VERSION "HNNBNNNYNNNNNNNNNNNNNNNNNNNNNNNNNNNNNNNNNN/4/%%%/4/'%**4NNN///"

NS_ :

BS_:

BU_: BAP_Tester Booster_AMP DSP_SKODA Gateway_PQ35 Gateway_PQ46 GSM_Pager Kompassmodul MDI Radio_2DIN Radio_Modul Radio_SKODA Rearview RNS_300_NF RNS_MFD2 RNS_midline SDARS_Tuner Sprachbedienung Standheizung Tastatur Telematik_Basis TV_hybrid UHV_High UHV_low UHV_NAR UHV_Premium UHV_UMTS

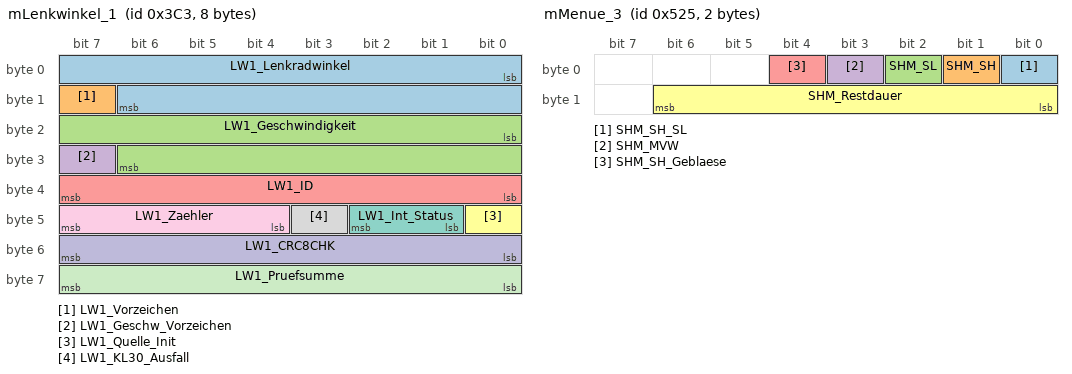
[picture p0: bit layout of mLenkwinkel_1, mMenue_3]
BO_ 963 mLenkwinkel_1: 8 Gateway_PQ35
 SG_ LW1_Lenkradwinkel : 0|15@1+ (0.04375,0) [0|1433.55625] "Unit_DegreOfArc"  Rearview
 SG_ LW1_Vorzeichen : 15|1@1+ (1,0) [0|1] ""  Rearview
 SG_ LW1_Geschwindigkeit : 16|15@1+ (0.04375,0) [0|1433.55625] "Unit_DegreOfArcPerSecond"  Rearview
 SG_ LW1_Geschw_Vorzeichen : 31|1@1+ (1,0) [0|1] ""  Rearview
 SG_ LW1_ID : 32|8@1+ (1,0) [0|255] ""  Rearview
 SG_ LW1_Quelle_Init : 40|1@1+ (1,0) [0|1] ""  Rearview
 SG_ LW1_Int_Status : 41|2@1+ (1,0) [0|3] ""  Rearview
 SG_ LW1_KL30_Ausfall : 43|1@1+ (1,0) [0|1] ""  Rearview
 SG_ LW1_Zaehler : 44|4@1+ (1,0) [0|15] ""  Rearview
 SG_ LW1_CRC8CHK : 48|8@1+ (1,0) [0|255] "" Vector__XXX
 SG_ LW1_Pruefsumme : 56|8@1+ (1,0) [0|255] ""  Rearview

BO_ 1329 mLicht_1_alt: 4 Gateway_PQ35
 SG_ LIA_Standlicht : 0|1@1+ (1,0) [0|1] "" Vector__XXX
 SG_ LIA_Abblendlicht : 1|1@1+ (1,0) [0|1] "" Vector__XXX
 SG_ LIA_Fernlicht : 2|1@1+ (1,0) [0|1] "" Vector__XXX
 SG_ LIA_Nebellicht : 3|1@1+ (1,0) [0|1] "" Vector__XXX
 SG_ LIA_Nebelschluss : 4|1@1+ (1,0) [0|1] "" Vector__XXX
 SG_ LIA_Rueckfahrlicht : 5|1@1+ (1,0) [0|1] ""  Radio_Modul,Rearview,RNS_midline
 SG_ LIA_Parklicht_links : 6|1@1+ (1,0) [0|1] "" Vector__XXX
 SG_ LIA_Parklicht_rechts : 7|1@1+ (1,0) [0|1] "" Vector__XXX
 SG_ LIA_Blk_links : 8|1@1+ (1,0) [0|1] ""  Radio_2DIN,Radio_SKODA
 SG_ LIA_Blk_rechts : 9|1@1+ (1,0) [0|1] ""  Radio_2DIN,Radio_SKODA
 SG_ LIA_Anhaenger : 10|1@1+ (1,0) [0|1] "" Vector__XXX
 SG_ LIA_Warnblink : 11|1@1+ (1,0) [0|1] "" Vector__XXX
 SG_ LIA_BLK_Frequenz : 12|1@1+ (1,0) [0|1] "" Vector__XXX
 SG_ LIA_AFL_Schalter : 13|1@1+ (1,0) [0|1] "" Vector__XXX
 SG_ LIA_Bremslicht : 14|1@1+ (1,0) [0|1] "" Vector__XXX
 SG_ LIA_Tagesfahrlicht : 15|1@1+ (1,0) [0|1] "" Vector__XXX
 SG_ LIA_Blk_L_Kontrolle : 16|1@1+ (1,0) [0|1] "" Vector__XXX
 SG_ LIA_Blk_R_Kontrolle : 17|1@1+ (1,0) [0|1] "" Vector__XXX
 SG_ LIA_Kurv_Licht : 18|1@1+ (1,0) [0|1] "" Vector__XXX
 SG_ LIA_Warnblk_Status : 19|1@1+ (1,0) [0|1] "" Vector__XXX
 SG_ LIA_Zaehler : 20|4@1+ (1,0) [0|15] "" Vector__XXX
 SG_ LIA_Pruefsumme : 24|8@1+ (1,0) [0|255] "" Vector__XXX

BO_ 705 mLSM_1: 6 Gateway_PQ35
 SG_ LS1_Blk_links : 0|1@1+ (1,0) [0|1] ""  Radio_2DIN,Radio_Modul,Rearview
 SG_ LS1_Blk_rechts : 1|1@1+ (1,0) [0|1] ""  Radio_2DIN,Radio_Modul,Rearview
 SG_ LS1_Lichthupe : 2|1@1+ (1,0) [0|1] "" Vector__XXX
 SG_ LS1_Fernlicht : 3|1@1+ (1,0) [0|1] "" Vector__XXX
 SG_ LS1_Parklicht_links : 5|1@1+ (1,0) [0|1] "" Vector__XXX
 SG_ LS1_Parklicht_rechts : 6|1@1+ (1,0) [0|1] "" Vector__XXX
 SG_ LS1_Signalhorn : 7|1@1+ (1,0) [0|1] "" Vector__XXX
 SG_ LS1_Tipwischen : 8|1@1+ (1,0) [0|1] "" Vector__XXX
 SG_ LS1_Intervall : 9|1@1+ (1,0) [0|1] "" Vector__XXX
 SG_ LS1_WischenStufe_1 : 10|1@1+ (1,0) [0|1] "" Vector__XXX
 SG_ LS1_WischenStufe_2 : 11|1@1+ (1,0) [0|1] "" Vector__XXX
 SG_ LS1_Frontwaschen : 12|1@1+ (1,0) [0|1] "" Vector__XXX
 SG_ LS1_Bew_Frontwaschen : 13|1@1+ (1,0) [0|1] "" Vector__XXX
 SG_ LS1_Heckintervall : 14|1@1+ (1,0) [0|1] "" Vector__XXX
 SG_ LS1_Heckwaschen : 15|1@1+ (1,0) [0|1] "" Vector__XXX
 SG_ LS1_Intervallstufen : 16|4@1+ (1,0) [0|15] "" Vector__XXX
 SG_ LS1_BC_Down_Cursor : 20|1@1+ (1,0) [0|1] "" Vector__XXX
 SG_ LS1_BC_Up_Cursor : 21|1@1+ (1,0) [0|1] "" Vector__XXX
 SG_ LS1_BC_Reset : 22|1@1+ (1,0) [0|1] "" Vector__XXX
 SG_ LS1_KD_Fehler : 23|1@1+ (1,0) [0|1] "" Vector__XXX
 SG_ LS1_LSY_oben : 24|1@1+ (1,0) [0|1] "" Vector__XXX
 SG_ LS1_LSY_unten : 25|1@1+ (1,0) [0|1] "" Vector__XXX
 SG_ LS1_LSZ_vor : 26|1@1+ (1,0) [0|1] "" Vector__XXX
 SG_ LS1_LSZ_zurueck : 27|1@1+ (1,0) [0|1] "" Vector__XXX
 SG_ LS1_ELV_enable : 28|1@1+ (1,0) [0|1] "" Vector__XXX
 SG_ LS1_def_ELV_Enable : 29|1@1+ (1,0) [0|1] "" Vector__XXX
 SG_ LS1_Easy_Entry_LS : 30|1@1+ (1,0) [0|1] "" Vector__XXX
 SG_ LS1_LHeizung_aktiv : 31|1@1+ (1,0) [0|1] "" Vector__XXX
 SG_ LS1_Winterstellung : 32|1@1+ (1,0) [0|1] "" Vector__XXX
 SG_ LS1_MFL_vorhanden : 33|1@1+ (1,0) [0|1] ""  Kompassmodul,Radio_2DIN,Radio_Modul,Radio_SKODA,RNS_300_NF,RNS_MFD2,RNS_midline,Sprachbedienung,Standheizung,Telematik_Basis,UHV_low,UHV_NAR,UHV_Premium,UHV_UMTS
 SG_ LS1_MFA_vorhanden : 34|1@1+ (1,0) [0|1] ""  Kompassmodul,Radio_2DIN,Radio_Modul,Radio_SKODA,RNS_300_NF,RNS_MFD2,RNS_midline,Sprachbedienung,Standheizung,Telematik_Basis,UHV_low,UHV_NAR,UHV_Premium,UHV_UMTS
 SG_ LS1_MFA_Tasten : 35|1@1+ (1,0) [0|1] ""  Sprachbedienung,Standheizung,Telematik_Basis,UHV_low,UHV_NAR,UHV_Premium,UHV_UMTS
 SG_ LS1_def_P_Verriegelt : 36|1@1+ (1,0) [0|1] "" Vector__XXX
 SG_ LS1_MFL_Typ : 37|1@1+ (1,0) [0|1] ""  Kompassmodul,Radio_2DIN,Radio_SKODA,RNS_MFD2,Standheizung,UHV_low,UHV_NAR,UHV_Premium,UHV_UMTS
 SG_ LS1_Servicestellung : 38|1@1+ (1,0) [0|1] "" Vector__XXX
 SG_ LS1_P_verriegelt : 39|1@1+ (1,0) [0|1] "" Vector__XXX
 SG_ LS1_FAS_Taster : 40|1@1+ (1,0) [0|1] "" Vector__XXX
 SG_ LS1_Fehler_FAS_Taster : 41|1@1+ (1,0) [0|1] "" Vector__XXX
 SG_ LS1_Fehler_Vibration : 42|1@1+ (1,0) [0|1] "" Vector__XXX

BO_ 1371 mMDI_1: 1 MDI
 SG_ MD1_MDI_on : 0|1@1+ (1,0) [0|1] ""  Radio_Modul,RNS_300_NF,RNS_midline
 SG_ MD1_MDI_Error_flag : 7|1@1+ (1,0) [0|1] ""  Gateway_PQ35,Gateway_PQ46

BO_ 1317 mMenue_3: 2 Gateway_PQ35
 SG_ SHM_SH_SL : 0|1@1+ (1,0) [0|1] ""  Standheizung
 SG_ SHM_SH : 1|1@1+ (1,0) [0|1] ""  Standheizung
 SG_ SHM_SL : 2|1@1+ (1,0) [0|1] ""  Standheizung
 SG_ SHM_MVW : 3|1@1+ (1,0) [0|1] ""  Standheizung
 SG_ SHM_SH_Geblaese : 4|1@1+ (1,0) [0|1] "" Vector__XXX
 SG_ SHM_Restdauer : 8|7@1+ (1,0) [0|126] "Unit_Minut"  Standheizung

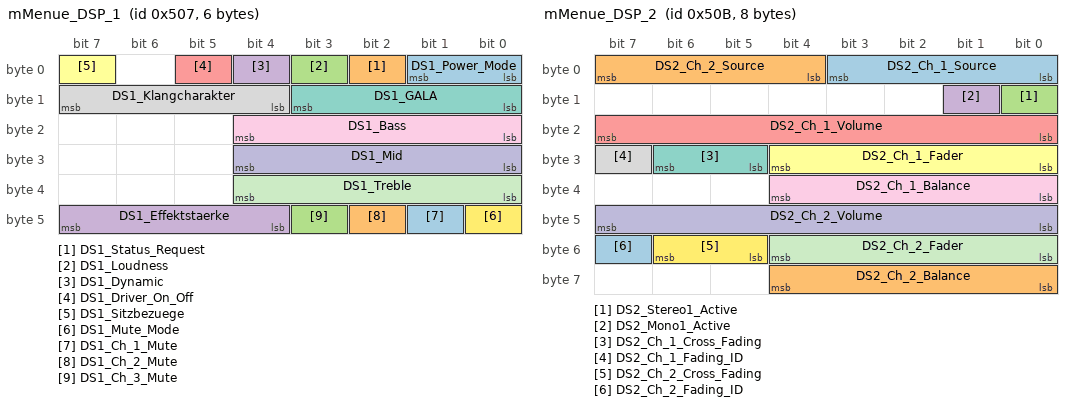
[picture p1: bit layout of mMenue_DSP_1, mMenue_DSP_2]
BO_ 1287 mMenue_DSP_1: 6 Radio_Modul
 SG_ DS1_Power_Mode : 0|2@1+ (1,0) [0|3] ""  DSP_SKODA
 SG_ DS1_Status_Request : 2|1@1+ (1,0) [0|1] ""  DSP_SKODA
 SG_ DS1_Loudness : 3|1@1+ (1,0) [0|1] ""  DSP_SKODA
 SG_ DS1_Dynamic : 4|1@1+ (1,0) [0|1] ""  DSP_SKODA
 SG_ DS1_Driver_On_Off : 5|1@1+ (1,0) [0|1] ""  DSP_SKODA
 SG_ DS1_Sitzbezuege : 7|1@1+ (1,0) [0|1] ""  DSP_SKODA
 SG_ DS1_GALA : 8|4@1+ (1,0) [0|15] ""  DSP_SKODA
 SG_ DS1_Klangcharakter : 12|4@1+ (1,0) [0|15] ""  DSP_SKODA
 SG_ DS1_Bass : 16|5@1+ (1,-16) [-15|15] ""  DSP_SKODA
 SG_ DS1_Mid : 24|5@1+ (1,-16) [-15|15] ""  DSP_SKODA
 SG_ DS1_Treble : 32|5@1+ (1,-16) [-15|15] ""  DSP_SKODA
 SG_ DS1_Mute_Mode : 40|1@1+ (1,0) [0|1] ""  DSP_SKODA
 SG_ DS1_Ch_1_Mute : 41|1@1+ (1,0) [0|1] ""  DSP_SKODA
 SG_ DS1_Ch_2_Mute : 42|1@1+ (1,0) [0|1] ""  DSP_SKODA
 SG_ DS1_Ch_3_Mute : 43|1@1+ (1,0) [0|1] ""  DSP_SKODA
 SG_ DS1_Effektstaerke : 44|4@1+ (1,0) [0|15] ""  DSP_SKODA

BO_ 1291 mMenue_DSP_2: 8 Radio_SKODA
 SG_ DS2_Ch_1_Source : 0|4@1+ (1,0) [0|15] ""  DSP_SKODA
 SG_ DS2_Ch_2_Source : 4|4@1+ (1,0) [0|15] ""  DSP_SKODA
 SG_ DS2_Stereo1_Active : 8|1@1+ (1,0) [0|1] ""  DSP_SKODA
 SG_ DS2_Mono1_Active : 9|1@1+ (1,0) [0|1] ""  DSP_SKODA
 SG_ DS2_Ch_1_Volume : 16|8@1+ (1,0) [0|255] ""  DSP_SKODA
 SG_ DS2_Ch_1_Fader : 24|5@1+ (1,-16) [-15|15] ""  DSP_SKODA
 SG_ DS2_Ch_1_Cross_Fading : 29|2@1+ (1,0) [0|3] ""  DSP_SKODA
 SG_ DS2_Ch_1_Fading_ID : 31|1@1+ (1,0) [0|1] ""  DSP_SKODA
 SG_ DS2_Ch_1_Balance : 32|5@1+ (1,-16) [-15|15] ""  DSP_SKODA
 SG_ DS2_Ch_2_Volume : 40|8@1+ (1,0) [0|255] ""  DSP_SKODA
 SG_ DS2_Ch_2_Fader : 48|5@1+ (1,-16) [-15|15] ""  DSP_SKODA
 SG_ DS2_Ch_2_Cross_Fading : 53|2@1+ (1,0) [0|3] ""  DSP_SKODA
 SG_ DS2_Ch_2_Fading_ID : 55|1@1+ (1,0) [0|1] ""  DSP_SKODA
 SG_ DS2_Ch_2_Balance : 56|5@1+ (1,-16) [-15|15] ""  DSP_SKODA

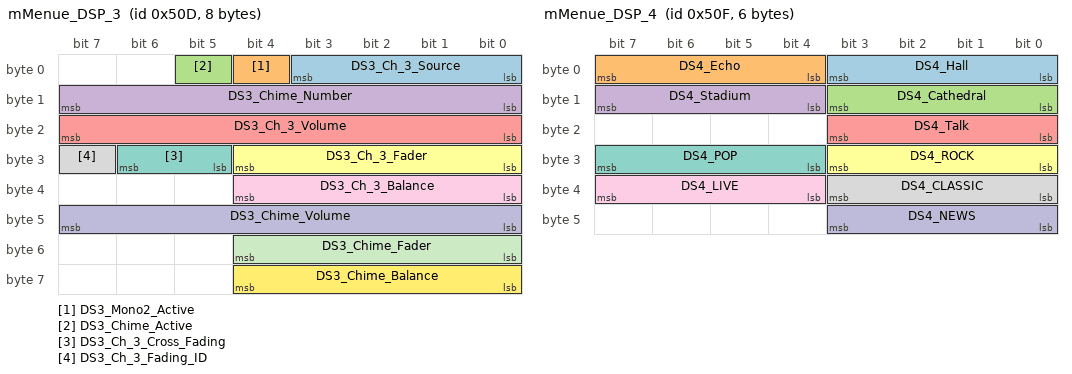
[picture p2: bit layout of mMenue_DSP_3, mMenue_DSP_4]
BO_ 1293 mMenue_DSP_3: 8 Radio_SKODA
 SG_ DS3_Ch_3_Source : 0|4@1+ (1,0) [0|15] ""  DSP_SKODA
 SG_ DS3_Mono2_Active : 4|1@1+ (1,0) [0|1] ""  DSP_SKODA
 SG_ DS3_Chime_Active : 5|1@1+ (1,0) [0|1] ""  DSP_SKODA
 SG_ DS3_Chime_Number : 8|8@1+ (1,0) [0|255] ""  DSP_SKODA
 SG_ DS3_Ch_3_Volume : 16|8@1+ (1,0) [0|255] ""  DSP_SKODA
 SG_ DS3_Ch_3_Fader : 24|5@1+ (1,-16) [-15|15] ""  DSP_SKODA
 SG_ DS3_Ch_3_Cross_Fading : 29|2@1+ (1,0) [0|3] ""  DSP_SKODA
 SG_ DS3_Ch_3_Fading_ID : 31|1@1+ (1,0) [0|1] ""  DSP_SKODA
 SG_ DS3_Ch_3_Balance : 32|5@1+ (1,-16) [-15|15] ""  DSP_SKODA
 SG_ DS3_Chime_Volume : 40|8@1+ (1,0) [0|255] ""  DSP_SKODA
 SG_ DS3_Chime_Fader : 48|5@1+ (1,-16) [-15|15] ""  DSP_SKODA
 SG_ DS3_Chime_Balance : 56|5@1+ (1,-16) [-15|15] ""  DSP_SKODA

BO_ 1295 mMenue_DSP_4: 6 Radio_SKODA
 SG_ DS4_Hall : 0|4@1+ (1,0) [0|15] ""  DSP_SKODA
 SG_ DS4_Echo : 4|4@1+ (1,0) [0|15] ""  DSP_SKODA
 SG_ DS4_Cathedral : 8|4@1+ (1,0) [0|15] ""  DSP_SKODA
 SG_ DS4_Stadium : 12|4@1+ (1,0) [0|15] ""  DSP_SKODA
 SG_ DS4_Talk : 16|4@1+ (1,0) [0|15] ""  DSP_SKODA
 SG_ DS4_ROCK : 24|4@1+ (1,0) [0|15] ""  DSP_SKODA
 SG_ DS4_POP : 28|4@1+ (1,0) [0|15] ""  DSP_SKODA
 SG_ DS4_CLASSIC : 32|4@1+ (1,0) [0|15] ""  DSP_SKODA
 SG_ DS4_LIVE : 36|4@1+ (1,0) [0|15] ""  DSP_SKODA
 SG_ DS4_NEWS : 40|4@1+ (1,0) [0|15] ""  DSP_SKODA

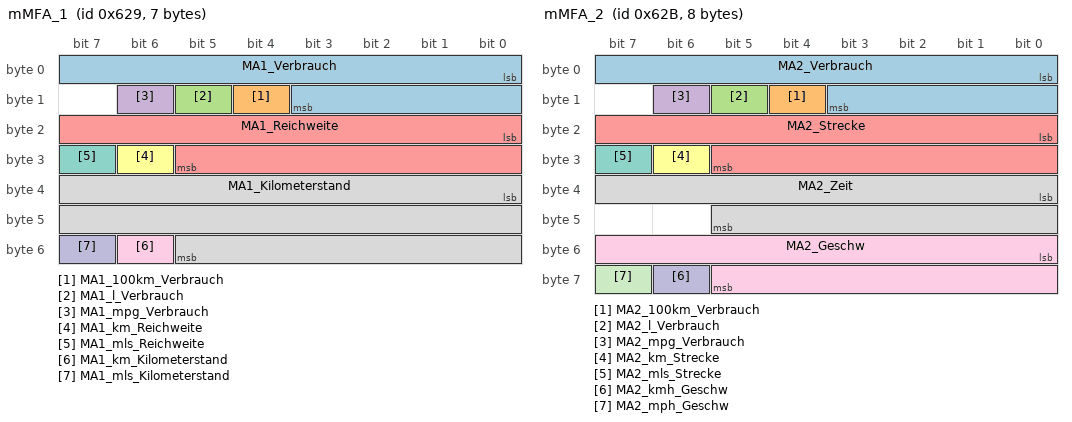
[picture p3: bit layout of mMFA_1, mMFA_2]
BO_ 1577 mMFA_1: 7 Gateway_PQ35
 SG_ MA1_Verbrauch : 0|12@1+ (0.1,0) [0|409.4] ""  RNS_midline
 SG_ MA1_100km_Verbrauch : 12|1@1+ (1,0) [0|1] ""  RNS_midline
 SG_ MA1_l_Verbrauch : 13|1@1+ (1,0) [0|1] ""  RNS_midline
 SG_ MA1_mpg_Verbrauch : 14|1@1+ (1,0) [0|1] ""  RNS_midline
 SG_ MA1_Reichweite : 16|14@1+ (1,0) [0|16382] ""  RNS_midline
 SG_ MA1_km_Reichweite : 30|1@1+ (1,0) [0|1] ""  RNS_midline
 SG_ MA1_mls_Reichweite : 31|1@1+ (1,0) [0|1] ""  RNS_midline
 SG_ MA1_Kilometerstand : 32|22@1+ (1,0) [0|4194303] ""  RNS_midline
 SG_ MA1_km_Kilometerstand : 54|1@1+ (1,0) [0|1] ""  RNS_midline
 SG_ MA1_mls_Kilometerstand : 55|1@1+ (1,0) [0|1] ""  RNS_midline

BO_ 1579 mMFA_2: 8 Gateway_PQ35
 SG_ MA2_Verbrauch : 0|12@1+ (0.1,0) [0|409.4] ""  RNS_midline
 SG_ MA2_100km_Verbrauch : 12|1@1+ (1,0) [0|1] ""  RNS_midline
 SG_ MA2_l_Verbrauch : 13|1@1+ (1,0) [0|1] ""  RNS_midline
 SG_ MA2_mpg_Verbrauch : 14|1@1+ (1,0) [0|1] ""  RNS_midline
 SG_ MA2_Strecke : 16|14@1+ (1,0) [0|16382] ""  RNS_midline
 SG_ MA2_km_Strecke : 30|1@1+ (1,0) [0|1] ""  RNS_midline
 SG_ MA2_mls_Strecke : 31|1@1+ (1,0) [0|1] ""  RNS_midline
 SG_ MA2_Zeit : 32|14@1+ (1,0) [0|16382] "Unit_Minut"  RNS_midline
 SG_ MA2_Geschw : 48|14@1+ (1,0) [0|16382] ""  RNS_midline
 SG_ MA2_kmh_Geschw : 62|1@1+ (1,0) [0|1] ""  RNS_midline
 SG_ MA2_mph_Geschw : 63|1@1+ (1,0) [0|1] ""  RNS_midline

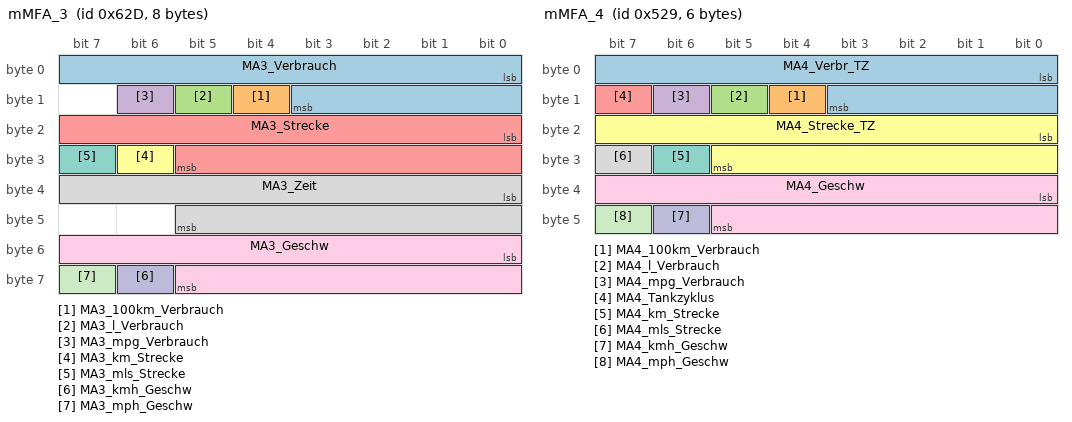
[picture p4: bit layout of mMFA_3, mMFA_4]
BO_ 1581 mMFA_3: 8 Gateway_PQ35
 SG_ MA3_Verbrauch : 0|12@1+ (0.1,0) [0|409.4] ""  RNS_midline
 SG_ MA3_100km_Verbrauch : 12|1@1+ (1,0) [0|1] ""  RNS_midline
 SG_ MA3_l_Verbrauch : 13|1@1+ (1,0) [0|1] ""  RNS_midline
 SG_ MA3_mpg_Verbrauch : 14|1@1+ (1,0) [0|1] ""  RNS_midline
 SG_ MA3_Strecke : 16|14@1+ (1,0) [0|16382] ""  RNS_midline
 SG_ MA3_km_Strecke : 30|1@1+ (1,0) [0|1] ""  RNS_midline
 SG_ MA3_mls_Strecke : 31|1@1+ (1,0) [0|1] ""  RNS_midline
 SG_ MA3_Zeit : 32|14@1+ (1,0) [0|16382] "Unit_Minut"  RNS_midline
 SG_ MA3_Geschw : 48|14@1+ (1,0) [0|16382] ""  RNS_midline
 SG_ MA3_kmh_Geschw : 62|1@1+ (1,0) [0|1] ""  RNS_midline
 SG_ MA3_mph_Geschw : 63|1@1+ (1,0) [0|1] ""  RNS_midline

BO_ 1321 mMFA_4: 6 Gateway_PQ35
 SG_ MA4_Verbr_TZ : 0|12@1+ (0.1,0) [0|409.4] ""  RNS_midline
 SG_ MA4_100km_Verbrauch : 12|1@1+ (1,0) [0|1] ""  RNS_midline
 SG_ MA4_l_Verbrauch : 13|1@1+ (1,0) [0|1] ""  RNS_midline
 SG_ MA4_mpg_Verbrauch : 14|1@1+ (1,0) [0|1] ""  RNS_midline
 SG_ MA4_Tankzyklus : 15|1@1+ (1,0) [0|1] ""  RNS_midline
 SG_ MA4_Strecke_TZ : 16|14@1+ (1,0) [0|16382] ""  RNS_midline
 SG_ MA4_km_Strecke : 30|1@1+ (1,0) [0|1] ""  RNS_midline
 SG_ MA4_mls_Strecke : 31|1@1+ (1,0) [0|1] ""  RNS_midline
 SG_ MA4_Geschw : 32|14@1+ (1,0) [0|16382] ""  RNS_midline
 SG_ MA4_kmh_Geschw : 46|1@1+ (1,0) [0|1] ""  RNS_midline
 SG_ MA4_mph_Geschw : 47|1@1+ (1,0) [0|1] ""  RNS_midline

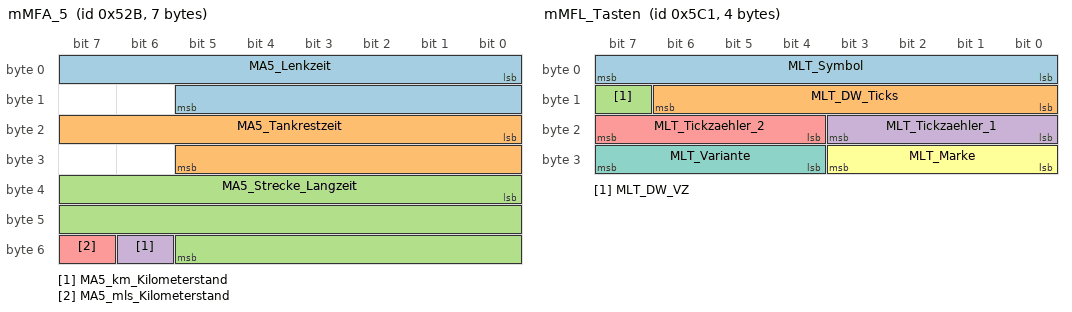
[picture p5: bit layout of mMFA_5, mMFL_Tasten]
BO_ 1323 mMFA_5: 7 Gateway_PQ35
 SG_ MA5_Lenkzeit : 0|14@1+ (1,0) [0|16382] ""  RNS_midline
 SG_ MA5_Tankrestzeit : 16|14@1+ (1,0) [0|16382] ""  RNS_midline
 SG_ MA5_Strecke_Langzeit : 32|22@1+ (1,0) [0|4194302] ""  RNS_midline
 SG_ MA5_km_Kilometerstand : 54|1@1+ (1,0) [0|1] ""  RNS_midline
 SG_ MA5_mls_Kilometerstand : 55|1@1+ (1,0) [0|1] ""  RNS_midline

BO_ 1475 mMFL_Cmd_: 2 Gateway_PQ35
 SG_ ML1_Ziel_ : 0|8@1+ (1,0) [0|255] "" Vector__XXX
 SG_ ML1_Befehl_ : 8|8@1+ (1,0) [0|255] "" Vector__XXX

BO_ 1473 mMFL_Tasten: 4 Gateway_PQ46
 SG_ MLT_Symbol : 0|8@1+ (1,0) [0|255] ""  Kompassmodul,Radio_2DIN,Radio_Modul,Radio_SKODA,RNS_300_NF,RNS_MFD2,RNS_midline,Sprachbedienung,Standheizung,Telematik_Basis,UHV_High,UHV_low,UHV_NAR,UHV_Premium,UHV_UMTS
 SG_ MLT_DW_Ticks : 8|7@1+ (1,0) [0|127] "" Vector__XXX
 SG_ MLT_DW_VZ : 15|1@1+ (1,0) [0|1] "" Vector__XXX
 SG_ MLT_Tickzaehler_1 : 16|4@1+ (1,0) [0|15] ""  Radio_Modul,RNS_300_NF,RNS_midline,UHV_High,UHV_low,UHV_NAR,UHV_Premium,UHV_UMTS
 SG_ MLT_Tickzaehler_2 : 20|4@1+ (1,0) [0|15] "" Vector__XXX
 SG_ MLT_Marke : 24|4@1+ (1,0) [0|15] ""  Radio_Modul,RNS_300_NF,RNS_midline,UHV_low,UHV_NAR,UHV_Premium,UHV_UMTS
 SG_ MLT_Variante : 28|4@1+ (1,0) [0|15] ""  Radio_Modul,RNS_300_NF,RNS_midline,UHV_low,UHV_NAR,UHV_Premium,UHV_UMTS

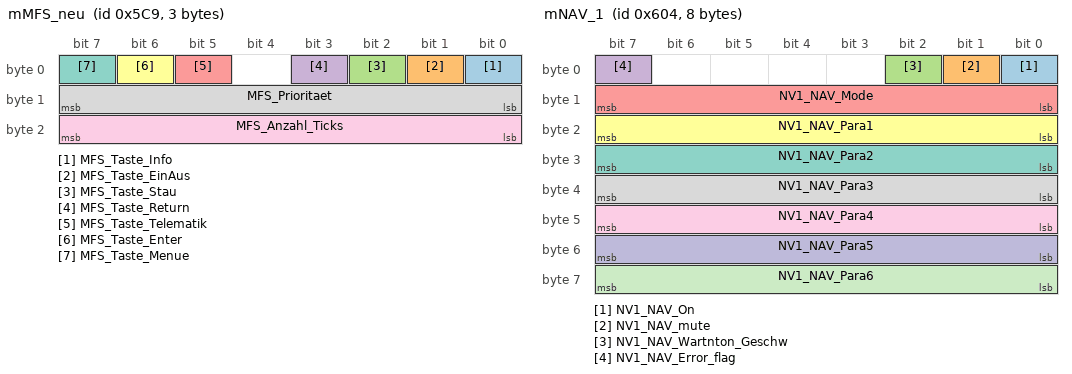
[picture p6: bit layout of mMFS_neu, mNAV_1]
BO_ 1481 mMFS_neu: 3 Gateway_PQ35
 SG_ MFS_Taste_Info : 0|1@1+ (1,0) [0|1] "" Vector__XXX
 SG_ MFS_Taste_EinAus : 1|1@1+ (1,0) [0|1] "" Vector__XXX
 SG_ MFS_Taste_Stau : 2|1@1+ (1,0) [0|1] "" Vector__XXX
 SG_ MFS_Taste_Return : 3|1@1+ (1,0) [0|1] "" Vector__XXX
 SG_ MFS_Taste_Telematik : 5|1@1+ (1,0) [0|1] "" Vector__XXX
 SG_ MFS_Taste_Enter : 6|1@1+ (1,0) [0|1] "" Vector__XXX
 SG_ MFS_Taste_Menue : 7|1@1+ (1,0) [0|1] "" Vector__XXX
 SG_ MFS_Prioritaet : 8|8@1+ (1,0) [0|255] "" Vector__XXX
 SG_ MFS_Anzahl_Ticks : 16|8@1+ (1,-128) [-128|127] "" Vector__XXX

BO_ 1365 mMotor7: 8 Gateway_PQ35
 SG_ MO7_LL_Status : 0|1@1+ (1,0) [0|1] "" Vector__XXX
 SG_ MO7_V_Begrenz : 1|1@1+ (1,0) [0|1] "" Vector__XXX
 SG_ MO7_V_Begr_akt : 2|1@1+ (1,0) [0|1] "" Vector__XXX
 SG_ MO7_FehlerSp : 3|1@1+ (1,0) [0|1] "" Vector__XXX
 SG_ MO7_Fehler_Oel_Temp : 4|1@1+ (1,0) [0|1] ""  Telematik_Basis
 SG_ MO7_PTC : 5|3@1+ (1,0) [0|7] "" Vector__XXX
 SG_ MO7_DFM : 8|8@1+ (0.4,0) [0|101.6] "Unit_PerCent" Vector__XXX
 SG_ MO7_Hoeheninfo : 16|8@1+ (0.0078125,0) [0|1.984375] ""  Standheizung,Telematik_Basis
 SG_ MO7_Gradient_Drehz : 24|7@1+ (1,0) [0|126] "Unit_MinutInver" Vector__XXX
 SG_ MO7_Gradient_Vorz : 31|1@1+ (1,0) [0|1] "" Vector__XXX
 SG_ MO7_Ladedruckneu : 32|8@1+ (0.02,0) [0|5.08] "Unit_Bar" Vector__XXX
 SG_ MO7_GenLoadResp : 40|2@1+ (3,0) [0|9] "Unit_Secon" Vector__XXX
 SG_ MO7_PTC_bereit : 42|2@1+ (1,0) [0|3] "" Vector__XXX
 SG_ MO7_Mot_weckfaehig : 44|1@1+ (1,0) [0|1] "" Vector__XXX
 SG_ MO7_Zus_Kuehl : 45|1@1+ (1,0) [0|1] "" Vector__XXX
 SG_ MO7_Sleep_Ind : 46|1@1+ (1,0) [0|1] "" Vector__XXX
 SG_ MO7_Rueck_LLDz : 47|1@1+ (1,0) [0|1] "" Vector__XXX
 SG_ MO7_Last_abwurf : 48|2@1+ (1,0) [0|3] "" Vector__XXX
 SG_ MO7_Ein_Generator : 50|1@1+ (1,0) [0|1] "" Vector__XXX
 SG_ MO7_Lastabwurf_Heiz : 51|1@1+ (1,0) [0|1] "" Vector__XXX
 SG_ MO7_Stat_Gluehk : 52|4@1+ (8,0) [0|112] "Unit_PerCent" Vector__XXX
 SG_ MO7_Oeltemperatur : 56|8@1+ (1,-60) [-58|194] "Unit_DegreCelsi"  Telematik_Basis

BO_ 1420 mMotor_10: 8 Gateway_PQ35
 SG_ M10_Anzeige : 0|4@1+ (1,0) [0|15] "" Vector__XXX
 SG_ M10_Anf_Kl75 : 4|1@1+ (1,0) [0|1] "" Vector__XXX
 SG_ MSG_Remotestart_Betrieb : 5|1@1+ (1,0) [0|1] "" Vector__XXX
 SG_ M10_SpannungsAnf : 6|1@1+ (1,0) [0|1] "" Vector__XXX
 SG_ M10_UDruckDyn : 7|1@1+ (1,0) [0|1] "" Vector__XXX
 SG_ M10_Status_StSt : 8|2@1+ (1,0) [0|3] ""  Standheizung
 SG_ M10_MotorStopp : 10|1@1+ (1,0) [0|1] ""  Standheizung
 SG_ M10_Wiederstart : 11|1@1+ (1,0) [0|1] ""  Booster_AMP,Standheizung
 SG_ M10_Schubabschaltung : 12|1@1+ (1,0) [0|1] "" Vector__XXX
 SG_ M10_Druck_err_gem : 13|1@1+ (1,0) [0|1] "" Vector__XXX
 SG_ M10_Freigabe_Reku : 14|2@1+ (1,0) [0|3] "" Vector__XXX
 SG_ M10_rel_Saugrohrdruck : 16|6@1+ (18,0) [0|1116] "Unit_MilliBar" Vector__XXX
 SG_ M10_Fahrbereitschaft : 22|1@1+ (1,0) [0|1] "" Vector__XXX
 SG_ M10_Hybrid : 23|1@1+ (1,0) [0|1] "" Vector__XXX
 SG_ M10_EM_aktiv : 24|1@1+ (1,0) [0|1] "" Vector__XXX
 SG_ M10_VM_aktiv : 25|1@1+ (1,0) [0|1] "" Vector__XXX
 SG_ M10_HYB_Bereitlampe : 26|1@1+ (1,0) [0|1] "" Vector__XXX
 SG_ M10_HYB_Warnlampe : 27|1@1+ (1,0) [0|1] "" Vector__XXX
 SG_ M10_HYB_Fehlerlampe : 28|1@1+ (1,0) [0|1] "" Vector__XXX
 SG_ M10_Fehler_HV_Netz : 29|1@1+ (1,0) [0|1] "" Vector__XXX
 SG_ M10_EKlKomLeiRed : 30|2@1+ (1,0) [0|3] "" Vector__XXX
 SG_ M10_Klimadruck : 32|8@1+ (0.2,0) [0|37] "Unit_Bar" Vector__XXX
 SG_ M10_KompAusCode : 40|4@1+ (1,0) [0|15] "" Vector__XXX
 SG_ M10_StartStopp_Fahrerwunsch : 44|2@1+ (1,0) [0|3] "" Vector__XXX
 SG_ M10_Akustik : 46|2@1+ (1,0) [0|3] "" Vector__XXX
 SG_ M10_Text_1_Hybrid : 48|1@1+ (1,0) [0|1] "" Vector__XXX
 SG_ M10_Text_2_Hybrid : 49|1@1+ (1,0) [0|1] "" Vector__XXX
 SG_ M10_Text_3_Hybrid : 50|1@1+ (1,0) [0|1] "" Vector__XXX
 SG_ M10_Text_4_Hybrid : 51|1@1+ (1,0) [0|1] "" Vector__XXX
 SG_ M10_Text_5_Hybrid : 52|1@1+ (1,0) [0|1] "" Vector__XXX
 SG_ M10_Text_6_Hybrid : 53|1@1+ (1,0) [0|1] "" Vector__XXX
 SG_ M10_Text_7_Hybrid : 54|1@1+ (1,0) [0|1] "" Vector__XXX
 SG_ M10_Text_8_Hybrid : 55|1@1+ (1,0) [0|1] "" Vector__XXX
 SG_ M10_ShiftLockLampe : 56|1@1+ (1,0) [0|1] "" Vector__XXX
 SG_ M10_BMSInfo_gue : 58|1@1+ (1,0) [0|1] "" Vector__XXX
 SG_ M10_VentilationReq : 59|1@1+ (1,0) [0|1] "" Vector__XXX
 SG_ M10_BattFanSpd : 60|4@1+ (10,0) [0|100] "Unit_PerCent" Vector__XXX

BO_ 1540 mNAV_1: 8 RNS_300_NF
 SG_ NV1_NAV_On : 0|1@1+ (1,0) [0|1] ""  Gateway_PQ35,Gateway_PQ46,Telematik_Basis
 SG_ NV1_NAV_mute : 1|1@1+ (1,0) [0|1] ""  Gateway_PQ35,Gateway_PQ46
 SG_ NV1_NAV_Wartnton_Geschw : 2|1@1+ (1,0) [0|1] ""  Gateway_PQ35,Gateway_PQ46
 SG_ NV1_NAV_Error_flag : 7|1@1+ (1,0) [0|1] ""  Gateway_PQ35,Gateway_PQ46
 SG_ NV1_NAV_Mode : 8|8@1+ (1,0) [0|255] ""  Gateway_PQ35,Gateway_PQ46
 SG_ NV1_NAV_Para1 : 16|8@1+ (1,0) [0|255] ""  Gateway_PQ35,Gateway_PQ46
 SG_ NV1_NAV_Para2 : 24|8@1+ (1,0) [0|255] ""  Gateway_PQ35,Gateway_PQ46
 SG_ NV1_NAV_Para3 : 32|8@1+ (1,0) [0|255] ""  Gateway_PQ35,Gateway_PQ46
 SG_ NV1_NAV_Para4 : 40|8@1+ (1,0) [0|255] ""  Gateway_PQ35,Gateway_PQ46
 SG_ NV1_NAV_Para5 : 48|8@1+ (1,0) [0|255] ""  Gateway_PQ35,Gateway_PQ46
 SG_ NV1_NAV_Para6 : 56|8@1+ (1,0) [0|255] ""  Gateway_PQ35,Gateway_PQ46

BO_ 1441 mNAVDATA: 8 RNS_300_NF
 SG_ ND_Init : 0|1@1+ (1,0) [0|1] ""  Gateway_PQ35,Gateway_PQ46,Telematik_Basis
 SG_ ND_ErrorTime : 1|1@1+ (1,0) [0|1] ""  Gateway_PQ35,Gateway_PQ46,Telematik_Basis
 SG_ ND_ErrorDate : 2|1@1+ (1,0) [0|1] ""  Gateway_PQ35,Gateway_PQ46,Telematik_Basis
 SG_ ND_ErrorRestentf : 3|1@1+ (1,0) [0|1] ""  Gateway_PQ35,Gateway_PQ46,Telematik_Basis
 SG_ ND_ErrorHeading : 4|1@1+ (1,0) [0|1] ""  Gateway_PQ35,Gateway_PQ46,Telematik_Basis
 SG_ ND_ErrorSpeed : 5|1@1+ (1,0) [0|1] ""  Gateway_PQ35,Gateway_PQ46,Telematik_Basis
 SG_ ND_KM : 6|1@1+ (1,0) [0|1] ""  Gateway_PQ35,Gateway_PQ46,Telematik_Basis
 SG_ ND_AMPM : 7|1@1+ (1,0) [0|1] ""  Gateway_PQ35,Gateway_PQ46,Telematik_Basis
 SG_ ND_Stunde : 8|4@1+ (1,0) [0|12] ""  Gateway_PQ35,Gateway_PQ46,Telematik_Basis
 SG_ ND_Minuten : 12|6@1+ (1,0) [0|59] ""  Gateway_PQ35,Gateway_PQ46,Telematik_Basis
 SG_ ND_Sekunden : 18|6@1+ (1,0) [0|59] ""  Gateway_PQ35,Gateway_PQ46
 SG_ ND_Year : 24|7@1+ (1,0) [0|99] ""  Gateway_PQ35,Gateway_PQ46,Telematik_Basis
 SG_ ND_Month : 31|4@1+ (1,0) [1|12] ""  Gateway_PQ35,Gateway_PQ46,Telematik_Basis
 SG_ ND_Day : 35|5@1+ (1,0) [1|31] ""  Gateway_PQ35,Gateway_PQ46,Telematik_Basis
 SG_ ND_Restentfernug : 40|7@1+ (1,0) [1|127] ""  Gateway_PQ35,Gateway_PQ46,Telematik_Basis
 SG_ ND_Heading : 47|9@1+ (1,0) [0|359] "Unit_DegreOfArc"  Gateway_PQ35,Gateway_PQ46,Telematik_Basis
 SG_ ND_Speed : 56|8@1+ (1,0) [0|255] "Unit_KiloMeterPerHour"  Gateway_PQ35,Gateway_PQ46,Telematik_Basis

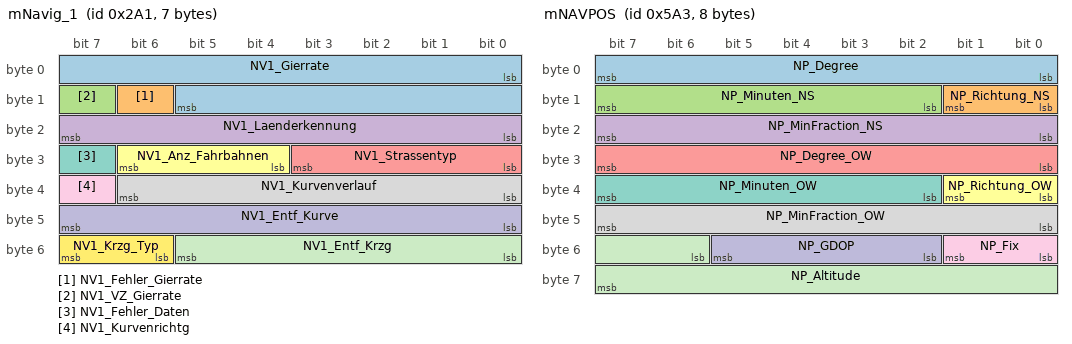
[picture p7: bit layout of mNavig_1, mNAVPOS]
BO_ 673 mNavig_1: 7 RNS_300_NF
 SG_ NV1_Gierrate : 0|14@1+ (0.01,0) [0|100] "Unit_DegreOfArcPerSecond" Vector__XXX
 SG_ NV1_Fehler_Gierrate : 14|1@1+ (1,0) [0|1] "" Vector__XXX
 SG_ NV1_VZ_Gierrate : 15|1@1+ (1,0) [0|1] "" Vector__XXX
 SG_ NV1_Laenderkennung : 16|8@1+ (1,0) [0|255] "" Vector__XXX
 SG_ NV1_Strassentyp : 24|4@1+ (1,0) [0|15] "" Vector__XXX
 SG_ NV1_Anz_Fahrbahnen : 28|3@1+ (1,0) [1|7] "" Vector__XXX
 SG_ NV1_Fehler_Daten : 31|1@1+ (1,0) [0|1] "" Vector__XXX
 SG_ NV1_Kurvenverlauf : 32|7@1+ (50,0) [0|6350] "Unit_Meter" Vector__XXX
 SG_ NV1_Kurvenrichtg : 39|1@1+ (1,0) [0|1] "" Vector__XXX
 SG_ NV1_Entf_Kurve : 40|8@1+ (1,0) [0|255] "Unit_Meter" Vector__XXX
 SG_ NV1_Entf_Krzg : 48|6@1+ (5,0) [0|315] "Unit_Meter" Vector__XXX
 SG_ NV1_Krzg_Typ : 54|2@1+ (1,0) [0|3] "" Vector__XXX

BO_ 1455 mNavig_2: 5 RNS_300_NF
 SG_ NV2_Reststrecke : 0|24@1+ (1,0) [0|16777215] "Unit_Meter" Vector__XXX
 SG_ NV2_Restzeit : 24|16@1+ (1,0) [0|65535] "Unit_Minut" Vector__XXX

BO_ 1443 mNAVPOS: 8 RNS_300_NF
 SG_ NP_Degree : 0|8@1+ (1,0) [0|90] ""  Gateway_PQ35,Gateway_PQ46,Telematik_Basis
 SG_ NP_Richtung_NS : 8|2@1+ (1,0) [0|3] ""  Gateway_PQ35,Gateway_PQ46,Telematik_Basis
 SG_ NP_Minuten_NS : 10|6@1+ (1,0) [0|59] ""  Gateway_PQ35,Gateway_PQ46,Telematik_Basis
 SG_ NP_MinFraction_NS : 16|8@1+ (1,0) [0|99] ""  Gateway_PQ35,Gateway_PQ46,Telematik_Basis
 SG_ NP_Degree_OW : 24|8@1+ (1,0) [0|180] ""  Gateway_PQ35,Gateway_PQ46,Telematik_Basis
 SG_ NP_Richtung_OW : 32|2@1+ (1,0) [0|3] ""  Gateway_PQ35,Gateway_PQ46,Telematik_Basis
 SG_ NP_Minuten_OW : 34|6@1+ (1,0) [0|59] ""  Gateway_PQ35,Gateway_PQ46,Telematik_Basis
 SG_ NP_MinFraction_OW : 40|8@1+ (1,0) [0|99] ""  Gateway_PQ35,Gateway_PQ46,Telematik_Basis
 SG_ NP_Fix : 48|2@1+ (1,0) [0|3] ""  Gateway_PQ35,Gateway_PQ46,Telematik_Basis
 SG_ NP_GDOP : 50|4@1+ (0.2,1) [1|4] ""  Gateway_PQ35,Gateway_PQ46,Telematik_Basis
 SG_ NP_Altitude : 54|10@1+ (10,-230) [-230|10000] "Unit_Meter"  Gateway_PQ35,Gateway_PQ46,Telematik_Basis

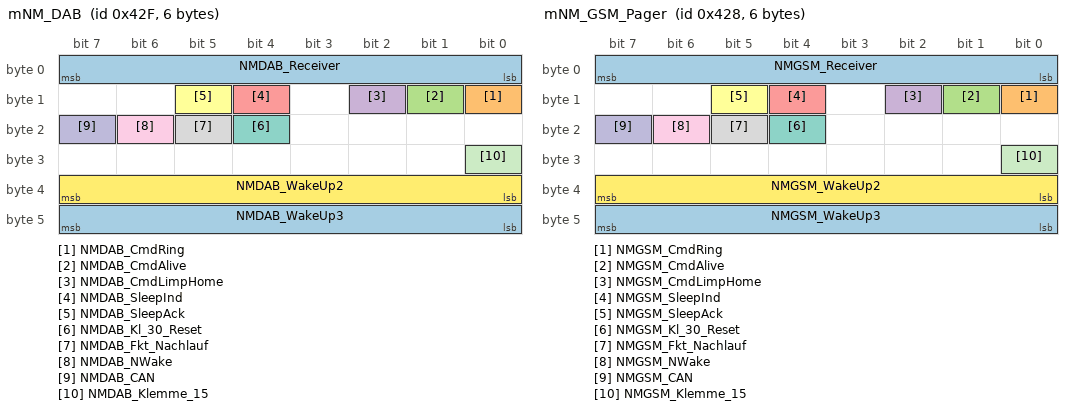
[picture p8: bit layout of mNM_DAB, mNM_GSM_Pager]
BO_ 1071 mNM_DAB: 6 SDARS_Tuner
 SG_ NMDAB_Receiver : 0|8@1+ (1,0) [0|255] ""  Booster_AMP,DSP_SKODA,Gateway_PQ35,Gateway_PQ46,GSM_Pager,Kompassmodul,MDI,Radio_2DIN,Radio_Modul,Radio_SKODA,Rearview,RNS_300_NF,RNS_MFD2,RNS_midline,SDARS_Tuner,Sprachbedienung,Standheizung,Tastatur,Telematik_Basis,TV_hybrid,UHV_High,UHV_low,UHV_NAR,UHV_Premium,UHV_UMTS
 SG_ NMDAB_CmdRing : 8|1@1+ (1,0) [0|1] ""  Booster_AMP,DSP_SKODA,Gateway_PQ35,Gateway_PQ46,GSM_Pager,Kompassmodul,MDI,Radio_2DIN,Radio_Modul,Radio_SKODA,Rearview,RNS_300_NF,RNS_MFD2,RNS_midline,SDARS_Tuner,Sprachbedienung,Standheizung,Tastatur,Telematik_Basis,TV_hybrid,UHV_High,UHV_low,UHV_NAR,UHV_Premium,UHV_UMTS
 SG_ NMDAB_CmdAlive : 9|1@1+ (1,0) [0|1] ""  Booster_AMP,DSP_SKODA,Gateway_PQ35,Gateway_PQ46,GSM_Pager,Kompassmodul,MDI,Radio_2DIN,Radio_Modul,Radio_SKODA,Rearview,RNS_300_NF,RNS_MFD2,RNS_midline,SDARS_Tuner,Sprachbedienung,Standheizung,Tastatur,Telematik_Basis,TV_hybrid,UHV_High,UHV_low,UHV_NAR,UHV_Premium,UHV_UMTS
 SG_ NMDAB_CmdLimpHome : 10|1@1+ (1,0) [0|1] ""  Booster_AMP,DSP_SKODA,Gateway_PQ35,Gateway_PQ46,GSM_Pager,Kompassmodul,MDI,Radio_2DIN,Radio_Modul,Radio_SKODA,Rearview,RNS_300_NF,RNS_MFD2,RNS_midline,SDARS_Tuner,Sprachbedienung,Standheizung,Tastatur,Telematik_Basis,TV_hybrid,UHV_High,UHV_low,UHV_NAR,UHV_Premium,UHV_UMTS
 SG_ NMDAB_SleepInd : 12|1@1+ (1,0) [0|1] ""  Booster_AMP,DSP_SKODA,Gateway_PQ35,Gateway_PQ46,GSM_Pager,Kompassmodul,MDI,Radio_2DIN,Radio_Modul,Radio_SKODA,Rearview,RNS_300_NF,RNS_MFD2,RNS_midline,SDARS_Tuner,Sprachbedienung,Standheizung,Tastatur,Telematik_Basis,TV_hybrid,UHV_High,UHV_low,UHV_NAR,UHV_Premium,UHV_UMTS
 SG_ NMDAB_SleepAck : 13|1@1+ (1,0) [0|1] ""  Booster_AMP,DSP_SKODA,Gateway_PQ35,Gateway_PQ46,GSM_Pager,Kompassmodul,MDI,Radio_2DIN,Radio_Modul,Radio_SKODA,Rearview,RNS_300_NF,RNS_MFD2,RNS_midline,SDARS_Tuner,Sprachbedienung,Standheizung,Tastatur,Telematik_Basis,TV_hybrid,UHV_High,UHV_low,UHV_NAR,UHV_Premium,UHV_UMTS
 SG_ NMDAB_Kl_30_Reset : 20|1@1+ (1,0) [0|1] "" Vector__XXX
 SG_ NMDAB_Fkt_Nachlauf : 21|1@1+ (1,0) [0|1] "" Vector__XXX
 SG_ NMDAB_NWake : 22|1@1+ (1,0) [0|1] "" Vector__XXX
 SG_ NMDAB_CAN : 23|1@1+ (1,0) [0|1] "" Vector__XXX
 SG_ NMDAB_Klemme_15 : 24|1@1+ (1,0) [0|1] "" Vector__XXX
 SG_ NMDAB_WakeUp2 : 32|8@1+ (1,0) [0|255] "" Vector__XXX
 SG_ NMDAB_WakeUp3 : 40|8@1+ (1,0) [0|255] "" Vector__XXX

BO_ 1067 mNM_Gateway_I: 6 Gateway_PQ35
 SG_ NMGW_I_Receiver : 0|8@1+ (1,0) [0|255] ""  Booster_AMP,DSP_SKODA,Gateway_PQ35,Gateway_PQ46,GSM_Pager,Kompassmodul,MDI,Radio_2DIN,Radio_Modul,Radio_SKODA,Rearview,RNS_300_NF,RNS_MFD2,RNS_midline,SDARS_Tuner,Sprachbedienung,Standheizung,Tastatur,Telematik_Basis,TV_hybrid,UHV_High,UHV_low,UHV_NAR,UHV_Premium,UHV_UMTS
 SG_ NMGW_I_CmdRing : 8|1@1+ (1,0) [0|1] ""  Booster_AMP,DSP_SKODA,Gateway_PQ35,Gateway_PQ46,GSM_Pager,Kompassmodul,MDI,Radio_2DIN,Radio_Modul,Radio_SKODA,Rearview,RNS_300_NF,RNS_MFD2,RNS_midline,SDARS_Tuner,Sprachbedienung,Standheizung,Tastatur,Telematik_Basis,TV_hybrid,UHV_High,UHV_low,UHV_NAR,UHV_Premium,UHV_UMTS
 SG_ NMGW_I_CmdAlive : 9|1@1+ (1,0) [0|1] ""  Booster_AMP,DSP_SKODA,Gateway_PQ35,Gateway_PQ46,GSM_Pager,Kompassmodul,MDI,Radio_2DIN,Radio_Modul,Radio_SKODA,Rearview,RNS_300_NF,RNS_MFD2,RNS_midline,SDARS_Tuner,Sprachbedienung,Standheizung,Tastatur,Telematik_Basis,TV_hybrid,UHV_High,UHV_low,UHV_NAR,UHV_Premium,UHV_UMTS
 SG_ NMGW_I_CmdLimpHome : 10|1@1+ (1,0) [0|1] ""  Booster_AMP,DSP_SKODA,Gateway_PQ35,Gateway_PQ46,GSM_Pager,Kompassmodul,MDI,Radio_2DIN,Radio_Modul,Radio_SKODA,Rearview,RNS_300_NF,RNS_MFD2,RNS_midline,SDARS_Tuner,Sprachbedienung,Standheizung,Tastatur,Telematik_Basis,TV_hybrid,UHV_High,UHV_low,UHV_NAR,UHV_Premium,UHV_UMTS
 SG_ NMGW_I_SleepInd : 12|1@1+ (1,0) [0|1] ""  Booster_AMP,DSP_SKODA,Gateway_PQ35,Gateway_PQ46,GSM_Pager,Kompassmodul,MDI,Radio_2DIN,Radio_Modul,Radio_SKODA,Rearview,RNS_300_NF,RNS_MFD2,RNS_midline,SDARS_Tuner,Sprachbedienung,Standheizung,Tastatur,Telematik_Basis,TV_hybrid,UHV_High,UHV_low,UHV_NAR,UHV_Premium,UHV_UMTS
 SG_ NMGW_I_SleepAck : 13|1@1+ (1,0) [0|1] ""  Booster_AMP,DSP_SKODA,Gateway_PQ35,Gateway_PQ46,GSM_Pager,Kompassmodul,MDI,Radio_2DIN,Radio_Modul,Radio_SKODA,Rearview,RNS_300_NF,RNS_MFD2,RNS_midline,SDARS_Tuner,Sprachbedienung,Standheizung,Tastatur,Telematik_Basis,TV_hybrid,UHV_High,UHV_low,UHV_NAR,UHV_Premium,UHV_UMTS
 SG_ NMGW_I_Kl_30_Reset : 20|1@1+ (1,0) [0|1] "" Vector__XXX
 SG_ NMGW_I_Fkt_Nachlauf : 21|1@1+ (1,0) [0|1] "" Vector__XXX
 SG_ NMGW_I_NWake : 22|1@1+ (1,0) [0|1] "" Vector__XXX
 SG_ NMGW_I_CAN : 23|1@1+ (1,0) [0|1] "" Vector__XXX
 SG_ NMGW_I_Wake_Up_Ltg : 24|1@1+ (1,0) [0|1] "" Vector__XXX
 SG_ NMGW_I_Komfort_CAN : 25|1@1+ (1,0) [0|1] "" Vector__XXX
 SG_ NMGW_I_Info_CAN : 26|1@1+ (1,0) [0|1] "" Vector__XXX
 SG_ NMGW_I_Kl_15 : 30|1@1+ (1,0) [0|1] "" Vector__XXX
 SG_ NMGW_I_Diag_CAN : 31|1@1+ (1,0) [0|1] "" Vector__XXX
 SG_ NMGW_I_LIN1 : 32|1@1+ (1,0) [0|1] "" Vector__XXX
 SG_ NMGW_I_LIN2 : 33|1@1+ (1,0) [0|1] "" Vector__XXX
 SG_ NMGW_I_WakeUp2 : 34|6@1+ (1,0) [0|63] "" Vector__XXX
 SG_ NMGW_I_WakeUp3 : 40|8@1+ (1,0) [0|255] "" Vector__XXX

BO_ 1064 mNM_GSM_Pager: 6 GSM_Pager
 SG_ NMGSM_Receiver : 0|8@1+ (1,0) [0|255] ""  Booster_AMP,DSP_SKODA,Gateway_PQ35,Gateway_PQ46,GSM_Pager,Kompassmodul,MDI,Radio_2DIN,Radio_Modul,Radio_SKODA,Rearview,RNS_300_NF,RNS_MFD2,RNS_midline,SDARS_Tuner,Sprachbedienung,Standheizung,Tastatur,Telematik_Basis,TV_hybrid,UHV_High,UHV_low,UHV_NAR,UHV_Premium,UHV_UMTS
 SG_ NMGSM_CmdRing : 8|1@1+ (1,0) [0|1] ""  Booster_AMP,DSP_SKODA,Gateway_PQ35,Gateway_PQ46,GSM_Pager,Kompassmodul,MDI,Radio_2DIN,Radio_Modul,Radio_SKODA,Rearview,RNS_300_NF,RNS_MFD2,RNS_midline,SDARS_Tuner,Sprachbedienung,Standheizung,Tastatur,Telematik_Basis,TV_hybrid,UHV_High,UHV_low,UHV_NAR,UHV_Premium,UHV_UMTS
 SG_ NMGSM_CmdAlive : 9|1@1+ (1,0) [0|1] ""  Booster_AMP,DSP_SKODA,Gateway_PQ35,Gateway_PQ46,GSM_Pager,Kompassmodul,MDI,Radio_2DIN,Radio_Modul,Radio_SKODA,Rearview,RNS_300_NF,RNS_MFD2,RNS_midline,SDARS_Tuner,Sprachbedienung,Standheizung,Tastatur,Telematik_Basis,TV_hybrid,UHV_High,UHV_low,UHV_NAR,UHV_Premium,UHV_UMTS
 SG_ NMGSM_CmdLimpHome : 10|1@1+ (1,0) [0|1] ""  Booster_AMP,DSP_SKODA,Gateway_PQ35,Gateway_PQ46,GSM_Pager,Kompassmodul,MDI,Radio_2DIN,Radio_Modul,Radio_SKODA,Rearview,RNS_300_NF,RNS_MFD2,RNS_midline,SDARS_Tuner,Sprachbedienung,Standheizung,Tastatur,Telematik_Basis,TV_hybrid,UHV_High,UHV_low,UHV_NAR,UHV_Premium,UHV_UMTS
 SG_ NMGSM_SleepInd : 12|1@1+ (1,0) [0|1] ""  Booster_AMP,DSP_SKODA,Gateway_PQ35,Gateway_PQ46,GSM_Pager,Kompassmodul,MDI,Radio_2DIN,Radio_Modul,Radio_SKODA,Rearview,RNS_300_NF,RNS_MFD2,RNS_midline,SDARS_Tuner,Sprachbedienung,Standheizung,Tastatur,Telematik_Basis,TV_hybrid,UHV_High,UHV_low,UHV_NAR,UHV_Premium,UHV_UMTS
 SG_ NMGSM_SleepAck : 13|1@1+ (1,0) [0|1] ""  Booster_AMP,DSP_SKODA,Gateway_PQ35,Gateway_PQ46,GSM_Pager,Kompassmodul,MDI,Radio_2DIN,Radio_Modul,Radio_SKODA,Rearview,RNS_300_NF,RNS_MFD2,RNS_midline,SDARS_Tuner,Sprachbedienung,Standheizung,Tastatur,Telematik_Basis,TV_hybrid,UHV_High,UHV_low,UHV_NAR,UHV_Premium,UHV_UMTS
 SG_ NMGSM_Kl_30_Reset : 20|1@1+ (1,0) [0|1] "" Vector__XXX
 SG_ NMGSM_Fkt_Nachlauf : 21|1@1+ (1,0) [0|1] "" Vector__XXX
 SG_ NMGSM_NWake : 22|1@1+ (1,0) [0|1] "" Vector__XXX
 SG_ NMGSM_CAN : 23|1@1+ (1,0) [0|1] "" Vector__XXX
 SG_ NMGSM_Klemme_15 : 24|1@1+ (1,0) [0|1] "" Vector__XXX
 SG_ NMGSM_WakeUp2 : 32|8@1+ (1,0) [0|255] "" Vector__XXX
 SG_ NMGSM_WakeUp3 : 40|8@1+ (1,0) [0|255] "" Vector__XXX

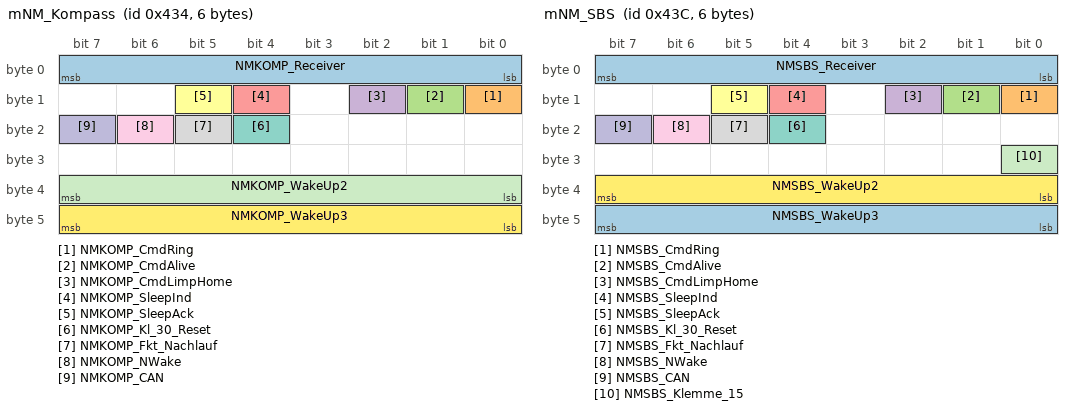
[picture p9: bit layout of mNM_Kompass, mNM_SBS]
BO_ 1076 mNM_Kompass: 6 Kompassmodul
 SG_ NMKOMP_Receiver : 0|8@1+ (1,0) [0|255] ""  Booster_AMP,DSP_SKODA,Gateway_PQ35,Gateway_PQ46,GSM_Pager,Kompassmodul,MDI,Radio_2DIN,Radio_Modul,Radio_SKODA,Rearview,RNS_300_NF,RNS_MFD2,RNS_midline,SDARS_Tuner,Sprachbedienung,Standheizung,Tastatur,Telematik_Basis,TV_hybrid,UHV_High,UHV_low,UHV_NAR,UHV_Premium,UHV_UMTS
 SG_ NMKOMP_CmdRing : 8|1@1+ (1,0) [0|1] ""  Booster_AMP,DSP_SKODA,Gateway_PQ35,Gateway_PQ46,GSM_Pager,Kompassmodul,MDI,Radio_2DIN,Radio_Modul,Radio_SKODA,Rearview,RNS_300_NF,RNS_MFD2,RNS_midline,SDARS_Tuner,Sprachbedienung,Standheizung,Tastatur,Telematik_Basis,TV_hybrid,UHV_High,UHV_low,UHV_NAR,UHV_Premium,UHV_UMTS
 SG_ NMKOMP_CmdAlive : 9|1@1+ (1,0) [0|1] ""  Booster_AMP,DSP_SKODA,Gateway_PQ35,Gateway_PQ46,GSM_Pager,Kompassmodul,MDI,Radio_2DIN,Radio_Modul,Radio_SKODA,Rearview,RNS_300_NF,RNS_MFD2,RNS_midline,SDARS_Tuner,Sprachbedienung,Standheizung,Tastatur,Telematik_Basis,TV_hybrid,UHV_High,UHV_low,UHV_NAR,UHV_Premium,UHV_UMTS
 SG_ NMKOMP_CmdLimpHome : 10|1@1+ (1,0) [0|1] ""  Booster_AMP,DSP_SKODA,Gateway_PQ35,Gateway_PQ46,GSM_Pager,Kompassmodul,MDI,Radio_2DIN,Radio_Modul,Radio_SKODA,Rearview,RNS_300_NF,RNS_MFD2,RNS_midline,SDARS_Tuner,Sprachbedienung,Standheizung,Tastatur,Telematik_Basis,TV_hybrid,UHV_High,UHV_low,UHV_NAR,UHV_Premium,UHV_UMTS
 SG_ NMKOMP_SleepInd : 12|1@1+ (1,0) [0|1] ""  Booster_AMP,DSP_SKODA,Gateway_PQ35,Gateway_PQ46,GSM_Pager,Kompassmodul,MDI,Radio_2DIN,Radio_Modul,Radio_SKODA,Rearview,RNS_300_NF,RNS_MFD2,RNS_midline,SDARS_Tuner,Sprachbedienung,Standheizung,Tastatur,Telematik_Basis,TV_hybrid,UHV_High,UHV_low,UHV_NAR,UHV_Premium,UHV_UMTS
 SG_ NMKOMP_SleepAck : 13|1@1+ (1,0) [0|1] ""  Booster_AMP,DSP_SKODA,Gateway_PQ35,Gateway_PQ46,GSM_Pager,Kompassmodul,MDI,Radio_2DIN,Radio_Modul,Radio_SKODA,Rearview,RNS_300_NF,RNS_MFD2,RNS_midline,SDARS_Tuner,Sprachbedienung,Standheizung,Tastatur,Telematik_Basis,TV_hybrid,UHV_High,UHV_low,UHV_NAR,UHV_Premium,UHV_UMTS
 SG_ NMKOMP_Kl_30_Reset : 20|1@1+ (1,0) [0|1] "" Vector__XXX
 SG_ NMKOMP_Fkt_Nachlauf : 21|1@1+ (1,0) [0|1] "" Vector__XXX
 SG_ NMKOMP_NWake : 22|1@1+ (1,0) [0|1] "" Vector__XXX
 SG_ NMKOMP_CAN : 23|1@1+ (1,0) [0|1] "" Vector__XXX
 SG_ NMKOMP_WakeUp2 : 32|8@1+ (1,0) [0|255] "" Vector__XXX
 SG_ NMKOMP_WakeUp3 : 40|8@1+ (1,0) [0|255] "" Vector__XXX

BO_ 1084 mNM_SBS: 6 Sprachbedienung
 SG_ NMSBS_Receiver : 0|8@1+ (1,0) [0|255] ""  Booster_AMP,DSP_SKODA,Gateway_PQ35,Gateway_PQ46,GSM_Pager,Kompassmodul,MDI,Radio_2DIN,Radio_Modul,Radio_SKODA,Rearview,RNS_300_NF,RNS_MFD2,RNS_midline,SDARS_Tuner,Sprachbedienung,Standheizung,Tastatur,Telematik_Basis,TV_hybrid,UHV_High,UHV_low,UHV_NAR,UHV_Premium,UHV_UMTS
 SG_ NMSBS_CmdRing : 8|1@1+ (1,0) [0|1] ""  Booster_AMP,DSP_SKODA,Gateway_PQ35,Gateway_PQ46,GSM_Pager,Kompassmodul,MDI,Radio_2DIN,Radio_Modul,Radio_SKODA,Rearview,RNS_300_NF,RNS_MFD2,RNS_midline,SDARS_Tuner,Sprachbedienung,Standheizung,Tastatur,Telematik_Basis,TV_hybrid,UHV_High,UHV_low,UHV_NAR,UHV_Premium,UHV_UMTS
 SG_ NMSBS_CmdAlive : 9|1@1+ (1,0) [0|1] ""  Booster_AMP,DSP_SKODA,Gateway_PQ35,Gateway_PQ46,GSM_Pager,Kompassmodul,MDI,Radio_2DIN,Radio_Modul,Radio_SKODA,Rearview,RNS_300_NF,RNS_MFD2,RNS_midline,SDARS_Tuner,Sprachbedienung,Standheizung,Tastatur,Telematik_Basis,TV_hybrid,UHV_High,UHV_low,UHV_NAR,UHV_Premium,UHV_UMTS
 SG_ NMSBS_CmdLimpHome : 10|1@1+ (1,0) [0|1] ""  Booster_AMP,DSP_SKODA,Gateway_PQ35,Gateway_PQ46,GSM_Pager,Kompassmodul,MDI,Radio_2DIN,Radio_Modul,Radio_SKODA,Rearview,RNS_300_NF,RNS_MFD2,RNS_midline,SDARS_Tuner,Sprachbedienung,Standheizung,Tastatur,Telematik_Basis,TV_hybrid,UHV_High,UHV_low,UHV_NAR,UHV_Premium,UHV_UMTS
 SG_ NMSBS_SleepInd : 12|1@1+ (1,0) [0|1] ""  Booster_AMP,DSP_SKODA,Gateway_PQ35,Gateway_PQ46,GSM_Pager,Kompassmodul,MDI,Radio_2DIN,Radio_Modul,Radio_SKODA,Rearview,RNS_300_NF,RNS_MFD2,RNS_midline,SDARS_Tuner,Sprachbedienung,Standheizung,Tastatur,Telematik_Basis,TV_hybrid,UHV_High,UHV_low,UHV_NAR,UHV_Premium,UHV_UMTS
 SG_ NMSBS_SleepAck : 13|1@1+ (1,0) [0|1] ""  Booster_AMP,DSP_SKODA,Gateway_PQ35,Gateway_PQ46,GSM_Pager,Kompassmodul,MDI,Radio_2DIN,Radio_Modul,Radio_SKODA,Rearview,RNS_300_NF,RNS_MFD2,RNS_midline,SDARS_Tuner,Sprachbedienung,Standheizung,Tastatur,Telematik_Basis,TV_hybrid,UHV_High,UHV_low,UHV_NAR,UHV_Premium,UHV_UMTS
 SG_ NMSBS_Kl_30_Reset : 20|1@1+ (1,0) [0|1] "" Vector__XXX
 SG_ NMSBS_Fkt_Nachlauf : 21|1@1+ (1,0) [0|1] "" Vector__XXX
 SG_ NMSBS_NWake : 22|1@1+ (1,0) [0|1] "" Vector__XXX
 SG_ NMSBS_CAN : 23|1@1+ (1,0) [0|1] "" Vector__XXX
 SG_ NMSBS_Klemme_15 : 24|1@1+ (1,0) [0|1] "" Vector__XXX
 SG_ NMSBS_WakeUp2 : 32|8@1+ (1,0) [0|255] "" Vector__XXX
 SG_ NMSBS_WakeUp3 : 40|8@1+ (1,0) [0|255] "" Vector__XXX

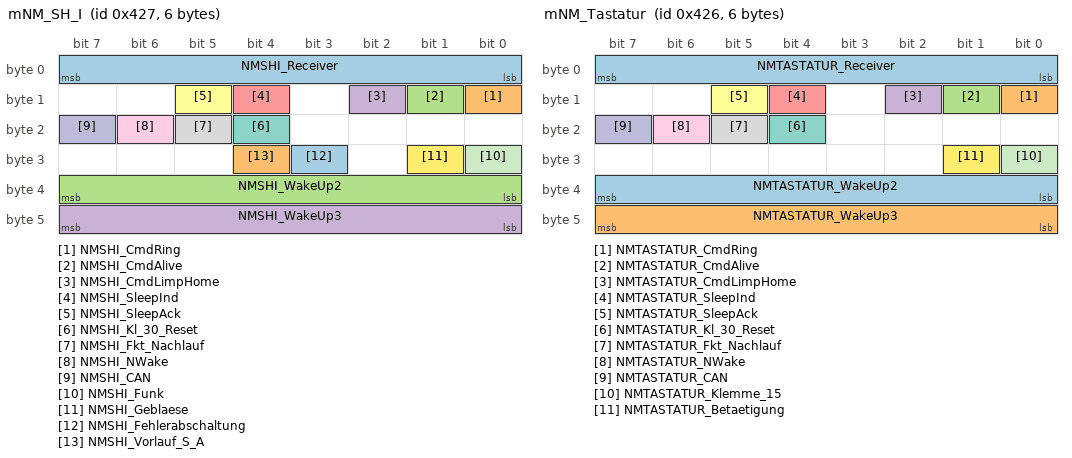
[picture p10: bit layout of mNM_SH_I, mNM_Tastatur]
BO_ 1063 mNM_SH_I: 6 Standheizung
 SG_ NMSHI_Receiver : 0|8@1+ (1,0) [0|255] ""  Booster_AMP,DSP_SKODA,Gateway_PQ35,Gateway_PQ46,GSM_Pager,Kompassmodul,MDI,Radio_2DIN,Radio_Modul,Radio_SKODA,Rearview,RNS_300_NF,RNS_MFD2,RNS_midline,SDARS_Tuner,Sprachbedienung,Standheizung,Tastatur,Telematik_Basis,TV_hybrid,UHV_High,UHV_low,UHV_NAR,UHV_Premium,UHV_UMTS
 SG_ NMSHI_CmdRing : 8|1@1+ (1,0) [0|1] ""  Booster_AMP,DSP_SKODA,Gateway_PQ35,Gateway_PQ46,GSM_Pager,Kompassmodul,MDI,Radio_2DIN,Radio_Modul,Radio_SKODA,Rearview,RNS_300_NF,RNS_MFD2,RNS_midline,SDARS_Tuner,Sprachbedienung,Standheizung,Tastatur,Telematik_Basis,TV_hybrid,UHV_High,UHV_low,UHV_NAR,UHV_Premium,UHV_UMTS
 SG_ NMSHI_CmdAlive : 9|1@1+ (1,0) [0|1] ""  Booster_AMP,DSP_SKODA,Gateway_PQ35,Gateway_PQ46,GSM_Pager,Kompassmodul,MDI,Radio_2DIN,Radio_Modul,Radio_SKODA,Rearview,RNS_300_NF,RNS_MFD2,RNS_midline,SDARS_Tuner,Sprachbedienung,Standheizung,Tastatur,Telematik_Basis,TV_hybrid,UHV_High,UHV_low,UHV_NAR,UHV_Premium,UHV_UMTS
 SG_ NMSHI_CmdLimpHome : 10|1@1+ (1,0) [0|1] ""  Booster_AMP,DSP_SKODA,Gateway_PQ35,Gateway_PQ46,GSM_Pager,Kompassmodul,MDI,Radio_2DIN,Radio_Modul,Radio_SKODA,Rearview,RNS_300_NF,RNS_MFD2,RNS_midline,SDARS_Tuner,Sprachbedienung,Standheizung,Tastatur,Telematik_Basis,TV_hybrid,UHV_High,UHV_low,UHV_NAR,UHV_Premium,UHV_UMTS
 SG_ NMSHI_SleepInd : 12|1@1+ (1,0) [0|1] ""  Booster_AMP,DSP_SKODA,Gateway_PQ35,Gateway_PQ46,GSM_Pager,Kompassmodul,MDI,Radio_2DIN,Radio_Modul,Radio_SKODA,Rearview,RNS_300_NF,RNS_MFD2,RNS_midline,SDARS_Tuner,Sprachbedienung,Standheizung,Tastatur,Telematik_Basis,TV_hybrid,UHV_High,UHV_low,UHV_NAR,UHV_Premium,UHV_UMTS
 SG_ NMSHI_SleepAck : 13|1@1+ (1,0) [0|1] ""  Booster_AMP,DSP_SKODA,Gateway_PQ35,Gateway_PQ46,GSM_Pager,Kompassmodul,MDI,Radio_2DIN,Radio_Modul,Radio_SKODA,Rearview,RNS_300_NF,RNS_MFD2,RNS_midline,SDARS_Tuner,Sprachbedienung,Standheizung,Tastatur,Telematik_Basis,TV_hybrid,UHV_High,UHV_low,UHV_NAR,UHV_Premium,UHV_UMTS
 SG_ NMSHI_Kl_30_Reset : 20|1@1+ (1,0) [0|1] "" Vector__XXX
 SG_ NMSHI_Fkt_Nachlauf : 21|1@1+ (1,0) [0|1] "" Vector__XXX
 SG_ NMSHI_NWake : 22|1@1+ (1,0) [0|1] "" Vector__XXX
 SG_ NMSHI_CAN : 23|1@1+ (1,0) [0|1] "" Vector__XXX
 SG_ NMSHI_Funk : 24|1@1+ (1,0) [0|1] "" Vector__XXX
 SG_ NMSHI_Geblaese : 25|1@1+ (1,0) [0|1] "" Vector__XXX
 SG_ NMSHI_Fehlerabschaltung : 27|1@1+ (1,0) [0|1] "" Vector__XXX
 SG_ NMSHI_Vorlauf_S_A : 28|1@1+ (1,0) [0|1] "" Vector__XXX
 SG_ NMSHI_WakeUp2 : 32|8@1+ (1,0) [0|255] "" Vector__XXX
 SG_ NMSHI_WakeUp3 : 40|8@1+ (1,0) [0|255] "" Vector__XXX

BO_ 1062 mNM_Tastatur: 6 Tastatur
 SG_ NMTASTATUR_Receiver : 0|8@1+ (1,0) [0|255] ""  Booster_AMP,DSP_SKODA,Gateway_PQ35,Gateway_PQ46,GSM_Pager,Kompassmodul,MDI,Radio_2DIN,Radio_Modul,Radio_SKODA,Rearview,RNS_300_NF,RNS_MFD2,RNS_midline,SDARS_Tuner,Sprachbedienung,Standheizung,Tastatur,Telematik_Basis,TV_hybrid,UHV_High,UHV_low,UHV_NAR,UHV_Premium,UHV_UMTS
 SG_ NMTASTATUR_CmdRing : 8|1@1+ (1,0) [0|1] ""  Booster_AMP,DSP_SKODA,Gateway_PQ35,Gateway_PQ46,GSM_Pager,Kompassmodul,MDI,Radio_2DIN,Radio_Modul,Radio_SKODA,Rearview,RNS_300_NF,RNS_MFD2,RNS_midline,SDARS_Tuner,Sprachbedienung,Standheizung,Tastatur,Telematik_Basis,TV_hybrid,UHV_High,UHV_low,UHV_NAR,UHV_Premium,UHV_UMTS
 SG_ NMTASTATUR_CmdAlive : 9|1@1+ (1,0) [0|1] ""  Booster_AMP,DSP_SKODA,Gateway_PQ35,Gateway_PQ46,GSM_Pager,Kompassmodul,MDI,Radio_2DIN,Radio_Modul,Radio_SKODA,Rearview,RNS_300_NF,RNS_MFD2,RNS_midline,SDARS_Tuner,Sprachbedienung,Standheizung,Tastatur,Telematik_Basis,TV_hybrid,UHV_High,UHV_low,UHV_NAR,UHV_Premium,UHV_UMTS
 SG_ NMTASTATUR_CmdLimpHome : 10|1@1+ (1,0) [0|1] ""  Booster_AMP,DSP_SKODA,Gateway_PQ35,Gateway_PQ46,GSM_Pager,Kompassmodul,MDI,Radio_2DIN,Radio_Modul,Radio_SKODA,Rearview,RNS_300_NF,RNS_MFD2,RNS_midline,SDARS_Tuner,Sprachbedienung,Standheizung,Tastatur,Telematik_Basis,TV_hybrid,UHV_High,UHV_low,UHV_NAR,UHV_Premium,UHV_UMTS
 SG_ NMTASTATUR_SleepInd : 12|1@1+ (1,0) [0|1] ""  Booster_AMP,DSP_SKODA,Gateway_PQ35,Gateway_PQ46,GSM_Pager,Kompassmodul,MDI,Radio_2DIN,Radio_Modul,Radio_SKODA,Rearview,RNS_300_NF,RNS_MFD2,RNS_midline,SDARS_Tuner,Sprachbedienung,Standheizung,Tastatur,Telematik_Basis,TV_hybrid,UHV_High,UHV_low,UHV_NAR,UHV_Premium,UHV_UMTS
 SG_ NMTASTATUR_SleepAck : 13|1@1+ (1,0) [0|1] ""  Booster_AMP,DSP_SKODA,Gateway_PQ35,Gateway_PQ46,GSM_Pager,Kompassmodul,MDI,Radio_2DIN,Radio_Modul,Radio_SKODA,Rearview,RNS_300_NF,RNS_MFD2,RNS_midline,SDARS_Tuner,Sprachbedienung,Standheizung,Tastatur,Telematik_Basis,TV_hybrid,UHV_High,UHV_low,UHV_NAR,UHV_Premium,UHV_UMTS
 SG_ NMTASTATUR_Kl_30_Reset : 20|1@1+ (1,0) [0|1] "" Vector__XXX
 SG_ NMTASTATUR_Fkt_Nachlauf : 21|1@1+ (1,0) [0|1] "" Vector__XXX
 SG_ NMTASTATUR_NWake : 22|1@1+ (1,0) [0|1] "" Vector__XXX
 SG_ NMTASTATUR_CAN : 23|1@1+ (1,0) [0|1] "" Vector__XXX
 SG_ NMTASTATUR_Klemme_15 : 24|1@1+ (1,0) [0|1] "" Vector__XXX
 SG_ NMTASTATUR_Betaetigung : 25|1@1+ (1,0) [0|1] "" Vector__XXX
 SG_ NMTASTATUR_WakeUp2 : 32|8@1+ (1,0) [0|255] "" Vector__XXX
 SG_ NMTASTATUR_WakeUp3 : 40|8@1+ (1,0) [0|255] "" Vector__XXX

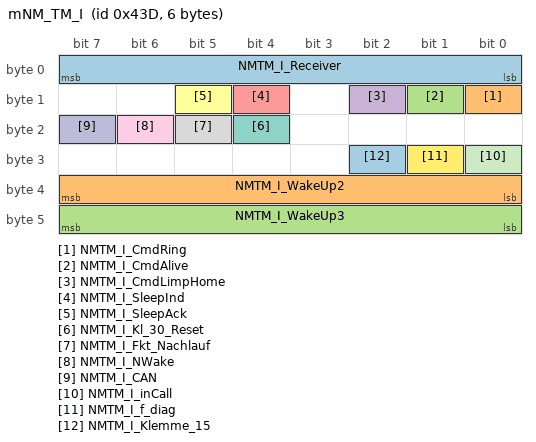
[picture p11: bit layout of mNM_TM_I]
BO_ 1085 mNM_TM_I: 6 Telematik_Basis
 SG_ NMTM_I_Receiver : 0|8@1+ (1,0) [0|255] ""  Booster_AMP,DSP_SKODA,Gateway_PQ35,Gateway_PQ46,GSM_Pager,Kompassmodul,MDI,Radio_2DIN,Radio_Modul,Radio_SKODA,Rearview,RNS_300_NF,RNS_MFD2,RNS_midline,SDARS_Tuner,Sprachbedienung,Standheizung,Tastatur,Telematik_Basis,TV_hybrid,UHV_High,UHV_low,UHV_NAR,UHV_Premium,UHV_UMTS
 SG_ NMTM_I_CmdRing : 8|1@1+ (1,0) [0|1] ""  Booster_AMP,DSP_SKODA,Gateway_PQ35,Gateway_PQ46,GSM_Pager,Kompassmodul,MDI,Radio_2DIN,Radio_Modul,Radio_SKODA,Rearview,RNS_300_NF,RNS_MFD2,RNS_midline,SDARS_Tuner,Sprachbedienung,Standheizung,Tastatur,Telematik_Basis,TV_hybrid,UHV_High,UHV_low,UHV_NAR,UHV_Premium,UHV_UMTS
 SG_ NMTM_I_CmdAlive : 9|1@1+ (1,0) [0|1] ""  Booster_AMP,DSP_SKODA,Gateway_PQ35,Gateway_PQ46,GSM_Pager,Kompassmodul,MDI,Radio_2DIN,Radio_Modul,Radio_SKODA,Rearview,RNS_300_NF,RNS_MFD2,RNS_midline,SDARS_Tuner,Sprachbedienung,Standheizung,Tastatur,Telematik_Basis,TV_hybrid,UHV_High,UHV_low,UHV_NAR,UHV_Premium,UHV_UMTS
 SG_ NMTM_I_CmdLimpHome : 10|1@1+ (1,0) [0|1] ""  Booster_AMP,DSP_SKODA,Gateway_PQ35,Gateway_PQ46,GSM_Pager,Kompassmodul,MDI,Radio_2DIN,Radio_Modul,Radio_SKODA,Rearview,RNS_300_NF,RNS_MFD2,RNS_midline,SDARS_Tuner,Sprachbedienung,Standheizung,Tastatur,Telematik_Basis,TV_hybrid,UHV_High,UHV_low,UHV_NAR,UHV_Premium,UHV_UMTS
 SG_ NMTM_I_SleepInd : 12|1@1+ (1,0) [0|1] ""  Booster_AMP,DSP_SKODA,Gateway_PQ35,Gateway_PQ46,GSM_Pager,Kompassmodul,MDI,Radio_2DIN,Radio_Modul,Radio_SKODA,Rearview,RNS_300_NF,RNS_MFD2,RNS_midline,SDARS_Tuner,Sprachbedienung,Standheizung,Tastatur,Telematik_Basis,TV_hybrid,UHV_High,UHV_low,UHV_NAR,UHV_Premium,UHV_UMTS
 SG_ NMTM_I_SleepAck : 13|1@1+ (1,0) [0|1] ""  Booster_AMP,DSP_SKODA,Gateway_PQ35,Gateway_PQ46,GSM_Pager,Kompassmodul,MDI,Radio_2DIN,Radio_Modul,Radio_SKODA,Rearview,RNS_300_NF,RNS_MFD2,RNS_midline,SDARS_Tuner,Sprachbedienung,Standheizung,Tastatur,Telematik_Basis,TV_hybrid,UHV_High,UHV_low,UHV_NAR,UHV_Premium,UHV_UMTS
 SG_ NMTM_I_Kl_30_Reset : 20|1@1+ (1,0) [0|1] "" Vector__XXX
 SG_ NMTM_I_Fkt_Nachlauf : 21|1@1+ (1,0) [0|1] "" Vector__XXX
 SG_ NMTM_I_NWake : 22|1@1+ (1,0) [0|1] "" Vector__XXX
 SG_ NMTM_I_CAN : 23|1@1+ (1,0) [0|1] "" Vector__XXX
 SG_ NMTM_I_inCall : 24|1@1+ (1,0) [0|1] "" Vector__XXX
 SG_ NMTM_I_f_diag : 25|1@1+ (1,0) [0|1] "" Vector__XXX
 SG_ NMTM_I_Klemme_15 : 26|1@1+ (1,0) [0|1] "" Vector__XXX
 SG_ NMTM_I_WakeUp2 : 32|8@1+ (1,0) [0|255] "" Vector__XXX
 SG_ NMTM_I_WakeUp3 : 40|8@1+ (1,0) [0|255] "" Vector__XXX

BO_TX_BU_ 963 : Gateway_PQ35,Gateway_PQ46;
BO_TX_BU_ 1329 : Gateway_PQ35,Gateway_PQ46;
BO_TX_BU_ 705 : Gateway_PQ35,Gateway_PQ46;
BO_TX_BU_ 1317 : Gateway_PQ35,Gateway_PQ46;
BO_TX_BU_ 1287 : Radio_Modul,Radio_SKODA,RNS_midline;
BO_TX_BU_ 1577 : Gateway_PQ35,Gateway_PQ46;
BO_TX_BU_ 1579 : Gateway_PQ35,Gateway_PQ46;
BO_TX_BU_ 1581 : Gateway_PQ35,Gateway_PQ46;
BO_TX_BU_ 1321 : Gateway_PQ35,Gateway_PQ46;
BO_TX_BU_ 1323 : Gateway_PQ35,Gateway_PQ46;
BO_TX_BU_ 1475 : Gateway_PQ35,Gateway_PQ46;
BO_TX_BU_ 1473 : Gateway_PQ35,Gateway_PQ46;
BO_TX_BU_ 1481 : Gateway_PQ35,Gateway_PQ46;
BO_TX_BU_ 1365 : Gateway_PQ35,Gateway_PQ46;
BO_TX_BU_ 1420 : Gateway_PQ35,Gateway_PQ46;
BO_TX_BU_ 1540 : RNS_300_NF,RNS_MFD2,RNS_midline;
BO_TX_BU_ 1441 : RNS_300_NF,RNS_midline;
BO_TX_BU_ 673 : RNS_300_NF,RNS_midline;
BO_TX_BU_ 1455 : RNS_300_NF,RNS_midline;
BO_TX_BU_ 1443 : RNS_300_NF,RNS_midline;
BO_TX_BU_ 1067 : Gateway_PQ35,Gateway_PQ46;
CM_ SG_ 963 LW1_Lenkradwinkel "Low Byte 1, High Byte 2
0 geradeaus
7FFFH am Anschlag
Lenkradwinkel";
CM_ SG_ 963 LW1_Vorzeichen "positiver Lenkradwinkel: nach links
negativer Lenkradwinkel: nach rechts
Lenkradwinkel_Sign";
CM_ SG_ 963 LW1_Geschwindigkeit "Low Byte 3, High Byte 4
0 keine Bewegung
7FFFH maximale Geschwindigkeit
Lenkradwinkel-Geschwindigkeit";
CM_ SG_ 963 LW1_Geschw_Vorzeichen "Lenkradwinkel-Geschwindigkeit_Sign";
CM_ SG_ 963 LW1_ID "Nullpunktabgleich des LWS noch nicht durchgeführt
Sonstige Fzg (außer PQ35): ESP-Steuergerät übergibt beim Nullpunktabgleich eine ID-Nummer an den LWS. Die Zufallszahl wird nach erfolgreichem Nullpunktabgleich als Lenkwinkel_ID übernommen
PQ35/46: Bit 7";
CM_ SG_ 963 LW1_Quelle_Init "Lenkwinkelsensor wird über Raddrehzahl oder 'Geradeausfahrt'-Bit der EPS initialisiert
Quelle für Init";
CM_ SG_ 963 LW1_Int_Status "'o.k.': absoluter Lenkradwinkel und Lenkradwinkelgeschwindigkeit werden korrekt berechnet
'no init': Sensor ist nicht initialisiert, absoluter Lenkrad-winkel kann noch nicht berechnet werden, kein Fehler
'sporadischer Fehler': Sensor ist bis zum Ausscha";
CM_ SG_ 963 LW1_KL30_Ausfall "(z.Zt. nur Kostal-Sensor)
Sensor ist nach KL30-Ausfall nicht initialisiert, absoluter Lenkradwinkel kann noch nicht berechnet werden, Segmenterkennung durch Auswertung der Radsignale
Status_KL30_Ausfall";
CM_ SG_ 963 LW1_Zaehler "freilaufender Botschaftszähler";
CM_ SG_ 963 LW1_CRC8CHK "NEUES SIGNAL CRC8 Checksumme (z. Zt. Lenkhilfe ZF Gen. 3)!
CRC Prüfsumme über die Bytes 1..6 / Diese ist nach Spezifikation 'CAN Checksumme CRC-8; Version 1.1; 23.09.05' durchzuführen.
ACHTUNG: Der separate LWS gibt in Byte 7 noch das Signal LW1_Kodier ";
CM_ SG_ 963 LW1_Pruefsumme "Definition nach Lastenheft 'Übertragungsmodul für ESP':
Einerkomplement des Ergebnisses der 8 Bit Addition von Byte 1, 2, 3, 4 und 6.
Prüfsumme (Lenkwinkel 1)";
CM_ SG_ 1329 LIA_Standlicht "1 = Parklicht links eingeshaltet (BCM_PQ25: Schalterinformation)
Vorsicht Sleep-Mode!
Kl58, Standlicht ein";
CM_ SG_ 1329 LIA_Abblendlicht "Statusmeldungen fuer Anzeige im Kombi
Kl56b Abblendlicht ein";
CM_ SG_ 1329 LIA_Fernlicht "1 = Licht ein
Kl56a Fernlicht ein";
CM_ SG_ 1329 LIA_Nebellicht "1 = Nebelscheinwerfer eingeschaltet
Kl83a Nebellicht ein";
CM_ SG_ 1329 LIA_Nebelschluss "1 = Nebelschlusslicht eingeschaltet
Kl83b Nebelschlussleuchte ein";
CM_ SG_ 1329 LIA_Rueckfahrlicht "1 = Rueckfahrlicht ein";
CM_ SG_ 1329 LIA_Parklicht_links "1 = Parklicht links eingeschaltet (BCM_PQ25: Schalterinformation)
Parklicht links ein";
CM_ SG_ 1329 LIA_Parklicht_rechts "1 = Parklicht rehts eingeschaltet (BCM_PQ25: Schalterinformation)
Parklicht rechts ein";
CM_ SG_ 1329 LIA_Blk_links "1 = Blinker ein
0 = Blinker aus
dynamisch
Blinklampe links ein";
CM_ SG_ 1329 LIA_Blk_rechts "1 = Blinker ein
0 = Blinker aus
dynamisch
Blinklampe rechts ein";
CM_ SG_ 1329 LIA_Anhaenger "1 = Anhaengerbetrieb
dynamisch mit Blinken ein / aus (Zusatzinfo)
Anhaengerblinklampe ein";
CM_ SG_ 1329 LIA_Warnblink "1 = Warnblinkmode
dynamisch mit Blinken ein / aus (Zusatzinfo)";
CM_ SG_ 1329 LIA_BLK_Frequenz "1 = Blinkfrequenz der Blinker";
CM_ SG_ 1329 LIA_AFL_Schalter "1 = Schalter in Stellung Assistenzfahrlicht";
CM_ SG_ 1329 LIA_Bremslicht "1 = Bremslicht eingeschaltet";
CM_ SG_ 1329 LIA_Tagesfahrlicht "1 = Tagesfahrlicht ist eingeschaltet";
CM_ SG_ 1329 LIA_Blk_L_Kontrolle "1 = Kontrollampe Blinker links ein
0 = Kontrollampe Blinker links aus
Ansteuerung Blinkerkontrollampe links";
CM_ SG_ 1329 LIA_Blk_R_Kontrolle "1 = Kontrollampe Blinker rechts ein
0 = Kontrollampe Blinker rechts aus
Ansteuerung Blinkerkontrollampe rechts";
CM_ SG_ 1329 LIA_Kurv_Licht "Kurvenlicht ist eingeschaltet";
CM_ SG_ 1329 LIA_Warnblk_Status "1 = solange Warnblinken aktiviert ist
0 = kein Warnblinken aktiv
Statische Anzeige Warnblinklicht ist eingeschaltet";
CM_ SG_ 1329 LIA_Zaehler "Definition gemaess Lastenheft
Botschaftszaehler zur Lebenderkennung";
CM_ SG_ 1329 LIA_Pruefsumme "Definition gemaess Lastenheft";
CM_ SG_ 705 LS1_Blk_links "Richtungsblinken links betaetigt (s. Gateway Komfort)";
CM_ SG_ 705 LS1_Blk_rechts "Richtungsblinken rechts betaetigt (s. Gateway Komfort)";
CM_ SG_ 705 LS1_Lichthupe "Lichthupe ein";
CM_ SG_ 705 LS1_Fernlicht "Fernlichtschalter";
CM_ SG_ 705 LS1_Parklicht_links "Parklicht links ein";
CM_ SG_ 705 LS1_Parklicht_rechts "Parklicht rechts ein";
CM_ SG_ 705 LS1_Signalhorn "Hupe ein";
CM_ SG_ 705 LS1_Tipwischen "Tipwischen ein";
CM_ SG_ 705 LS1_Intervall "Intervall oder Regensensorautomatik Frontwischer ein";
CM_ SG_ 705 LS1_WischenStufe_1 "Wischergeschwindigkeit Stufe 1";
CM_ SG_ 705 LS1_WischenStufe_2 "Wischergeschwindigkeit Stufe 2";
CM_ SG_ 705 LS1_Frontwaschen "1 = Lenkstockschalter in Position Frontwaschen
Wisch-Wasch vorne";
CM_ SG_ 705 LS1_Bew_Frontwaschen "1 = Frontwaschfunktion ist aktiv, hier bewertete Information, z.B. Tippwaschen
bewerte Wisch-Wasch Funktion vorne";
CM_ SG_ 705 LS1_Heckintervall "Lenkstockschalter (LSS) befindet sich in der Position Heckwischen im Intervallbetrieb. Signal wird auch ca 8 Sek. nach Heckwaschbetrieb gesetzt (Traenenwischen) oder bei Einlegen des Rückwaertsganges bei Frontwischerbetrieb und nasser Heckscheibe, obwohl ";
CM_ SG_ 705 LS1_Heckwaschen "1 = Lenkstockschalter in Position Heckwaschen
Wisch-Wasch hinten";
CM_ SG_ 705 LS1_Intervallstufen "Intervallgeschwindigkeit / Regensensorempfindlichkeit (1: lange Pausen, 15: kurze P.)";
CM_ SG_ 705 LS1_BC_Down_Cursor "Bordcomputer Cursor Down";
CM_ SG_ 705 LS1_BC_Up_Cursor "Bordcomputer Cursor UP";
CM_ SG_ 705 LS1_BC_Reset "Bordcomputer Reset";
CM_ SG_ 705 LS1_KD_Fehler "1 = mindestens ein Kundendienstfehler ist im Fehlerspeicher eingetragen";
CM_ SG_ 705 LS1_LSY_oben "Lenksaeulenverstellung Y+";
CM_ SG_ 705 LS1_LSY_unten "Lenksaeulenverstellung Y-";
CM_ SG_ 705 LS1_LSZ_vor "Lenksaeulenverstellung Z+";
CM_ SG_ 705 LS1_LSZ_zurueck "Lenksaeulenverstellung Z-";
CM_ SG_ 705 LS1_ELV_enable "Befehl zum Verriegeln bzw. Entriegeln der elektrischen Lenksäulenverriegelung";
CM_ SG_ 705 LS1_def_ELV_Enable "SMLS liest Hardwareleitung ELV_Enable zurueck. Bei erkannten Fehler wird dieses Bit gesetzt.
Diagnoseinformation fuer ELV-Enable Signal";
CM_ SG_ 705 LS1_Easy_Entry_LS "1 = Easy Entry Lenksaeule aktiv
0 = Easy Entry Lenksaeule abgeschaltet
Aktivierung Easy Entry Funktion der Lenksaeule";
CM_ SG_ 705 LS1_LHeizung_aktiv "Eine Abschaltung der Lenkradheizung durch das Lastmanagement oder interne Regelvorgänge wird hier nicht angezeigt
Lenkradheizung ist eingeschaltet";
CM_ SG_ 705 LS1_Winterstellung "1 = Positionierung der Wischerblaetter in Winterstellung (Reversierwischeranlage)";
CM_ SG_ 705 LS1_MFL_vorhanden "1 = Multifunktionslenkrad vorhanden";
CM_ SG_ 705 LS1_MFA_vorhanden "1 = MFA-Schalter verbaut
0 = kein MFA- Schalter
MFA Tasten vorhanden";
CM_ SG_ 705 LS1_MFA_Tasten "0 = Init = 3 Tasten MFA- Schalter verbaut
1 = 4 Tasten MFA-Schalter verbaut
Anzahl MFA Tasten";
CM_ SG_ 705 LS1_def_P_Verriegelt "1 = Defekt des P-Verriegelt-Schalters erkannt
0 = P-Verriegelt-Schalter o.K
eine Anzeige im Kombi soll mit diesem Bit realisiert werden.
Defekterkennung des Park Verriegeltschalters im Waehlhebel";
CM_ SG_ 705 LS1_MFL_Typ "0 = MFL LOW-Variante, d.h. nur 3 Tasten fuer Infotainmetbedienung
1 = MFL-High Variante, d.h. 5 Elemente fuer Infotainmentbedienung

Im PQ35/PQ46:
0 = MFL-Bedienkonzept alt
1 = Neues MFL-Bedienkonzept";
CM_ SG_ 705 LS1_Servicestellung "1 = Positionierung der Wischerblaetter in Servicestellung (Ermoeglicht das Wechseln der Wischerblaetter)";
CM_ SG_ 705 LS1_P_verriegelt "Zustand der Zuendschluesselabzugssperre (entsprechend Waehlhebelstellung, aber ueber Draht vom Waehlhebel) Achtung kein weiterer Empfaenger als ELV, da Signal nicht sicher ermittelt werden kann.
Zustand P_verriegelt_Schalter Lenkschloss";
CM_ SG_ 705 LS1_FAS_Taster "1 = Bedientaster fuer Fahrerassistenzsysteme betätigt";
CM_ SG_ 705 LS1_Fehler_FAS_Taster "Fehler in Bedientaster fuer Fahrerassistenzsysteme";
CM_ SG_ 705 LS1_Fehler_Vibration "Fehler Vibrationslenkrad";
CM_ SG_ 1371 MD1_MDI_on "MDI ist betriebsbereit";
CM_ SG_ 1371 MD1_MDI_Error_flag "Fehlereintrag vorhanden";
CM_ SG_ 1317 SHM_SH_SL "Signal wird vom Timer oder Funk ausgeloest
Standheizung/-Luefter ueber Timer/ Funk ein";
CM_ SG_ 1317 SHM_SH "Standheizung explizit ein (Kundenwunsch)";
CM_ SG_ 1317 SHM_SL "Standlueftung explizit ein (Kundenwunsch)";
CM_ SG_ 1317 SHM_MVW "0 = SH ohne Motorvorwaermung
1 = SH mit Motorvorwaermung
Standheizung mit/ohne Motorvorwaermung";
CM_ SG_ 1317 SHM_SH_Geblaese "1 = Standheizungsgeblaese ein";
CM_ SG_ 1317 SHM_Restdauer "7F = Fehler
Einschaltdauer Standheizung / Standlueftung";
CM_ SG_ 1287 DS1_Power_Mode "Power Mode:
0=Standby
1=Active
3=Run
Anwahl des DSP Power Mode";
CM_ SG_ 1287 DS1_Status_Request "Anforderung aller Statusbotschaften vom DSP";
CM_ SG_ 1287 DS1_Loudness "1 = Loudness ON
0 = OFF
Aktivierung Loudness";
CM_ SG_ 1287 DS1_Dynamic "1 = Dynamik On
0 = Dynamik Off
Aktivierung Dynamic";
CM_ SG_ 1287 DS1_Driver_On_Off "1 = DSP Einstellungen in Abhaengigkeit von Fahrerposition
Soundanpassung an Fahrerposition";
CM_ SG_ 1287 DS1_Sitzbezuege "1 = Lederbezuege
0 = Stoffbezuege
NUR ENTWICKLUNGSSTAND, Bit darf ausserhalb VW611 nicht verwendet werden!";
CM_ SG_ 1287 DS1_GALA "Auswahl einer im DSP abgelegten Funktion(Gerade) zur GALA Anpassung der Lautstaerke
GALA Steuerung";
CM_ SG_ 1287 DS1_Klangcharakter "Auswahl eines im DSP abgelegten Klangcharakters";
CM_ SG_ 1287 DS1_Bass "Einstellung Bass +/-
0, 0x10 = Nullstellung
-15 = min ........ 15 = max
Tiefeneinstellung";
CM_ SG_ 1287 DS1_Mid "Einstellung Mid +/-
0, 0x10 = Nullstellung
-15 = min ........ 15 = max
Mitteneinstellung";
CM_ SG_ 1287 DS1_Treble "Einstellung Treble +/-
0, 0x10 = Nullstellung
-15 = min ........ 15 = max
Hoeheneinstellung";
CM_ SG_ 1287 DS1_Mute_Mode "1 = Mute Fast
0 = Mute Slow
Fast/Soft Mute";
CM_ SG_ 1287 DS1_Ch_1_Mute "1 = Mute Channel 1
0 = kein Mute";
CM_ SG_ 1287 DS1_Ch_2_Mute "1 = Mute Channel 2
0 = kein Mute";
CM_ SG_ 1287 DS1_Ch_3_Mute "1 = Mute Channel 3
0 = kein Mute";
CM_ SG_ 1287 DS1_Effektstaerke "0, 0x8 = Nullstellung
0x9...0xF = Abschwaechung (Min to Max)
0x1...0x7 = Verstaerkung (Min to Max)
Bestimmt einen Abschwaechungs- bzw. Verstaerkungsgrad des eingestellten Klangcharakters (s. Byte 2 / Bit 4..7)
Effektstaerke fuer Klangcharaktere";
CM_ SG_ 1291 DS2_Ch_1_Source "Quellentyp zur Soundanpssung
0 = nicht bekannt
1 = Radio AM
2 = Radio FM
3 = CD
4 = MC
5 = TV
6 = Navigation
7 = Telefon
8 = Sprachausgabe
9 = DVD
Source Type Channel 1";
CM_ SG_ 1291 DS2_Ch_2_Source "Quellentyp zur Soundanpassung
0 = nicht bekannt
1 = Radio AM
2 = Radio FM
3 = CD
4 = MC
5 = TV
6 = Navigation
7 = Telefon
8 = Sprachausgabe
9 = DVD
Source Type Channel 2";
CM_ SG_ 1291 DS2_Stereo1_Active "Quellenschaltung
Stereo Channel activ (Channel 1)";
CM_ SG_ 1291 DS2_Mono1_Active "Quellenschaltung
Mono Channel 1 activ (Channel 2)";
CM_ SG_ 1291 DS2_Ch_1_Volume "0xFF = Fehler
0x00 = min
0xFE = max
Ziellautstaerke wenn Cross-Fading Channel 1 aktiv
Volume Channel 1";
CM_ SG_ 1291 DS2_Ch_1_Fader "0 = Initwert = Nullstellung
0x10 = Nullstellung
1 = max. Daempfung Vorne
31 = max. Daempfung Hinten
Fader Channel 1";
CM_ SG_ 1291 DS2_Ch_1_Cross_Fading "0 = kein Fading
1 = slow Fading
2 = middle Fading
3 = fast Fading
Cross Fading Lauf Channel 1";
CM_ SG_ 1291 DS2_Ch_1_Fading_ID "0 = Fading Kanal 0
1 = Fading Kanal 1
Der DSP beginnt erst mit Cross-Fading, wenn ein Fading Paar von zwei Kanaelen vorliegt (ID1=0 und ID2=1)
Cross Fading pair number";
CM_ SG_ 1291 DS2_Ch_1_Balance "0 = Initwert = Nullstellung
0x10 = Nullstellung
1 = max. Daempfung Rechts
31 = max. Daempfung Links
Balance Channel 1";
CM_ SG_ 1291 DS2_Ch_2_Volume "0xFF = Fehler
0x00 = min
0xFE = max
Ziellautstaerke wenn Cross-Fading Channel 2 aktiv
Volume Channel 2";
CM_ SG_ 1291 DS2_Ch_2_Fader "0 = Initwert = Nullstellung
0x10 = Nullstellung
1 = max. Daempfung Vorne
31 = max. Daempfung Hinten
Fader Channel 2";
CM_ SG_ 1291 DS2_Ch_2_Cross_Fading "0 = kein Fading
1 = slow Fading
2 = middle Fading
3 = fast Fading
Cross Fading Lauf Channel 2";
CM_ SG_ 1291 DS2_Ch_2_Fading_ID "0 = Fading Kanal 0
1 = Fading Kanal 1
Der DSP beginnt erst mit Cross-Fading, wenn ein Fading Paar von zwei Kanaelen vorliegt (ID1=0 und ID2=1)
Cross Fading pair number";
CM_ SG_ 1291 DS2_Ch_2_Balance "0 = Initwert = Nullstellung
0x10 = Nullstellung
1 = max. Daempfung Rechts
31 = max. Daempfung Links
Keine Bedeutung wenn Stereo aktiv
Balance Channel 2";
CM_ SG_ 1293 DS3_Ch_3_Source "Quellentyp zur Soundanpssung
0 = nicht bekannt
1 = Radio AM
2 = Radio FM
3 = CD
4 = MC
5 = TV
6 = Navigation
7 = Telefon
8 = Sprachausgabe
9 = DVD
Source Type Channel 3";
CM_ SG_ 1293 DS3_Mono2_Active "Mono Channel 2 activ (Channel 3)";
CM_ SG_ 1293 DS3_Chime_Active "Einmischen von Signalisierungstoenen
Chime activ";
CM_ SG_ 1293 DS3_Chime_Number "0xFF = Fehler
Auswahl eines Signaltones / Tabelle oder Freq. ?
Auswahl Chime";
CM_ SG_ 1293 DS3_Ch_3_Volume "0xFF = Fehler
0x00 = min
0xFE = max
Ziellautstaerke wenn Cross-Fading Channel 3 aktiv
Volume Channel 3";
CM_ SG_ 1293 DS3_Ch_3_Fader "0 = Initwert = Nullstellung
0x10 = Nullstellung
1 = max. Daempfung Vorne
31 = max. Daempfung Hinten
Fader Channel 3";
CM_ SG_ 1293 DS3_Ch_3_Cross_Fading "0 = kein Fading
1 = slow Fading
2 = middle Fading
3 = fast Fading
Cross Fading Lauf Channel 3";
CM_ SG_ 1293 DS3_Ch_3_Fading_ID "0 = Fading Kanal 0
1 = Fading Kanal 1
Der DSP beginnt erst mit Cross-Fading, wenn ein Fading Paar von zwei Kanaelen vorliegt (ID1=0 und ID2=1)
Cross Fading pair number";
CM_ SG_ 1293 DS3_Ch_3_Balance "0 = Initwert = Nullstellung
0x10 = Nullstellung
1 = max. Daempfung Rechts
31 = max. Daempfung Links
Balance Channel 3";
CM_ SG_ 1293 DS3_Chime_Volume "0xFF = Fehler
0x00 = min
0xFE = max
Volume Chime";
CM_ SG_ 1293 DS3_Chime_Fader "0 = Initwert = Nullstellung
0x10 = Nullstellung
1 = max. Daempfung Vorne
31 = max. Daempfung Hinten
Fader Chime";
CM_ SG_ 1293 DS3_Chime_Balance "0 = Initwert = Nullstellung
0x10 = Nullstellung
1 = max. Daempfung Rechts
31 = max. Daempfung Links
Balance Chime";
CM_ SG_ 1295 DS4_Hall "Veraenderung der Halleffekte in max. 15 Stufen
Halleffekteinstellung";
CM_ SG_ 1295 DS4_Echo "Veraenderung der Echoeffekte in max. 15 Stufen
Echoeffekteinstellung";
CM_ SG_ 1295 DS4_Cathedral "Veraenderung der Echoeffekte in max. 15 Stufen
Echoeffekteinstellung_CATHEDRAL";
CM_ SG_ 1295 DS4_Stadium "Veraenderung der Echoeffekte in max. 15 Stufen
Echoeffekteinstellung_STADIUM";
CM_ SG_ 1295 DS4_Talk "Veraenderung der Echoeffekte in max. 15 Stufen
Echoeffekteinstellung_TALK";
CM_ SG_ 1295 DS4_ROCK "Veraenderung der Echoeffekte in max. 15 Stufen
Halleffekteinstellung_ROCK";
CM_ SG_ 1295 DS4_POP "Veraenderung der Echoeffekte in max. 15 Stufen
Halleffekteinstellung_POP";
CM_ SG_ 1295 DS4_CLASSIC "Veraenderung der Echoeffekte in max. 15 Stufen
Halleffekteinstellung_CLASSIC";
CM_ SG_ 1295 DS4_LIVE "Veraenderung der Echoeffekte in max. 15 Stufen
Halleffekteinstellung_LIVE";
CM_ SG_ 1295 DS4_NEWS "Veraenderung der Echoeffekte in max. 15 Stufen
Halleffekteinstellung_NEWS";
CM_ SG_ 1577 MA1_Verbrauch "FFF - Ungueltig -> Anzeige lt. HMI-Sezifikation
Momentanverbrauch";
CM_ SG_ 1577 MA1_100km_Verbrauch "1 = Momentanverbrauchswert aus Bit 0..11 wird in Liter / 100 km dargestellt.
Einheit_L_100km";
CM_ SG_ 1577 MA1_l_Verbrauch "1 = Momentanverbrauchswert aus Bit 0..11 wird in km / Liter dargestellt.
Einheit_km_1L";
CM_ SG_ 1577 MA1_mpg_Verbrauch "1 = Momentanverbrauchswert aus Bit 0..11 wird in Meilen / Gallone dargestellt.
Einheit MPG";
CM_ SG_ 1577 MA1_Reichweite "3FFF - Ungueltig -> Anzeige lt. HMI-Sezifikation
Reichweite";
CM_ SG_ 1577 MA1_km_Reichweite "1 = Reichweite aus Bit 0...13 wird in km dargestellt
Einheit km";
CM_ SG_ 1577 MA1_mls_Reichweite "1 = Reichweite aus Bit 0...13 wird in Meilen dargestellt
Einheit mls";
CM_ SG_ 1577 MA1_Kilometerstand "Kilometerstand";
CM_ SG_ 1577 MA1_km_Kilometerstand "1 = Reichweite aus Bit 0...13 wird in km dargestellt
Einheit km";
CM_ SG_ 1577 MA1_mls_Kilometerstand "1 = Reichweite aus Bit 0...13 wird in Meilen dargestellt
Einheit mls";
CM_ SG_ 1579 MA2_Verbrauch "FFF - Ungueltig -> Anzeige lt. HMI-Sezifikation
Durchschnittsverbrauch";
CM_ SG_ 1579 MA2_100km_Verbrauch "1 = Durchschnittsverbrauchswert (Kurzzeit) aus Bit 0..11 wird in Liter / 100 km dargestellt.
Einheit_L_100km";
CM_ SG_ 1579 MA2_l_Verbrauch "1 = Durchschnittsverbrauchswert (Kurzzeit) aus Bit 0..11 wird in km / Liter dargestellt.
Einheit_km_1L";
CM_ SG_ 1579 MA2_mpg_Verbrauch "1 = Durchschnittsverbrauchswert (Kurzzeit) aus Bit 0..11 wird in Meilen / Gallone dargestellt.
Einheit MPG";
CM_ SG_ 1579 MA2_Strecke "3FFF - Ungueltig -> Anzeige lt. HMI-Sezifikation
Fahrstrecke";
CM_ SG_ 1579 MA2_km_Strecke "1 = Fahrstrecke (Kurzzeit) aus Bit 0...13 wird in km dargestellt
Einheit km";
CM_ SG_ 1579 MA2_mls_Strecke "1 = Fahrstrecke (Kurzzeit) aus Bit 0...13 wird in Meilen dargestellt
Einheit mls";
CM_ SG_ 1579 MA2_Zeit "3FFF - Ungueltig -> Anzeige lt. HMI-Sezifikation
Fahrzeit in Min.";
CM_ SG_ 1579 MA2_Geschw "3FFF - Ungueltig -> Anzeige lt. HMI-Sezifikation
Durchschnittsgeschwindigkeit";
CM_ SG_ 1579 MA2_kmh_Geschw "1 = Durchschnittsgschwindigkeit (Kurzzeit) aus Bit 0...13 wird in km/h dargestellt
Einheit km/h";
CM_ SG_ 1579 MA2_mph_Geschw "1 = Durchschnittsgschwindigkeit (Kurzzeit) aus Bit 0...13 wird in Meilen/Hour dargestellt
Einheit mph";
CM_ SG_ 1581 MA3_Verbrauch "FFF - Ungueltig -> Anzeige lt. HMI-Sezifikation
Durchschnittsverbrauch";
CM_ SG_ 1581 MA3_100km_Verbrauch "1 = Durchschnittsverbrauchswert (Langzeit) aus Bit 0..11 wird in Liter / 100 km dargestellt.
Einheit_L_100km";
CM_ SG_ 1581 MA3_l_Verbrauch "1 = Durchschnittsverbrauchswert (Langzeit) aus Bit 0..11 wird in km / Liter dargestellt.
Einheit_km_1L";
CM_ SG_ 1581 MA3_mpg_Verbrauch "1 = Durchschnittsverbrauchswert (Langzeit) aus Bit 0..11 wird in Meilen / Gallone dargestellt.
Einheit MPG";
CM_ SG_ 1581 MA3_Strecke "3FFF - Ungueltig -> Anzeige lt. HMI-Sezifikation
Fahrstrecke";
CM_ SG_ 1581 MA3_km_Strecke "1 = Fahrstrecke (Langzeit) aus Bit 0...13 wird in km dargestellt
Einheit km";
CM_ SG_ 1581 MA3_mls_Strecke "1 = Fahrstrecke (Langzeit) aus Bit 0...13 wird in Meilen dargestellt
Einheit mls";
CM_ SG_ 1581 MA3_Zeit "3FFF - Ungueltig -> Anzeige lt. HMI-Sezifikation
Fahrzeit in Min.";
CM_ SG_ 1581 MA3_Geschw "3FFF - Ungueltig -> Anzeige lt. HMI-Sezifikation
Durchschnittsgeschwindigkeit";
CM_ SG_ 1581 MA3_kmh_Geschw "1 = Durchschnittsgschwindigkeit (Langzeit) aus Bit 0...13 wird in km/h dargestellt
Einheit km/h";
CM_ SG_ 1581 MA3_mph_Geschw "1 = Durchschnittsgschwindigkeit (Langzeit) aus Bit 0...13 wird in Meilen/Hour dargestellt
Einheit mph";
CM_ SG_ 1321 MA4_Verbr_TZ "FFF - Ungueltig -> Anzeige lt. HMI-Sezifikation; Gilt in Verbindung mit Signal MA4_Tankzyklus f. letzten bzw. aktuellen Tankzyklus
Wert wird in eingestellter Einheit uebertragen (km oder mls).
Durchschnittsverbrauch im Tankzyklus";
CM_ SG_ 1321 MA4_100km_Verbrauch "1 = Einheit: l pro 100 km";
CM_ SG_ 1321 MA4_l_Verbrauch "1 = km pro 1 liter
Einheit km pro 1l";
CM_ SG_ 1321 MA4_mpg_Verbrauch "1 = Einheit miles per gallons
Einheit mpg";
CM_ SG_ 1321 MA4_Tankzyklus "0 = letzter Tankzyklus
1 = aktueller Tankzyklus";
CM_ SG_ 1321 MA4_Strecke_TZ "3FFF - Ungueltig -> Anzeige lt. HMI-Sezifikation
Der Wert gilt in Verbindung mit dem Signal MA5_Tankzyklus f. aktuellen/letzten Tankzyklus
Wert wird in eingestellter Einheit uebertragen (mls oder km)
Fahrstrecke im Tankzyklus";
CM_ SG_ 1321 MA4_km_Strecke "1 = Einheit km
Fahrstrecke in Einheit km";
CM_ SG_ 1321 MA4_mls_Strecke "1 = Einheit mls
Fahrstrecke in Einheit mls";
CM_ SG_ 1321 MA4_Geschw "Durchschnittsgeschwindigkeit im Tankzyklus
gilt in Verbindung mit dem Signal MA5_Tankzyklus";
CM_ SG_ 1321 MA4_kmh_Geschw "1 = Einheit km/h";
CM_ SG_ 1321 MA4_mph_Geschw "1 = Einheit mph";
CM_ SG_ 1323 MA5_Lenkzeit "3FFF - Ungueltig -> Anzeige lt. HMI-Sezifikation
Lenkzeit wird nach Kl. 15 aus fuer > 10 min. auf 0 gesetzt
Lenkzeit ohne Pause in min.";
CM_ SG_ 1323 MA5_Tankrestzeit "3FFF - Ungueltig -> Anzeige lt. HMI-Sezifikation
Empfohlene Restlenkzeit bis zum naechsten Tanken in min.";
CM_ SG_ 1323 MA5_Strecke_Langzeit "3FFFFF - Ungueltig
Fahrstrecke";
CM_ SG_ 1323 MA5_km_Kilometerstand "1= Kilometerstand wird in km dargestellt
Einheit km";
CM_ SG_ 1323 MA5_mls_Kilometerstand "1 = Kilometerstand wird in Meilen dargestellt
Einheit mls";
CM_ SG_ 1475 ML1_Ziel_ "Zieladresse des Botschaftempfaengers
Zieladresse fuer das Tastensymbol";
CM_ SG_ 1475 ML1_Befehl_ "Byte analog zu MFT_Tasten, Byte1
Befehlscode";
CM_ SG_ 1473 MLT_Symbol "Code zugeordnet nach Symbolaufdruck
Botschaftsverlaengerung nur bei Senden des KeyReleaseCode (0hex)
BAF bedeutet: bei Betaetigung einer Taste oder der Walze.
Hier werden ab PQ 35 auch die MFA-Tasten uebertragen";
CM_ SG_ 1473 MLT_DW_Ticks "Es wird die Anzahl der Walzenticks zwischen 2 Abtastungen der Walze ausgegeben. Bei Walzendrehung wird in Byte 1 der Tastensymbolcode 0(hex) ausgegeben.";
CM_ SG_ 1473 MLT_DW_VZ "0=pos.=aufwaerts
1=neg.=abwaerts
Drehrichtungsanzeige";
CM_ SG_ 1473 MLT_Tickzaehler_1 "Tickzähler für Rändelräder, wird zusammen mit dem entsprechende Symbolcode ausgewertet. Überlaufender Zähler, bei positiver Drehrichtung wird der Zähler erhöht, bei negativer Drehrichtung verkleinert. Nach Reset/Power up/LIN Wakeup startet der Zähler mit ";
CM_ SG_ 1473 MLT_Tickzaehler_2 "Vorhalt fuer zukuenftige Funktionen!
Walzenzähler für Symbolcode_2";
CM_ SG_ 1473 MLT_Marke "0 = VW
1=AU
2 = SE
3 = SK
4 = VN
5 = Bugatti
6 = Lamborghini
7 = Bentley
8 = Rolls Royce
14 = Ford
15 = Porsche
Fahrzeughersteller nach Kenntnisstand des Senders";
CM_ SG_ 1473 MLT_Variante "Variante für unterschiedliche Tasten / Tastenbelegungen verschiedener MFL";
CM_ SG_ 1481 MFS_Taste_Info "Zyklische Versendung nur bei gedrueckten Tasten
Info-Taste gedrueckt";
CM_ SG_ 1481 MFS_Taste_EinAus "Max. Reaktionszeit: 20 ms
Ein/Aus-Taste gedrueckt";
CM_ SG_ 1481 MFS_Taste_Stau "Nachlauf nach Loslassen: 5 Telegramme
Stau-Taste gedrueckt";
CM_ SG_ 1481 MFS_Taste_Return "Ticks werden nur bei dem ersten Telegramm mitgesendet
Return-Taste gedrueckt";
CM_ SG_ 1481 MFS_Taste_Telematik "Telematik-Taste gedrueckt";
CM_ SG_ 1481 MFS_Taste_Enter "Drehgeber-Taste gedrueckt";
CM_ SG_ 1481 MFS_Taste_Menue "Aktivierung Kombi-Menue
Menue-Taste gedrueckt";
CM_ SG_ 1481 MFS_Prioritaet "Hiermit wird die Geraetetypnummer uebermittelt, die gerade in der Anzeige ist. NSL = 59; Kombi = 8; TM = wird noch festgelegt
Prioritaet der zugeordneten Komponente";
CM_ SG_ 1481 MFS_Anzahl_Ticks "Anzahl der waehrend der letzten Zykluszeit angefallenen Drehgeberticks. Neg = Drehgeberticks links; Pos = Drehgeberticks rechts.";
CM_ BO_ 1365 "CAN-Komfort 100ms";
CM_ SG_ 1365 MO7_LL_Status "Leerlauf-Solldrehzahl wurde angehoben, weil BSG_Last, Byte 2, Bit 0 oder Energiemananager 1, Byte 1, Bit 0 gesetzt war oder eine Klimaanforderung vorlag
Rückmeldung Leerlauf-Solldrehzahl 1 für Lastmanagement";
CM_ SG_ 1365 MO7_V_Begrenz "Fehlerbit wird vom Motor-SG gesetzt, wenn dieses nicht in die Geschwindigkeits-begrenzung gehen kann, ein Fehler während der v-Begrenzung auftritt oder v > v(begr.) - v(delta)
Geschwindigkeitsbegrenzung aktivierbar";
CM_ SG_ 1365 MO7_V_Begr_akt "Motor begrenzt aktuell die Geschwindigkeit des Fahrzeugs; Reaktion auf externe oder interne Anforderung
Statusbit Geschwindigkeitsbegrenzung aktiv";
CM_ SG_ 1365 MO7_FehlerSp "Bei gesetztem Bit ist mindestens ein Kundendienstfehler eingetragen";
CM_ SG_ 1365 MO7_Fehler_Oel_Temp "n.i.O. steht für Fehlerwert, außerhalb des Meßbereichs (ungenau), nicht verbaut oder noch kein aktueller Wert
Info aus Aufbereitung der TOG-Botschaft (nicht VW D1/Colorado, aber im Touareg GP/ D1 GP)
* Initwert 1 bei nicht verbautem Sensor oder nicht ve";
CM_ SG_ 1365 MO7_PTC "Rückmeldung für das Lastmanagement, daß die PTC / Glühstifte ausgeschaltet wurden
z. Zt nur beim Diesel gefordert (nur VW)
PTC/Glühstifte ausgeschaltet";
CM_ SG_ 1365 MO7_DFM "Meßwert Tastverhältnis DFM-Signal
(Nicht Audi D3 / C6!) (bei umgesetzter neuer Generatorschnittstelle wird das Signal im Colorado GP, D1GP/BY61x und Phaeton ab MJ07 nicht mehr bedient (abhängig vom Motor-Projekt))
Klemme_DFM";
CM_ SG_ 1365 MO7_Hoeheninfo "Korrekturfaktor Höhe (1 entspricht 1013 mbar; 0,9 entspricht 1000m; 0,8 entspricht 2000m; 1,1 entspricht -1000m)";
CM_ SG_ 1365 MO7_Gradient_Drehz "Differenz der Motordrehzahlen n(t) - n(t-20msec) aus der CAN-Botschaft 'Motor 1'
Motordrehzahlgradient";
CM_ SG_ 1365 MO7_Gradient_Vorz "Positiv steht für steigende Drehzahl; Negativ für fallende Drehzahl
Vorzeichen Motordrehzahlgradient";
CM_ SG_ 1365 MO7_Ladedruckneu "Zur Anzeige im Kombi (z.Zt. nur Porsche Colorado, PQ35 Bi-Turbo, Audi RS6, TT-R)
Kombi im PQ35-Bi-Turbo und Audi RS6 und TT-R interpretiert die normierten CAN-Werte (0-254) als 0-100% der Anzeigeskala
(Änderung Wertebereich für PQ35/46 mit V5.1.6 und Ne";
CM_ SG_ 1365 MO7_GenLoadResp "Dient der Vermeidung der vom Generator erzeugten, mechanischen Lastsprüngen und Leerlaufschwankungen durch trägere Ausregelung. Diese Massnahme darf nur kurzfristig bzw. als Notlauf wirksam sein (nicht VW D1/Colorado und PQ35/46).
Generator_Load_Response";
CM_ SG_ 1365 MO7_PTC_bereit "Bereitschaft dreistufiges PTC !!! (im AU716 und C6 ab 22/08)
Bereitschaft PTC-Heizung";
CM_ SG_ 1365 MO7_Mot_weckfaehig "Anhand dieses Signals lernt das BSG, ob es zukünftig bei bestimmten Ereignissen (Türkontakt, Anforderung Standheizung) über das Gateway das Wecken des Antriebs-CANs initieren soll. (nicht Audi)
Motor weckfähig über CAN";
CM_ SG_ 1365 MO7_Zus_Kuehl "Zur Unterstützung der Motorkühlung fordert Motor von Klima oder Zusatzheizung die Schaltung des Heizwasserkreislauf-Bypasses an (z. Zt. nur im Colorado V10 TDI)
Zusätzliche Kühlung";
CM_ SG_ 1365 MO7_Sleep_Ind "Die Sleep-Bereitschaft wird nach Klemme 15 aus durch Setzen dieses Bits signalisiert
NMHigh-Teilnehmer der PQ35/46 müssen das Signal nach Kl.-15 aus weiterhin bedienen oder dauerhaft auf 1 = 'Sleep bereit' setzen!";
CM_ SG_ 1365 MO7_Rueck_LLDz "Leerlauf-Solldrehzahl wurde aufgrund einer Lastmanagement-Anforderung (BSG_Last Byte 1, Bit 5 oder Energiemanager 1, Byte 1, Bit 1) auf die zweite Stufe angehoben
(nicht VW D1/Colorado)
Rueckmeldung_Leerlauf-Solldrehzahl 2";
CM_ SG_ 1365 MO7_Last_abwurf "Anforderung eines Lastabwurfs (für Notlauf):
Stufe 0: Keine Reduktion der Generatorspannung
Stufe 1: Generatorspannung = 13,3V
Stufe 2: Generatorspannung = 12,6V
Stufe 3: Generatorspannung = 11,8V
Anmerkung: Stufe 3 nur für äußersten Notfall!
Schalt";
CM_ SG_ 1365 MO7_Ein_Generator "Einschalten des Generators nach Motorstart. Einschalten evtl. mit Load-Response.
Anmerkung: Solange der Generator ausgeschaltet ist, bleiben auch die Hochleistungsheizsysteme deaktiviert. Spätestens 5 s nach Motorstart wird der Generator zugeschaltet una";
CM_ SG_ 1365 MO7_Lastabwurf_Heiz "Lastabwurf der Hochleistungsheizsysteme (z.B. Abschaltung von Frontscheibenheizung, PTC-Heizung und Heckscheibenheizung nach Motorstart und im Notfall).
Anmerkung: Der Lastabwurf der Hochleistungs-heizsysteme wird auch bei reduzierter Generatorspannung d";
CM_ SG_ 1365 MO7_Stat_Gluehk "Einschaltzustand der Gluehkerzenheizung in Prozent (nicht VW D1/Colorado)
Gluehkerzen_Brennraum";
CM_ SG_ 1365 MO7_Oeltemperatur "realer Meßbereich ca. -40..150 Grad
0 für nicht verbaut
Info aus Aufbereitung der TOG-Botschaft (nicht VW D1/Colorado, aber im Touareg GP/D1 GP)
Öltemperatur";
CM_ SG_ 1420 M10_Anzeige "0 keine Anzeige

Start/Stopp:
1 Anzeige 'Start-Stopp aktiv'
2 Anzeige (VW ID_TXT_2022.1) 'Systemfehler Start-Stopp'
3 Anzeige (VW ID_TXT_2022.0) 'Motor manuell starten'
4 tbd
5 Anzeige 'Motorlauf nötig'
6..8 tbd
9 Anzeige 'Unerwünschter Motorstil";
CM_ SG_ 1420 M10_Anf_Kl75 "Anforderung an das BSG/BCM bei Konzepten mit Startersteuerung durch das MSG: Beim Erststart fordert das MSG mit diesem Signal das Ausschalten der KL75-Verbraucher an. (Bei einem Wiederstart innerhalb der Start-Stopp-Funktionalität bleib das Signal gesetzt";
CM_ SG_ 1420 M10_SpannungsAnf "Forderung des Motor-SGs zur Spannungsanhebung";
CM_ SG_ 1420 M10_UDruckDyn "0 = Der Saugrohrunterdruckwert überstieg mind. einmal mehr als 50mbar (in Richtung Vakuum), bezogen auf den höchsten Saugrohrunterdruckwert aus der aktuellen und letzen CAN-Ausgabe (siehe mMotor_10, Byte 3, Bit 5..0).
1 = Der Saugrohrunterdruckwert war i";
CM_ SG_ 1420 M10_Status_StSt "Systemstatus des Start-Stopp-Koordinators
0 = System in diesem Kl15 Zyklus nicht verfügbar (Sicherheitsabschaltung, Sensorfehler erkannt, Funktion nicht implementiert)
1 = Abschaltung über Hauptschalter
2 = System aktiv, Motorlauf nicht notwendig (Frei";
CM_ SG_ 1420 M10_MotorStopp "Motor-Stopp durch Start-Stopp-Koordinator. Das Signal wird nur bei einem Motorstopp durch den Start-Stopp-Koordinator gesetzt. Bei Abwürgen des Motors oder nach Abstellen des Motors über KL15 (Nachlauf) bleibt das Signal inaktiv.
Stopp-Modus aktiv wird e";
CM_ SG_ 1420 M10_Wiederstart "Motorwiederstart durch Start-Stopp-Koordinator. 'Wiederstart aktiv' wird vom Koordinator gesetzt sobald der Wiederstart angetriggert wird und bleibt bis zum Startende gesetzt. (bleibt beim Erststart 0)";
CM_ SG_ 1420 M10_Schubabschaltung "ESP plausibilisiert Unterdrucksensor nur bei aktiver Schubabschaltung
Schubabschaltung";
CM_ SG_ 1420 M10_Druck_err_gem "0: mind. eine Modellrechnung wird zur Berechnung des relativen Saugrohrdrucks (Byte 3, Bit 5..0) herangezogen.
1: Relativer Saugrohrdruck wird ausschließlich über Messgrößen bestimmt.
Rel. Saugrohrdruck errechnet/gemessen";
CM_ SG_ 1420 M10_Freigabe_Reku "Empfehlung des Motor-SG's zur Spannungsabsenkung/-anhebung für den Rekuperationsbetrieb (PQ25, PQ35/46, AU210, C6, AU716, Hybrid-Projekte)
Freigabe Rekuperation";
CM_ SG_ 1420 M10_rel_Saugrohrdruck "Der Wert gibt an, um wieviel mbar der Saugrohrdruck unterhalb des Umgebungsdrucks liegt. Überdruck im Saugrohr wird nicht ausgegeben.
0: Saugrohrdruck >= Umgebungsdruck
Relativer Saugrohrdruck";
CM_ SG_ 1420 M10_Fahrbereitschaft "Signal steuert u.a. in der Lenkhilfe zusammen mit weiteren Informationen den Modewechsel in den 'Drivemode'
Fahrbereitschaft";
CM_ SG_ 1420 M10_Hybrid "Anhand dieses Signals plausibilisiert die Lenkhilfe das Bit Fahrbereitschaft
Hybrid";
CM_ SG_ 1420 M10_EM_aktiv "für Kombiinstrument zur Steuerung der Anzeigen und Auswertung (z.B. Reichweite, DÖW usw.)
E-Motor aktiv";
CM_ SG_ 1420 M10_VM_aktiv "für Kombiinstrument zur Steuerung der Anzeigen und Auswertung (z.B. Reichweite, DÖW usw.)
V-Motor aktiv";
CM_ SG_ 1420 M10_HYB_Bereitlampe "grüne Anzeige im Kombiinstrument zur Signalisierung der Bereitschaft des Hybridsystems
Lampe Hybrid-Bereitschaft";
CM_ SG_ 1420 M10_HYB_Warnlampe "gelbe Anzeige im Kombiinstrument zur Signalisierung der Warnmeldung des Hybridsystems
Lampe Hybrid-Warnung";
CM_ SG_ 1420 M10_HYB_Fehlerlampe "rote Anzeige im Kombiinstrument zur Signalisierung der Sicherheitsmeldung des Hybridsystems
Lampe Hybrid-Fehler";
CM_ SG_ 1420 M10_Fehler_HV_Netz "Im HV-Bordnetz ist fehlerbedingt kein generatorischer Betrieb möglich. Das 12V-Bordnetz wird über den DC/DC-Wandler allein aus der Traktionsbatterie gespeist. Um diesen Zustand möglichst lange aufrechterhalten zu können, sollten Komfort-Verbraucher abgesc";
CM_ SG_ 1420 M10_EKlKomLeiRed "Anforderung an die Klimasteuerung, die Leistungsaufnahme des E-Kompressors bei schlechtem SOC und in bestimmten Fahrsituationen zu begrenzen.
(Das bereits bestehende Signal 'Klimakompressor aus' Motor5, Byte2, Bit5 als stets umzusetzende Anforderung blei";
CM_ SG_ 1420 M10_Klimadruck "Drucksensor am Motor-SG (China Modell X/Y)";
CM_ SG_ 1420 M10_KompAusCode "Abschaltbedingungen im Motor für den Klimakompressor (China Modell X/Y)
Kompressor-Aus-Code";
CM_ SG_ 1420 M10_StartStopp_Fahrerwunsch "Fahreraktivität Start/Stopp";
CM_ SG_ 1420 M10_Akustik "Anforderung einer Akustikwarnung im Kombi (durch Hybrid- oder Start/Stopp-Koordinator)
0 = keine Akustik
1 = Akustik 1 (Gong 1000 bei VW)
2 = Akustik 2 (3xSummer2000 bei VW)
3 = frei";
CM_ SG_ 1420 M10_Text_1_Hybrid "Text 1 (ID_TXT_1024.1): Fehler Hybridsystem Werkstatt aufsuchen (Kategorie 1)";
CM_ SG_ 1420 M10_Text_2_Hybrid "Text 2 (ID_TXT_1025.1): Fehler Hybridsystem Werkstatt aufsuchen (Kategorie 2)";
CM_ SG_ 1420 M10_Text_3_Hybrid "Text 3 (ID_TXT_1025.2): Warten. HV-Batterie wird geladen. Bordbuch";
CM_ SG_ 1420 M10_Text_4_Hybrid "Text 4 (ID_TXT_1025.3): Bordnetzunterspannung Bordbuch";
CM_ SG_ 1420 M10_Text_5_Hybrid "Text 5 (ID_TXT_1025.4): Anlasser länger betätigen!";
CM_ SG_ 1420 M10_Text_6_Hybrid "Text 6 Hybrid";
CM_ SG_ 1420 M10_Text_7_Hybrid "Text 7 Hybrid";
CM_ SG_ 1420 M10_Text_8_Hybrid "Text 8 Hybrid";
CM_ SG_ 1420 M10_ShiftLockLampe "Bei Automatikstart/Startersteuerung im MSG: In Automatik-Fahrzeugen ist Betätigen der Bremse Freigabebedingung für den Startwunsch. (ergänzend/alternativ zur Textanzeige)";
CM_ SG_ 1420 M10_BMSInfo_gue "Die vom MSG aus dem Hybrid-CAN gespiegelten Daten 'M10_VentilationReq' und 'M10_BattFanSpd' sind gültig (Botschaften vom Hybrid-CAN vor weniger als 1000ms empfangen).
BMS Hybrid Info gültig";
CM_ SG_ 1420 M10_VentilationReq "BMS fordert bei Climatronic die Öffnung der Umluftklappe an. Signal wird vom MSG von Hybrid-CAN auf den A-CAN gespiegelt (mBMS_HYB_6, Byte 8, Bit 1 aus Hybrid-CAN DF > V1.5)";
CM_ SG_ 1420 M10_BattFanSpd "Relativwert der Batterielüfter-Ansteuerung bezogen auf Maximalwert. Signal wird vom MSG von Hybrid-CAN auf den A-CAN gespiegelt
(mBMS_HYB_3, Byte 7, Bit 7..4 aus Hybrid-CAN DF > V1.5)";
CM_ SG_ 1540 NV1_NAV_On "Festlegung von Statuscodes und Parametern erfolgt in separater Tabelle.
Navigation Einschaltzustand";
CM_ SG_ 1540 NV1_NAV_mute "Mute On/Off";
CM_ SG_ 1540 NV1_NAV_Error_flag "Fehlereintrag vorhanden";
CM_ SG_ 1540 NV1_NAV_Mode "siehe Spezifikation Mode-Codierung
Mode-Information";
CM_ SG_ 1540 NV1_NAV_Para1 "Parameter des jew. Modes";
CM_ SG_ 1540 NV1_NAV_Para2 "Parameter des jew. Modes";
CM_ SG_ 1540 NV1_NAV_Para3 "Parameter des jew. Modes";
CM_ SG_ 1540 NV1_NAV_Para4 "Parameter des jew. Modes";
CM_ SG_ 1540 NV1_NAV_Para5 "Parameter des jew. Modes";
CM_ SG_ 1540 NV1_NAV_Para6 "Parameter des jew. Modes";
CM_ SG_ 1441 ND_Init "Initialisierung";
CM_ SG_ 1441 ND_ErrorTime "Error UTC-Time";
CM_ SG_ 1441 ND_ErrorDate "Error UTC-Date";
CM_ SG_ 1441 ND_ErrorRestentf "Error Restentfernung";
CM_ SG_ 1441 ND_ErrorHeading "Error Heading";
CM_ SG_ 1441 ND_ErrorSpeed "Error Speed";
CM_ SG_ 1441 ND_KM "Einheiteneinstellung KM/h/ MPH
1= Kilometer
0= Miles";
CM_ SG_ 1441 ND_AMPM "Zeiteinstellung
1= AM
0= PM";
CM_ SG_ 1441 ND_Stunde "UTC-Stunden 0-12";
CM_ SG_ 1441 ND_Minuten "UTC-Minuten 0-59";
CM_ SG_ 1441 ND_Sekunden "UTC-Sekunden 0-59";
CM_ SG_ 1441 ND_Year "UTC-Year 0-99";
CM_ SG_ 1441 ND_Month "UTC-Month 1...12";
CM_ SG_ 1441 ND_Day "UTC-Day 1...31";
CM_ SG_ 1441 ND_Restentfernug "Restentfernung bis zum eingegebenen Ziel";
CM_ SG_ 1441 ND_Heading "Heading";
CM_ SG_ 1441 ND_Speed "Speed";
CM_ SG_ 673 NV1_Gierrate "3FFFh = ungueltig
Gierrate";
CM_ SG_ 673 NV1_Fehler_Gierrate "1 = Gierratenfehler liegt vor";
CM_ SG_ 673 NV1_VZ_Gierrate "0 = neg
1 = pos
Vorzeichen Gierrate (+/-)";
CM_ SG_ 673 NV1_Laenderkennung "33=F
44=UK
49=D
FFh = ungueltig
etc...
Vgl. MS Win95 Spec.
Laenderkennung";
CM_ SG_ 673 NV1_Strassentyp "0=Hauptstr. (Autobahn, Kraftfahrstr..)
1=Einspurige Str. (Bundesstr.)
2=Innerstaedtische Str.
0xF = Fehler oder keine Info
Strassentyp";
CM_ SG_ 673 NV1_Anz_Fahrbahnen "0 = Fehler
Anzahl Fahrbahnen (0 ist ungueltig)";
CM_ SG_ 673 NV1_Fehler_Daten "1 = Keine gueltigen Navigationsdaten verfuegbar
Fehler Navigationsdaten";
CM_ SG_ 673 NV1_Kurvenverlauf "7F = keine Kurve erkannt oder Fehler
Vorausliegender Kurvenverlauf";
CM_ SG_ 673 NV1_Kurvenrichtg "0=Linkskurve
1=Rechtskurve
Voarusliegende Kurvenrichtung";
CM_ SG_ 673 NV1_Entf_Kurve "FF = keine Kurve erkannt oder Fehler
Entfernung bis Kurvenanfang";
CM_ SG_ 673 NV1_Entf_Krzg "3F = keine Kreuzung erkannt oder Fehler
Entfernung bis Kreuzung";
CM_ SG_ 673 NV1_Krzg_Typ "00=Keine Kreuzung im Fangbereich
01=Str. v. links
10=Str. v. Rechts
11=Strassen von beiden Seiten
Kreuzungstyp";
CM_ SG_ 1455 NV2_Reststrecke "Strecke bis zum Ziel in m
Byte 1: LSB
Byte 3: MSB
FFFFFFh = Wert nicht verfuegbar, keine Zielfuehrung aktiv";
CM_ SG_ 1455 NV2_Restzeit "Fahrzeit bis zum Ziel in Minuten
Byte 1: LSB
Byte 2: MSB
FFFFh = Wert nicht verfuegbar, keine Zielfuehrung aktiv";
CM_ SG_ 1443 NP_Degree "Latitude (Nord-Süd Wert)";
CM_ SG_ 1443 NP_Richtung_NS "00=Nord
01=Süd
10=Ost
11=West";
CM_ SG_ 1443 NP_Minuten_NS "Grad in Minuten";
CM_ SG_ 1443 NP_MinFraction_NS "Min. Fraction";
CM_ SG_ 1443 NP_Degree_OW "Longitude (Ost-West Wert)";
CM_ SG_ 1443 NP_Richtung_OW "00=Nord
01=Süd
10_Ost
11=West";
CM_ SG_ 1443 NP_Minuten_OW "Grad in Minuten";
CM_ SG_ 1443 NP_MinFraction_OW "Min. Fraction";
CM_ SG_ 1443 NP_Fix "00=Init
01=No Fix
10=2D Fix
11=3D Fix";
CM_ SG_ 1443 NP_GDOP "GDOP
1.0+Value/10  =>  1.0...4.2
";
CM_ SG_ 1443 NP_Altitude "Hoehe ueber NN";
CM_ SG_ 1071 NMDAB_Receiver "Digitaler Radio Tuner (SDARS oder DAB)
SG_Adresse";
CM_ SG_ 1071 NMDAB_CmdRing "Ring Message";
CM_ SG_ 1071 NMDAB_CmdAlive "Alive Message";
CM_ SG_ 1071 NMDAB_CmdLimpHome "Limp Home Message";
CM_ SG_ 1071 NMDAB_SleepInd "BusSleep Indication";
CM_ SG_ 1071 NMDAB_SleepAck "BusSleep Acknowledge";
CM_ SG_ 1071 NMDAB_Kl_30_Reset "Weckursache: Klemme 30 Reset";
CM_ SG_ 1071 NMDAB_Fkt_Nachlauf "Weckursache: Ablauf Timer Funktionsnachlauf";
CM_ SG_ 1071 NMDAB_NWake "Weckursache: NWake-Eingang";
CM_ SG_ 1071 NMDAB_CAN "Weckursache: CAN";
CM_ SG_ 1071 NMDAB_Klemme_15 "Weckursache: Klemme 15=ein";
CM_ SG_ 1071 NMDAB_WakeUp2 "n.n.";
CM_ SG_ 1071 NMDAB_WakeUp3 "n.n.";
CM_ SG_ 1067 NMGW_I_Receiver "SG_Adresse";
CM_ SG_ 1067 NMGW_I_CmdRing "Ring Message";
CM_ SG_ 1067 NMGW_I_CmdAlive "Alive Message";
CM_ SG_ 1067 NMGW_I_CmdLimpHome "Limp Home Message";
CM_ SG_ 1067 NMGW_I_SleepInd "BusSleep Indication";
CM_ SG_ 1067 NMGW_I_SleepAck "BusSleep Acknowledge";
CM_ SG_ 1067 NMGW_I_Kl_30_Reset "Weckursache: Klemme 30 Reset";
CM_ SG_ 1067 NMGW_I_Fkt_Nachlauf "Weckursache: Ablauf Timer Funktionsnachlauf";
CM_ SG_ 1067 NMGW_I_NWake "Weckursache: NWake-Eingang";
CM_ SG_ 1067 NMGW_I_CAN "Weckursache: CAN";
CM_ SG_ 1067 NMGW_I_Wake_Up_Ltg "Weckursache: Kombi Wake-Up Leitung";
CM_ SG_ 1067 NMGW_I_Komfort_CAN "Wecken durch Komfort CAN";
CM_ SG_ 1067 NMGW_I_Info_CAN "Wecken durch Infotainment CAN";
CM_ SG_ 1067 NMGW_I_Kl_15 "Wecken durch Klemme 15";
CM_ SG_ 1067 NMGW_I_Diag_CAN "Wecken durch Diagnose CAN";
CM_ SG_ 1067 NMGW_I_LIN1 "Wecken durch LIN#1";
CM_ SG_ 1067 NMGW_I_LIN2 "Wecken durch LIN#2";
CM_ SG_ 1067 NMGW_I_WakeUp2 "n.n.";
CM_ SG_ 1067 NMGW_I_WakeUp3 "n.n.";
CM_ SG_ 1064 NMGSM_Receiver "SG_Adresse";
CM_ SG_ 1064 NMGSM_CmdRing "Ring Message";
CM_ SG_ 1064 NMGSM_CmdAlive "Alive Message";
CM_ SG_ 1064 NMGSM_CmdLimpHome "Limp Home Message";
CM_ SG_ 1064 NMGSM_SleepInd "BusSleep Indication";
CM_ SG_ 1064 NMGSM_SleepAck "BusSleep Acknowledge";
CM_ SG_ 1064 NMGSM_Kl_30_Reset "Weckursache: Klemme 30 Reset";
CM_ SG_ 1064 NMGSM_Fkt_Nachlauf "Weckursache: Ablauf Timer Funktionsnachlauf";
CM_ SG_ 1064 NMGSM_NWake "Weckursache: NWake-Eingang";
CM_ SG_ 1064 NMGSM_CAN "Weckursache: CAN";
CM_ SG_ 1064 NMGSM_Klemme_15 "Wecksursache: Klemme 15 = ein";
CM_ SG_ 1064 NMGSM_WakeUp2 "n.n.";
CM_ SG_ 1064 NMGSM_WakeUp3 "n.n.";
CM_ SG_ 1076 NMKOMP_Receiver "SG_Adresse";
CM_ SG_ 1076 NMKOMP_CmdRing "Ring Message";
CM_ SG_ 1076 NMKOMP_CmdAlive "Alive Message";
CM_ SG_ 1076 NMKOMP_CmdLimpHome "Limp Home Message";
CM_ SG_ 1076 NMKOMP_SleepInd "BusSleep Indication";
CM_ SG_ 1076 NMKOMP_SleepAck "BusSleep Acknowledge";
CM_ SG_ 1076 NMKOMP_Kl_30_Reset "Weckursache: Klemme 30 Reset";
CM_ SG_ 1076 NMKOMP_Fkt_Nachlauf "Weckursache: Ablauf Timer Funktionsnachlauf";
CM_ SG_ 1076 NMKOMP_NWake "Weckursache: NWake-Eingang";
CM_ SG_ 1076 NMKOMP_CAN "Weckursache: CAN";
CM_ SG_ 1076 NMKOMP_WakeUp2 "n.n.";
CM_ SG_ 1076 NMKOMP_WakeUp3 "n.n.";
CM_ SG_ 1084 NMSBS_Receiver "Sprachbedienung am Infotainment
SG_Adresse";
CM_ SG_ 1084 NMSBS_CmdRing "Ring Message";
CM_ SG_ 1084 NMSBS_CmdAlive "Alive Message";
CM_ SG_ 1084 NMSBS_CmdLimpHome "Limp Home Message";
CM_ SG_ 1084 NMSBS_SleepInd "BusSleep Indication";
CM_ SG_ 1084 NMSBS_SleepAck "BusSleep Acknowledge";
CM_ SG_ 1084 NMSBS_Kl_30_Reset "Weckursache: Klemme 30 Reset";
CM_ SG_ 1084 NMSBS_Fkt_Nachlauf "Weckursache: Ablauf Timer Funktionsnachlauf";
CM_ SG_ 1084 NMSBS_NWake "Weckursache: NWake-Eingang";
CM_ SG_ 1084 NMSBS_CAN "Weckursache: CAN";
CM_ SG_ 1084 NMSBS_Klemme_15 "Weckursache: Klemme 15=ein";
CM_ SG_ 1084 NMSBS_WakeUp2 "n.n.";
CM_ SG_ 1084 NMSBS_WakeUp3 "n.n.";
CM_ SG_ 1063 NMSHI_Receiver "SG_Adresse";
CM_ SG_ 1063 NMSHI_CmdRing "Ring Message";
CM_ SG_ 1063 NMSHI_CmdAlive "Alive Message";
CM_ SG_ 1063 NMSHI_CmdLimpHome "Limp Home Message";
CM_ SG_ 1063 NMSHI_SleepInd "BusSleep Indication";
CM_ SG_ 1063 NMSHI_SleepAck "BusSleep Acknowledge";
CM_ SG_ 1063 NMSHI_Kl_30_Reset "Weckursache: Klemme 30 Reset";
CM_ SG_ 1063 NMSHI_Fkt_Nachlauf "Weckursache: Ablauf Timer Funktionsnachlauf";
CM_ SG_ 1063 NMSHI_NWake "Weckursache: NWake-Eingang";
CM_ SG_ 1063 NMSHI_CAN "Weckursache: CAN";
CM_ SG_ 1063 NMSHI_Funk "Weckursache: Funkempfang";
CM_ SG_ 1063 NMSHI_Geblaese "Weckursache: Geblaeseanforderung ein/aus";
CM_ SG_ 1063 NMSHI_Fehlerabschaltung "Weckursache : Fehlerabschaltung";
CM_ SG_ 1063 NMSHI_Vorlauf_S_A "Weckursache: Vorlauf Sensor_Aktor, z.B. Schwallrtopfpumpe
Vorlauf Sensoren oder Aktoren";
CM_ SG_ 1063 NMSHI_WakeUp2 "n.n.";
CM_ SG_ 1063 NMSHI_WakeUp3 "n.n.";
CM_ SG_ 1062 NMTASTATUR_Receiver "Tastatur am Infotainment
SG_Adresse";
CM_ SG_ 1062 NMTASTATUR_CmdRing "Ring Message";
CM_ SG_ 1062 NMTASTATUR_CmdAlive "Alive Message";
CM_ SG_ 1062 NMTASTATUR_CmdLimpHome "Limp Home Message";
CM_ SG_ 1062 NMTASTATUR_SleepInd "BusSleep Indication";
CM_ SG_ 1062 NMTASTATUR_SleepAck "BusSleep Acknowledge";
CM_ SG_ 1062 NMTASTATUR_Kl_30_Reset "Weckursache: Klemme 30 Reset";
CM_ SG_ 1062 NMTASTATUR_Fkt_Nachlauf "Weckursache: Ablauf Timer Funktionsnachlauf";
CM_ SG_ 1062 NMTASTATUR_NWake "Weckursache: NWake-Eingang";
CM_ SG_ 1062 NMTASTATUR_CAN "Weckursache: CAN";
CM_ SG_ 1062 NMTASTATUR_Klemme_15 "Weckursache: Klemme 15=ein";
CM_ SG_ 1062 NMTASTATUR_Betaetigung "Weckursache Tastenbetätigung";
CM_ SG_ 1062 NMTASTATUR_WakeUp2 "n.n.";
CM_ SG_ 1062 NMTASTATUR_WakeUp3 "n.n.";
CM_ SG_ 1085 NMTM_I_Receiver "Telematik am Infotainment
SG_Adresse";
CM_ SG_ 1085 NMTM_I_CmdRing "Ring Message";
CM_ SG_ 1085 NMTM_I_CmdAlive "Alive Message";
CM_ SG_ 1085 NMTM_I_CmdLimpHome "Limp Home Message";
CM_ SG_ 1085 NMTM_I_SleepInd "BusSleep Indication";
CM_ SG_ 1085 NMTM_I_SleepAck "BusSleep Acknowledge";
CM_ SG_ 1085 NMTM_I_Kl_30_Reset "Weckursache: Klemme 30 Reset";
CM_ SG_ 1085 NMTM_I_Fkt_Nachlauf "Weckursache: Ablauf Timer Funktionsnachlauf";
CM_ SG_ 1085 NMTM_I_NWake "Weckursache: NWake-Eingang";
CM_ SG_ 1085 NMTM_I_CAN "Weckursache: CAN";
CM_ SG_ 1085 NMTM_I_inCall "in Verbindung mit CDC oder DSP-Verstaerker
Bei eingehendem Anruf wird der Bus geweckt, um Sprachausgabe auf Lautsprecher aktivieren zu koeennen.
Weckursache: new Vinfo";
CM_ SG_ 1085 NMTM_I_f_diag "Weckursache: Ferndiagnose";
CM_ SG_ 1085 NMTM_I_Klemme_15 "Weckursache: Klemme 15 = ein";
CM_ SG_ 1085 NMTM_I_WakeUp2 "n.n.";
CM_ SG_ 1085 NMTM_I_WakeUp3 "n.n.";
BA_DEF_ BO_  "GenMsgAutoGenDsp" ENUM  "No","Yes";
BA_DEF_ BO_  "GenMsgAutoGenSnd" ENUM  "No","Yes";
BA_DEF_ BO_  "GenMsgCycleTime" INT 0 65535;
BA_DEF_ BO_  "GenMsgCycleTimeFast" INT 0 65535;
BA_DEF_ BO_  "GenMsgDelayTime" INT 0 100000;
BA_DEF_ BO_  "GenMsgILSupport" ENUM  "No","Yes";
BA_DEF_ BO_  "GenMsgNrOfRepetition" INT 0 100;
BA_DEF_ BO_  "GenMsgSendType" ENUM  "Cyclic","not_used","not_used","not_used","not_used","not_used","not_used","IfActive","NoMsgSendType";
BA_DEF_ BO_  "GenMsgStartDelayTime" INT 0 100000;
BA_DEF_ BO_  "NmMessage" ENUM  "No","Yes";
BA_DEF_ BO_  "NmhMessage" ENUM  "No","Yes";
BA_DEF_ BO_  "VAGTP20_API" HEX 0 255;
BA_DEF_ BO_  "VAGTP20_DynConnection" ENUM  "No","Yes";
BA_DEF_ BO_  "VAGTP20_DynSetup" ENUM  "No","Yes";
BA_DEF_ BO_  "VAGTP20_StatConnection" ENUM  "No","Yes";
BA_DEF_ BO_  "DiagRequest" ENUM  "No","Yes";
BA_DEF_ BO_  "DiagResponse" ENUM  "No","Yes";
BA_DEF_ BO_  "DiagState" ENUM  "No","Yes";
BA_DEF_ SG_  "GenSigAutoGenDsp" ENUM  "No","Yes";
BA_DEF_ SG_  "GenSigAutoGenSnd" ENUM  "No","Yes";
BA_DEF_ SG_  "GenSigEnvVarType" ENUM  "int","float","undef";
BA_DEF_ SG_  "GenSigInactiveValue" INT -2147483648 2147483647;
BA_DEF_ SG_  "GenSigSendType" ENUM  "Cyclic","OnWrite","OnWriteWithRepetition","OnChange","OnChangeWithRepetition","IfActive","IfActiveWithRepetition","NoSigSendType","OnChangeAndIfActive","OnChangeAndIfActiveWithRepetition";
BA_DEF_ SG_  "GenSigStartValue" INT -2147483648 2147483647;
BA_DEF_ SG_  "NWM-WakeupAllowed" ENUM  "No","Yes";
BA_DEF_ SG_  "GenSigFuncType" ENUM  "NoFunction","MsgCounter","CRC-8","XOR","XOR-2","DatedBit","SW-Kl15","CHK","Constant","Protocol";
BA_DEF_ SG_  "GenSigSwitchedByIgnition" ENUM  "No","Yes";
BA_DEF_ SG_  "Fehlerwert" HEX 0 2147483647;
BA_DEF_DEF_  "GenMsgAutoGenDsp" "Yes";
BA_DEF_DEF_  "GenMsgAutoGenSnd" "Yes";
BA_DEF_DEF_  "GenMsgCycleTime" 0;
BA_DEF_DEF_  "GenMsgCycleTimeFast" 0;
BA_DEF_DEF_  "GenMsgDelayTime" 0;
BA_DEF_DEF_  "GenMsgILSupport" "No";
BA_DEF_DEF_  "GenMsgNrOfRepetition" 0;
BA_DEF_DEF_  "GenMsgSendType" "NoMsgSendType";
BA_DEF_DEF_  "GenMsgStartDelayTime" 0;
BA_DEF_DEF_  "NmMessage" "No";
BA_DEF_DEF_  "NmhMessage" "No";
BA_DEF_DEF_  "VAGTP20_API" 0;
BA_DEF_DEF_  "VAGTP20_DynConnection" "No";
BA_DEF_DEF_  "VAGTP20_DynSetup" "No";
BA_DEF_DEF_  "VAGTP20_StatConnection" "No";
BA_DEF_DEF_  "DiagRequest" "No";
BA_DEF_DEF_  "DiagResponse" "No";
BA_DEF_DEF_  "DiagState" "No";
BA_DEF_DEF_  "GenSigAutoGenDsp" "No";
BA_DEF_DEF_  "GenSigAutoGenSnd" "No";
BA_DEF_DEF_  "GenSigEnvVarType" "undef";
BA_DEF_DEF_  "GenSigInactiveValue" 0;
BA_DEF_DEF_  "GenSigSendType" "NoSigSendType";
BA_DEF_DEF_  "GenSigStartValue" 0;
BA_DEF_DEF_  "NWM-WakeupAllowed" "No";
BA_DEF_DEF_  "GenSigFuncType" "NoFunction";
BA_DEF_DEF_  "GenSigSwitchedByIgnition" "No";
BA_DEF_DEF_  "Fehlerwert" 0;
BA_ "GenMsgCycleTime" BO_ 963 100;
BA_ "GenMsgILSupport" BO_ 963 1;
BA_ "GenMsgCycleTime" BO_ 1329 50;
BA_ "GenMsgDelayTime" BO_ 1329 10;
BA_ "GenMsgILSupport" BO_ 1329 1;
BA_ "GenMsgSendType" BO_ 1329 0;
BA_ "GenMsgCycleTime" BO_ 705 100;
BA_ "GenMsgDelayTime" BO_ 705 20;
BA_ "GenMsgILSupport" BO_ 705 1;
BA_ "GenMsgSendType" BO_ 705 0;
BA_ "GenMsgCycleTime" BO_ 1371 1000;
BA_ "GenMsgDelayTime" BO_ 1371 100;
BA_ "GenMsgILSupport" BO_ 1371 1;
BA_ "GenMsgSendType" BO_ 1371 0;
BA_ "GenMsgCycleTime" BO_ 1317 100;
BA_ "GenMsgCycleTimeFast" BO_ 1317 100;
BA_ "GenMsgILSupport" BO_ 1317 1;
BA_ "GenMsgNrOfRepetition" BO_ 1317 5;
BA_ "GenMsgSendType" BO_ 1317 7;
BA_ "GenMsgCycleTime" BO_ 1287 1000;
BA_ "GenMsgDelayTime" BO_ 1287 100;
BA_ "GenMsgILSupport" BO_ 1287 1;
BA_ "GenMsgSendType" BO_ 1287 0;
BA_ "GenMsgCycleTime" BO_ 1291 1000;
BA_ "GenMsgDelayTime" BO_ 1291 100;
BA_ "GenMsgILSupport" BO_ 1291 1;
BA_ "GenMsgSendType" BO_ 1291 0;
BA_ "GenMsgCycleTime" BO_ 1293 1000;
BA_ "GenMsgDelayTime" BO_ 1293 100;
BA_ "GenMsgILSupport" BO_ 1293 1;
BA_ "GenMsgSendType" BO_ 1293 0;
BA_ "GenMsgCycleTime" BO_ 1295 1000;
BA_ "GenMsgDelayTime" BO_ 1295 100;
BA_ "GenMsgILSupport" BO_ 1295 1;
BA_ "GenMsgSendType" BO_ 1295 0;
BA_ "GenMsgCycleTime" BO_ 1577 1000;
BA_ "GenMsgILSupport" BO_ 1577 1;
BA_ "GenMsgSendType" BO_ 1577 0;
BA_ "GenMsgCycleTime" BO_ 1579 1000;
BA_ "GenMsgILSupport" BO_ 1579 1;
BA_ "GenMsgSendType" BO_ 1579 0;
BA_ "GenMsgCycleTime" BO_ 1581 1000;
BA_ "GenMsgILSupport" BO_ 1581 1;
BA_ "GenMsgSendType" BO_ 1581 0;
BA_ "GenMsgCycleTime" BO_ 1321 1000;
BA_ "GenMsgILSupport" BO_ 1321 1;
BA_ "GenMsgSendType" BO_ 1321 0;
BA_ "GenMsgCycleTime" BO_ 1323 1000;
BA_ "GenMsgILSupport" BO_ 1323 1;
BA_ "GenMsgSendType" BO_ 1323 0;
BA_ "GenMsgCycleTime" BO_ 1475 500;
BA_ "GenMsgDelayTime" BO_ 1475 50;
BA_ "GenMsgILSupport" BO_ 1475 1;
BA_ "GenMsgSendType" BO_ 1475 0;
BA_ "GenMsgCycleTimeFast" BO_ 1473 100;
BA_ "GenMsgDelayTime" BO_ 1473 10;
BA_ "GenMsgILSupport" BO_ 1473 1;
BA_ "GenMsgNrOfRepetition" BO_ 1473 5;
BA_ "GenMsgCycleTime" BO_ 1481 50;
BA_ "GenMsgCycleTimeFast" BO_ 1481 50;
BA_ "GenMsgILSupport" BO_ 1481 1;
BA_ "GenMsgNrOfRepetition" BO_ 1481 5;
BA_ "GenMsgSendType" BO_ 1481 7;
BA_ "GenMsgCycleTime" BO_ 1365 100;
BA_ "GenMsgILSupport" BO_ 1365 1;
BA_ "GenMsgSendType" BO_ 1365 0;
BA_ "GenMsgCycleTime" BO_ 1420 100;
BA_ "GenMsgDelayTime" BO_ 1420 10;
BA_ "GenMsgILSupport" BO_ 1420 1;
BA_ "GenMsgSendType" BO_ 1420 0;
BA_ "GenMsgCycleTime" BO_ 1540 1000;
BA_ "GenMsgDelayTime" BO_ 1540 100;
BA_ "GenMsgILSupport" BO_ 1540 1;
BA_ "GenMsgSendType" BO_ 1540 0;
BA_ "GenMsgCycleTime" BO_ 1441 1000;
BA_ "GenMsgILSupport" BO_ 1441 1;
BA_ "GenMsgSendType" BO_ 1441 0;
BA_ "GenMsgCycleTime" BO_ 673 250;
BA_ "GenMsgILSupport" BO_ 673 1;
BA_ "GenMsgSendType" BO_ 673 0;
BA_ "GenMsgCycleTime" BO_ 1455 1000;
BA_ "GenMsgILSupport" BO_ 1455 1;
BA_ "GenMsgSendType" BO_ 1455 0;
BA_ "GenMsgCycleTime" BO_ 1443 1000;
BA_ "GenMsgILSupport" BO_ 1443 1;
BA_ "GenMsgSendType" BO_ 1443 0;
BA_ "GenMsgAutoGenDsp" BO_ 1071 0;
BA_ "GenMsgAutoGenSnd" BO_ 1071 0;
BA_ "NmMessage" BO_ 1071 1;
BA_ "GenMsgAutoGenDsp" BO_ 1067 0;
BA_ "GenMsgAutoGenSnd" BO_ 1067 0;
BA_ "NmMessage" BO_ 1067 1;
BA_ "GenMsgAutoGenDsp" BO_ 1064 0;
BA_ "GenMsgAutoGenSnd" BO_ 1064 0;
BA_ "NmMessage" BO_ 1064 1;
BA_ "GenMsgAutoGenDsp" BO_ 1076 0;
BA_ "GenMsgAutoGenSnd" BO_ 1076 0;
BA_ "NmMessage" BO_ 1076 1;
BA_ "GenMsgAutoGenDsp" BO_ 1084 0;
BA_ "GenMsgAutoGenSnd" BO_ 1084 0;
BA_ "NmMessage" BO_ 1084 1;
BA_ "GenMsgAutoGenDsp" BO_ 1063 0;
BA_ "GenMsgAutoGenSnd" BO_ 1063 0;
BA_ "NmMessage" BO_ 1063 1;
BA_ "GenMsgAutoGenDsp" BO_ 1062 0;
BA_ "GenMsgAutoGenSnd" BO_ 1062 0;
BA_ "NmMessage" BO_ 1062 1;
BA_ "GenMsgAutoGenDsp" BO_ 1085 0;
BA_ "GenMsgAutoGenSnd" BO_ 1085 0;
BA_ "NmMessage" BO_ 1085 1;
BA_ "GenSigAutoGenDsp" SG_ 963 LW1_Lenkradwinkel 1;
BA_ "GenSigAutoGenSnd" SG_ 963 LW1_Lenkradwinkel 1;
BA_ "GenSigSendType" SG_ 963 LW1_Lenkradwinkel 0;
BA_ "GenSigSwitchedByIgnition" SG_ 963 LW1_Lenkradwinkel 1;
BA_ "GenSigAutoGenDsp" SG_ 963 LW1_Vorzeichen 1;
BA_ "GenSigAutoGenSnd" SG_ 963 LW1_Vorzeichen 1;
BA_ "GenSigSendType" SG_ 963 LW1_Vorzeichen 0;
BA_ "GenSigStartValue" SG_ 963 LW1_Vorzeichen 1;
BA_ "GenSigSwitchedByIgnition" SG_ 963 LW1_Vorzeichen 1;
BA_ "GenSigAutoGenDsp" SG_ 963 LW1_Geschwindigkeit 1;
BA_ "GenSigAutoGenSnd" SG_ 963 LW1_Geschwindigkeit 1;
BA_ "GenSigSendType" SG_ 963 LW1_Geschwindigkeit 0;
BA_ "GenSigSwitchedByIgnition" SG_ 963 LW1_Geschwindigkeit 1;
BA_ "GenSigAutoGenDsp" SG_ 963 LW1_Geschw_Vorzeichen 1;
BA_ "GenSigAutoGenSnd" SG_ 963 LW1_Geschw_Vorzeichen 1;
BA_ "GenSigSendType" SG_ 963 LW1_Geschw_Vorzeichen 0;
BA_ "GenSigStartValue" SG_ 963 LW1_Geschw_Vorzeichen 1;
BA_ "GenSigSwitchedByIgnition" SG_ 963 LW1_Geschw_Vorzeichen 1;
BA_ "GenSigAutoGenDsp" SG_ 963 LW1_ID 1;
BA_ "GenSigAutoGenSnd" SG_ 963 LW1_ID 1;
BA_ "GenSigSendType" SG_ 963 LW1_ID 0;
BA_ "GenSigSwitchedByIgnition" SG_ 963 LW1_ID 1;
BA_ "GenSigAutoGenDsp" SG_ 963 LW1_Quelle_Init 1;
BA_ "GenSigAutoGenSnd" SG_ 963 LW1_Quelle_Init 1;
BA_ "GenSigSendType" SG_ 963 LW1_Quelle_Init 0;
BA_ "GenSigSwitchedByIgnition" SG_ 963 LW1_Quelle_Init 1;
BA_ "GenSigAutoGenDsp" SG_ 963 LW1_Int_Status 1;
BA_ "GenSigAutoGenSnd" SG_ 963 LW1_Int_Status 1;
BA_ "GenSigSendType" SG_ 963 LW1_Int_Status 0;
BA_ "GenSigStartValue" SG_ 963 LW1_Int_Status 1;
BA_ "GenSigSwitchedByIgnition" SG_ 963 LW1_Int_Status 1;
BA_ "GenSigAutoGenDsp" SG_ 963 LW1_KL30_Ausfall 1;
BA_ "GenSigAutoGenSnd" SG_ 963 LW1_KL30_Ausfall 1;
BA_ "GenSigSendType" SG_ 963 LW1_KL30_Ausfall 0;
BA_ "GenSigSwitchedByIgnition" SG_ 963 LW1_KL30_Ausfall 1;
BA_ "GenSigAutoGenDsp" SG_ 963 LW1_Zaehler 1;
BA_ "GenSigAutoGenSnd" SG_ 963 LW1_Zaehler 1;
BA_ "GenSigSendType" SG_ 963 LW1_Zaehler 0;
BA_ "GenSigFuncType" SG_ 963 LW1_Zaehler 1;
BA_ "GenSigSwitchedByIgnition" SG_ 963 LW1_Zaehler 1;
BA_ "GenSigAutoGenDsp" SG_ 963 LW1_CRC8CHK 1;
BA_ "GenSigAutoGenSnd" SG_ 963 LW1_CRC8CHK 1;
BA_ "GenSigSendType" SG_ 963 LW1_CRC8CHK 0;
BA_ "GenSigFuncType" SG_ 963 LW1_CRC8CHK 2;
BA_ "GenSigSwitchedByIgnition" SG_ 963 LW1_CRC8CHK 1;
BA_ "GenSigAutoGenDsp" SG_ 963 LW1_Pruefsumme 1;
BA_ "GenSigAutoGenSnd" SG_ 963 LW1_Pruefsumme 1;
BA_ "GenSigSendType" SG_ 963 LW1_Pruefsumme 0;
BA_ "GenSigSwitchedByIgnition" SG_ 963 LW1_Pruefsumme 1;
BA_ "GenSigAutoGenDsp" SG_ 1329 LIA_Standlicht 1;
BA_ "GenSigAutoGenSnd" SG_ 1329 LIA_Standlicht 1;
BA_ "GenSigSendType" SG_ 1329 LIA_Standlicht 3;
BA_ "GenSigAutoGenDsp" SG_ 1329 LIA_Abblendlicht 1;
BA_ "GenSigAutoGenSnd" SG_ 1329 LIA_Abblendlicht 1;
BA_ "GenSigSendType" SG_ 1329 LIA_Abblendlicht 3;
BA_ "GenSigAutoGenDsp" SG_ 1329 LIA_Fernlicht 1;
BA_ "GenSigAutoGenSnd" SG_ 1329 LIA_Fernlicht 1;
BA_ "GenSigSendType" SG_ 1329 LIA_Fernlicht 3;
BA_ "GenSigAutoGenDsp" SG_ 1329 LIA_Nebellicht 1;
BA_ "GenSigAutoGenSnd" SG_ 1329 LIA_Nebellicht 1;
BA_ "GenSigSendType" SG_ 1329 LIA_Nebellicht 3;
BA_ "GenSigAutoGenDsp" SG_ 1329 LIA_Nebelschluss 1;
BA_ "GenSigAutoGenSnd" SG_ 1329 LIA_Nebelschluss 1;
BA_ "GenSigSendType" SG_ 1329 LIA_Nebelschluss 3;
BA_ "GenSigAutoGenDsp" SG_ 1329 LIA_Rueckfahrlicht 1;
BA_ "GenSigAutoGenSnd" SG_ 1329 LIA_Rueckfahrlicht 1;
BA_ "GenSigSendType" SG_ 1329 LIA_Rueckfahrlicht 3;
BA_ "GenSigAutoGenDsp" SG_ 1329 LIA_Parklicht_links 1;
BA_ "GenSigAutoGenSnd" SG_ 1329 LIA_Parklicht_links 1;
BA_ "GenSigSendType" SG_ 1329 LIA_Parklicht_links 3;
BA_ "GenSigAutoGenDsp" SG_ 1329 LIA_Parklicht_rechts 1;
BA_ "GenSigAutoGenSnd" SG_ 1329 LIA_Parklicht_rechts 1;
BA_ "GenSigSendType" SG_ 1329 LIA_Parklicht_rechts 3;
BA_ "GenSigAutoGenDsp" SG_ 1329 LIA_Blk_links 1;
BA_ "GenSigAutoGenSnd" SG_ 1329 LIA_Blk_links 1;
BA_ "GenSigSendType" SG_ 1329 LIA_Blk_links 3;
BA_ "GenSigAutoGenDsp" SG_ 1329 LIA_Blk_rechts 1;
BA_ "GenSigAutoGenSnd" SG_ 1329 LIA_Blk_rechts 1;
BA_ "GenSigSendType" SG_ 1329 LIA_Blk_rechts 3;
BA_ "GenSigAutoGenDsp" SG_ 1329 LIA_Anhaenger 1;
BA_ "GenSigAutoGenSnd" SG_ 1329 LIA_Anhaenger 1;
BA_ "GenSigSendType" SG_ 1329 LIA_Anhaenger 3;
BA_ "GenSigAutoGenDsp" SG_ 1329 LIA_Warnblink 1;
BA_ "GenSigAutoGenSnd" SG_ 1329 LIA_Warnblink 1;
BA_ "GenSigSendType" SG_ 1329 LIA_Warnblink 3;
BA_ "GenSigAutoGenDsp" SG_ 1329 LIA_BLK_Frequenz 1;
BA_ "GenSigAutoGenSnd" SG_ 1329 LIA_BLK_Frequenz 1;
BA_ "GenSigSendType" SG_ 1329 LIA_BLK_Frequenz 3;
BA_ "GenSigAutoGenDsp" SG_ 1329 LIA_AFL_Schalter 1;
BA_ "GenSigAutoGenSnd" SG_ 1329 LIA_AFL_Schalter 1;
BA_ "GenSigSendType" SG_ 1329 LIA_AFL_Schalter 3;
BA_ "GenSigAutoGenDsp" SG_ 1329 LIA_Bremslicht 1;
BA_ "GenSigAutoGenSnd" SG_ 1329 LIA_Bremslicht 1;
BA_ "GenSigSendType" SG_ 1329 LIA_Bremslicht 3;
BA_ "GenSigAutoGenDsp" SG_ 1329 LIA_Tagesfahrlicht 1;
BA_ "GenSigAutoGenSnd" SG_ 1329 LIA_Tagesfahrlicht 1;
BA_ "GenSigSendType" SG_ 1329 LIA_Tagesfahrlicht 3;
BA_ "GenSigAutoGenDsp" SG_ 1329 LIA_Blk_L_Kontrolle 1;
BA_ "GenSigAutoGenSnd" SG_ 1329 LIA_Blk_L_Kontrolle 1;
BA_ "GenSigSendType" SG_ 1329 LIA_Blk_L_Kontrolle 3;
BA_ "GenSigAutoGenDsp" SG_ 1329 LIA_Blk_R_Kontrolle 1;
BA_ "GenSigAutoGenSnd" SG_ 1329 LIA_Blk_R_Kontrolle 1;
BA_ "GenSigSendType" SG_ 1329 LIA_Blk_R_Kontrolle 3;
BA_ "GenSigAutoGenDsp" SG_ 1329 LIA_Kurv_Licht 1;
BA_ "GenSigAutoGenSnd" SG_ 1329 LIA_Kurv_Licht 1;
BA_ "GenSigSendType" SG_ 1329 LIA_Kurv_Licht 3;
BA_ "GenSigAutoGenDsp" SG_ 1329 LIA_Warnblk_Status 1;
BA_ "GenSigAutoGenSnd" SG_ 1329 LIA_Warnblk_Status 1;
BA_ "GenSigSendType" SG_ 1329 LIA_Warnblk_Status 3;
BA_ "GenSigAutoGenDsp" SG_ 1329 LIA_Zaehler 1;
BA_ "GenSigAutoGenSnd" SG_ 1329 LIA_Zaehler 1;
BA_ "GenSigSendType" SG_ 1329 LIA_Zaehler 0;
BA_ "GenSigFuncType" SG_ 1329 LIA_Zaehler 1;
BA_ "GenSigAutoGenDsp" SG_ 1329 LIA_Pruefsumme 1;
BA_ "GenSigAutoGenSnd" SG_ 1329 LIA_Pruefsumme 1;
BA_ "GenSigSendType" SG_ 1329 LIA_Pruefsumme 0;
BA_ "GenSigFuncType" SG_ 1329 LIA_Pruefsumme 4;
BA_ "GenSigAutoGenDsp" SG_ 705 LS1_Blk_links 1;
BA_ "GenSigAutoGenSnd" SG_ 705 LS1_Blk_links 1;
BA_ "GenSigSendType" SG_ 705 LS1_Blk_links 3;
BA_ "GenSigAutoGenDsp" SG_ 705 LS1_Blk_rechts 1;
BA_ "GenSigAutoGenSnd" SG_ 705 LS1_Blk_rechts 1;
BA_ "GenSigSendType" SG_ 705 LS1_Blk_rechts 3;
BA_ "GenSigAutoGenDsp" SG_ 705 LS1_Lichthupe 1;
BA_ "GenSigAutoGenSnd" SG_ 705 LS1_Lichthupe 1;
BA_ "GenSigSendType" SG_ 705 LS1_Lichthupe 3;
BA_ "GenSigAutoGenDsp" SG_ 705 LS1_Fernlicht 1;
BA_ "GenSigAutoGenSnd" SG_ 705 LS1_Fernlicht 1;
BA_ "GenSigSendType" SG_ 705 LS1_Fernlicht 3;
BA_ "GenSigAutoGenDsp" SG_ 705 LS1_Parklicht_links 1;
BA_ "GenSigAutoGenSnd" SG_ 705 LS1_Parklicht_links 1;
BA_ "GenSigSendType" SG_ 705 LS1_Parklicht_links 3;
BA_ "GenSigAutoGenDsp" SG_ 705 LS1_Parklicht_rechts 1;
BA_ "GenSigAutoGenSnd" SG_ 705 LS1_Parklicht_rechts 1;
BA_ "GenSigSendType" SG_ 705 LS1_Parklicht_rechts 3;
BA_ "GenSigAutoGenDsp" SG_ 705 LS1_Signalhorn 1;
BA_ "GenSigAutoGenSnd" SG_ 705 LS1_Signalhorn 1;
BA_ "GenSigSendType" SG_ 705 LS1_Signalhorn 3;
BA_ "GenSigAutoGenDsp" SG_ 705 LS1_Tipwischen 1;
BA_ "GenSigAutoGenSnd" SG_ 705 LS1_Tipwischen 1;
BA_ "GenSigSendType" SG_ 705 LS1_Tipwischen 3;
BA_ "GenSigAutoGenDsp" SG_ 705 LS1_Intervall 1;
BA_ "GenSigAutoGenSnd" SG_ 705 LS1_Intervall 1;
BA_ "GenSigSendType" SG_ 705 LS1_Intervall 3;
BA_ "GenSigAutoGenDsp" SG_ 705 LS1_WischenStufe_1 1;
BA_ "GenSigAutoGenSnd" SG_ 705 LS1_WischenStufe_1 1;
BA_ "GenSigSendType" SG_ 705 LS1_WischenStufe_1 3;
BA_ "GenSigAutoGenDsp" SG_ 705 LS1_WischenStufe_2 1;
BA_ "GenSigAutoGenSnd" SG_ 705 LS1_WischenStufe_2 1;
BA_ "GenSigSendType" SG_ 705 LS1_WischenStufe_2 3;
BA_ "GenSigAutoGenDsp" SG_ 705 LS1_Frontwaschen 1;
BA_ "GenSigAutoGenSnd" SG_ 705 LS1_Frontwaschen 1;
BA_ "GenSigSendType" SG_ 705 LS1_Frontwaschen 3;
BA_ "GenSigAutoGenDsp" SG_ 705 LS1_Bew_Frontwaschen 1;
BA_ "GenSigAutoGenSnd" SG_ 705 LS1_Bew_Frontwaschen 1;
BA_ "GenSigSendType" SG_ 705 LS1_Bew_Frontwaschen 3;
BA_ "GenSigAutoGenDsp" SG_ 705 LS1_Heckintervall 1;
BA_ "GenSigAutoGenSnd" SG_ 705 LS1_Heckintervall 1;
BA_ "GenSigSendType" SG_ 705 LS1_Heckintervall 3;
BA_ "GenSigAutoGenDsp" SG_ 705 LS1_Heckwaschen 1;
BA_ "GenSigAutoGenSnd" SG_ 705 LS1_Heckwaschen 1;
BA_ "GenSigSendType" SG_ 705 LS1_Heckwaschen 3;
BA_ "GenSigAutoGenDsp" SG_ 705 LS1_Intervallstufen 1;
BA_ "GenSigAutoGenSnd" SG_ 705 LS1_Intervallstufen 1;
BA_ "GenSigSendType" SG_ 705 LS1_Intervallstufen 3;
BA_ "GenSigAutoGenDsp" SG_ 705 LS1_BC_Down_Cursor 1;
BA_ "GenSigAutoGenSnd" SG_ 705 LS1_BC_Down_Cursor 1;
BA_ "GenSigSendType" SG_ 705 LS1_BC_Down_Cursor 3;
BA_ "GenSigAutoGenDsp" SG_ 705 LS1_BC_Up_Cursor 1;
BA_ "GenSigAutoGenSnd" SG_ 705 LS1_BC_Up_Cursor 1;
BA_ "GenSigSendType" SG_ 705 LS1_BC_Up_Cursor 3;
BA_ "GenSigAutoGenDsp" SG_ 705 LS1_BC_Reset 1;
BA_ "GenSigAutoGenSnd" SG_ 705 LS1_BC_Reset 1;
BA_ "GenSigSendType" SG_ 705 LS1_BC_Reset 3;
BA_ "GenSigAutoGenDsp" SG_ 705 LS1_KD_Fehler 1;
BA_ "GenSigAutoGenSnd" SG_ 705 LS1_KD_Fehler 1;
BA_ "GenSigSendType" SG_ 705 LS1_KD_Fehler 0;
BA_ "GenSigAutoGenDsp" SG_ 705 LS1_LSY_oben 1;
BA_ "GenSigAutoGenSnd" SG_ 705 LS1_LSY_oben 1;
BA_ "GenSigSendType" SG_ 705 LS1_LSY_oben 3;
BA_ "GenSigAutoGenDsp" SG_ 705 LS1_LSY_unten 1;
BA_ "GenSigAutoGenSnd" SG_ 705 LS1_LSY_unten 1;
BA_ "GenSigSendType" SG_ 705 LS1_LSY_unten 3;
BA_ "GenSigAutoGenDsp" SG_ 705 LS1_LSZ_vor 1;
BA_ "GenSigAutoGenSnd" SG_ 705 LS1_LSZ_vor 1;
BA_ "GenSigSendType" SG_ 705 LS1_LSZ_vor 3;
BA_ "GenSigAutoGenDsp" SG_ 705 LS1_LSZ_zurueck 1;
BA_ "GenSigAutoGenSnd" SG_ 705 LS1_LSZ_zurueck 1;
BA_ "GenSigSendType" SG_ 705 LS1_LSZ_zurueck 3;
BA_ "GenSigAutoGenDsp" SG_ 705 LS1_ELV_enable 1;
BA_ "GenSigAutoGenSnd" SG_ 705 LS1_ELV_enable 1;
BA_ "GenSigSendType" SG_ 705 LS1_ELV_enable 3;
BA_ "GenSigAutoGenDsp" SG_ 705 LS1_def_ELV_Enable 1;
BA_ "GenSigAutoGenSnd" SG_ 705 LS1_def_ELV_Enable 1;
BA_ "GenSigSendType" SG_ 705 LS1_def_ELV_Enable 3;
BA_ "GenSigAutoGenDsp" SG_ 705 LS1_Easy_Entry_LS 1;
BA_ "GenSigAutoGenSnd" SG_ 705 LS1_Easy_Entry_LS 1;
BA_ "GenSigSendType" SG_ 705 LS1_Easy_Entry_LS 3;
BA_ "GenSigAutoGenDsp" SG_ 705 LS1_LHeizung_aktiv 1;
BA_ "GenSigAutoGenSnd" SG_ 705 LS1_LHeizung_aktiv 1;
BA_ "GenSigSendType" SG_ 705 LS1_LHeizung_aktiv 3;
BA_ "GenSigAutoGenDsp" SG_ 705 LS1_Winterstellung 1;
BA_ "GenSigAutoGenSnd" SG_ 705 LS1_Winterstellung 1;
BA_ "GenSigSendType" SG_ 705 LS1_Winterstellung 3;
BA_ "GenSigAutoGenDsp" SG_ 705 LS1_MFL_vorhanden 1;
BA_ "GenSigAutoGenSnd" SG_ 705 LS1_MFL_vorhanden 1;
BA_ "GenSigSendType" SG_ 705 LS1_MFL_vorhanden 0;
BA_ "GenSigAutoGenDsp" SG_ 705 LS1_MFA_vorhanden 1;
BA_ "GenSigAutoGenSnd" SG_ 705 LS1_MFA_vorhanden 1;
BA_ "GenSigSendType" SG_ 705 LS1_MFA_vorhanden 0;
BA_ "GenSigAutoGenDsp" SG_ 705 LS1_MFA_Tasten 1;
BA_ "GenSigAutoGenSnd" SG_ 705 LS1_MFA_Tasten 1;
BA_ "GenSigSendType" SG_ 705 LS1_MFA_Tasten 0;
BA_ "GenSigAutoGenDsp" SG_ 705 LS1_def_P_Verriegelt 1;
BA_ "GenSigAutoGenSnd" SG_ 705 LS1_def_P_Verriegelt 1;
BA_ "GenSigSendType" SG_ 705 LS1_def_P_Verriegelt 3;
BA_ "GenSigAutoGenDsp" SG_ 705 LS1_MFL_Typ 1;
BA_ "GenSigAutoGenSnd" SG_ 705 LS1_MFL_Typ 1;
BA_ "GenSigSendType" SG_ 705 LS1_MFL_Typ 0;
BA_ "GenSigAutoGenDsp" SG_ 705 LS1_Servicestellung 1;
BA_ "GenSigAutoGenSnd" SG_ 705 LS1_Servicestellung 1;
BA_ "GenSigSendType" SG_ 705 LS1_Servicestellung 3;
BA_ "GenSigAutoGenDsp" SG_ 705 LS1_P_verriegelt 1;
BA_ "GenSigAutoGenSnd" SG_ 705 LS1_P_verriegelt 1;
BA_ "GenSigSendType" SG_ 705 LS1_P_verriegelt 3;
BA_ "GenSigAutoGenDsp" SG_ 705 LS1_FAS_Taster 1;
BA_ "GenSigAutoGenSnd" SG_ 705 LS1_FAS_Taster 1;
BA_ "GenSigSendType" SG_ 705 LS1_FAS_Taster 3;
BA_ "GenSigAutoGenDsp" SG_ 705 LS1_Fehler_FAS_Taster 1;
BA_ "GenSigAutoGenSnd" SG_ 705 LS1_Fehler_FAS_Taster 1;
BA_ "GenSigSendType" SG_ 705 LS1_Fehler_FAS_Taster 3;
BA_ "Fehlerwert" SG_ 705 LS1_Fehler_FAS_Taster 1;
BA_ "GenSigAutoGenDsp" SG_ 705 LS1_Fehler_Vibration 1;
BA_ "GenSigAutoGenSnd" SG_ 705 LS1_Fehler_Vibration 1;
BA_ "GenSigSendType" SG_ 705 LS1_Fehler_Vibration 3;
BA_ "Fehlerwert" SG_ 705 LS1_Fehler_Vibration 1;
BA_ "GenSigAutoGenDsp" SG_ 1371 MD1_MDI_on 1;
BA_ "GenSigAutoGenSnd" SG_ 1371 MD1_MDI_on 1;
BA_ "GenSigSendType" SG_ 1371 MD1_MDI_on 3;
BA_ "GenSigAutoGenDsp" SG_ 1371 MD1_MDI_Error_flag 1;
BA_ "GenSigAutoGenSnd" SG_ 1371 MD1_MDI_Error_flag 1;
BA_ "GenSigSendType" SG_ 1371 MD1_MDI_Error_flag 3;
BA_ "GenSigAutoGenDsp" SG_ 1317 SHM_SH_SL 1;
BA_ "GenSigAutoGenSnd" SG_ 1317 SHM_SH_SL 1;
BA_ "GenSigSendType" SG_ 1317 SHM_SH_SL 6;
BA_ "GenSigAutoGenDsp" SG_ 1317 SHM_SH 1;
BA_ "GenSigAutoGenSnd" SG_ 1317 SHM_SH 1;
BA_ "GenSigSendType" SG_ 1317 SHM_SH 6;
BA_ "GenSigAutoGenDsp" SG_ 1317 SHM_SL 1;
BA_ "GenSigAutoGenSnd" SG_ 1317 SHM_SL 1;
BA_ "GenSigSendType" SG_ 1317 SHM_SL 6;
BA_ "GenSigAutoGenDsp" SG_ 1317 SHM_MVW 1;
BA_ "GenSigAutoGenSnd" SG_ 1317 SHM_MVW 1;
BA_ "GenSigSendType" SG_ 1317 SHM_MVW 6;
BA_ "GenSigAutoGenDsp" SG_ 1317 SHM_SH_Geblaese 1;
BA_ "GenSigAutoGenSnd" SG_ 1317 SHM_SH_Geblaese 1;
BA_ "GenSigSendType" SG_ 1317 SHM_SH_Geblaese 6;
BA_ "GenSigAutoGenDsp" SG_ 1317 SHM_Restdauer 1;
BA_ "GenSigAutoGenSnd" SG_ 1317 SHM_Restdauer 1;
BA_ "GenSigSendType" SG_ 1317 SHM_Restdauer 6;
BA_ "Fehlerwert" SG_ 1317 SHM_Restdauer 127;
BA_ "GenSigAutoGenDsp" SG_ 1287 DS1_Power_Mode 1;
BA_ "GenSigAutoGenSnd" SG_ 1287 DS1_Power_Mode 1;
BA_ "GenSigSendType" SG_ 1287 DS1_Power_Mode 3;
BA_ "GenSigAutoGenDsp" SG_ 1287 DS1_Status_Request 1;
BA_ "GenSigAutoGenSnd" SG_ 1287 DS1_Status_Request 1;
BA_ "GenSigSendType" SG_ 1287 DS1_Status_Request 3;
BA_ "GenSigAutoGenDsp" SG_ 1287 DS1_Loudness 1;
BA_ "GenSigAutoGenSnd" SG_ 1287 DS1_Loudness 1;
BA_ "GenSigSendType" SG_ 1287 DS1_Loudness 3;
BA_ "GenSigAutoGenDsp" SG_ 1287 DS1_Dynamic 1;
BA_ "GenSigAutoGenSnd" SG_ 1287 DS1_Dynamic 1;
BA_ "GenSigSendType" SG_ 1287 DS1_Dynamic 3;
BA_ "GenSigAutoGenDsp" SG_ 1287 DS1_Driver_On_Off 1;
BA_ "GenSigAutoGenSnd" SG_ 1287 DS1_Driver_On_Off 1;
BA_ "GenSigSendType" SG_ 1287 DS1_Driver_On_Off 3;
BA_ "GenSigAutoGenDsp" SG_ 1287 DS1_Sitzbezuege 1;
BA_ "GenSigAutoGenSnd" SG_ 1287 DS1_Sitzbezuege 1;
BA_ "GenSigSendType" SG_ 1287 DS1_Sitzbezuege 3;
BA_ "GenSigAutoGenDsp" SG_ 1287 DS1_GALA 1;
BA_ "GenSigAutoGenSnd" SG_ 1287 DS1_GALA 1;
BA_ "GenSigSendType" SG_ 1287 DS1_GALA 3;
BA_ "GenSigAutoGenDsp" SG_ 1287 DS1_Klangcharakter 1;
BA_ "GenSigAutoGenSnd" SG_ 1287 DS1_Klangcharakter 1;
BA_ "GenSigSendType" SG_ 1287 DS1_Klangcharakter 3;
BA_ "GenSigAutoGenDsp" SG_ 1287 DS1_Bass 1;
BA_ "GenSigAutoGenSnd" SG_ 1287 DS1_Bass 1;
BA_ "GenSigSendType" SG_ 1287 DS1_Bass 3;
BA_ "GenSigAutoGenDsp" SG_ 1287 DS1_Mid 1;
BA_ "GenSigAutoGenSnd" SG_ 1287 DS1_Mid 1;
BA_ "GenSigSendType" SG_ 1287 DS1_Mid 3;
BA_ "GenSigAutoGenDsp" SG_ 1287 DS1_Treble 1;
BA_ "GenSigAutoGenSnd" SG_ 1287 DS1_Treble 1;
BA_ "GenSigSendType" SG_ 1287 DS1_Treble 3;
BA_ "GenSigAutoGenDsp" SG_ 1287 DS1_Mute_Mode 1;
BA_ "GenSigAutoGenSnd" SG_ 1287 DS1_Mute_Mode 1;
BA_ "GenSigSendType" SG_ 1287 DS1_Mute_Mode 3;
BA_ "GenSigAutoGenDsp" SG_ 1287 DS1_Ch_1_Mute 1;
BA_ "GenSigAutoGenSnd" SG_ 1287 DS1_Ch_1_Mute 1;
BA_ "GenSigSendType" SG_ 1287 DS1_Ch_1_Mute 3;
BA_ "GenSigAutoGenDsp" SG_ 1287 DS1_Ch_2_Mute 1;
BA_ "GenSigAutoGenSnd" SG_ 1287 DS1_Ch_2_Mute 1;
BA_ "GenSigSendType" SG_ 1287 DS1_Ch_2_Mute 3;
BA_ "GenSigAutoGenDsp" SG_ 1287 DS1_Ch_3_Mute 1;
BA_ "GenSigAutoGenSnd" SG_ 1287 DS1_Ch_3_Mute 1;
BA_ "GenSigSendType" SG_ 1287 DS1_Ch_3_Mute 3;
BA_ "GenSigAutoGenDsp" SG_ 1287 DS1_Effektstaerke 1;
BA_ "GenSigAutoGenSnd" SG_ 1287 DS1_Effektstaerke 1;
BA_ "GenSigSendType" SG_ 1287 DS1_Effektstaerke 3;
BA_ "GenSigAutoGenDsp" SG_ 1291 DS2_Ch_1_Source 1;
BA_ "GenSigAutoGenSnd" SG_ 1291 DS2_Ch_1_Source 1;
BA_ "GenSigSendType" SG_ 1291 DS2_Ch_1_Source 3;
BA_ "GenSigAutoGenDsp" SG_ 1291 DS2_Ch_2_Source 1;
BA_ "GenSigAutoGenSnd" SG_ 1291 DS2_Ch_2_Source 1;
BA_ "GenSigSendType" SG_ 1291 DS2_Ch_2_Source 3;
BA_ "GenSigAutoGenDsp" SG_ 1291 DS2_Stereo1_Active 1;
BA_ "GenSigAutoGenSnd" SG_ 1291 DS2_Stereo1_Active 1;
BA_ "GenSigSendType" SG_ 1291 DS2_Stereo1_Active 3;
BA_ "GenSigAutoGenDsp" SG_ 1291 DS2_Mono1_Active 1;
BA_ "GenSigAutoGenSnd" SG_ 1291 DS2_Mono1_Active 1;
BA_ "GenSigSendType" SG_ 1291 DS2_Mono1_Active 3;
BA_ "GenSigAutoGenDsp" SG_ 1291 DS2_Ch_1_Volume 1;
BA_ "GenSigAutoGenSnd" SG_ 1291 DS2_Ch_1_Volume 1;
BA_ "GenSigSendType" SG_ 1291 DS2_Ch_1_Volume 3;
BA_ "GenSigAutoGenDsp" SG_ 1291 DS2_Ch_1_Fader 1;
BA_ "GenSigAutoGenSnd" SG_ 1291 DS2_Ch_1_Fader 1;
BA_ "GenSigSendType" SG_ 1291 DS2_Ch_1_Fader 3;
BA_ "GenSigAutoGenDsp" SG_ 1291 DS2_Ch_1_Cross_Fading 1;
BA_ "GenSigAutoGenSnd" SG_ 1291 DS2_Ch_1_Cross_Fading 1;
BA_ "GenSigSendType" SG_ 1291 DS2_Ch_1_Cross_Fading 3;
BA_ "GenSigAutoGenDsp" SG_ 1291 DS2_Ch_1_Fading_ID 1;
BA_ "GenSigAutoGenSnd" SG_ 1291 DS2_Ch_1_Fading_ID 1;
BA_ "GenSigSendType" SG_ 1291 DS2_Ch_1_Fading_ID 3;
BA_ "GenSigAutoGenDsp" SG_ 1291 DS2_Ch_1_Balance 1;
BA_ "GenSigAutoGenSnd" SG_ 1291 DS2_Ch_1_Balance 1;
BA_ "GenSigSendType" SG_ 1291 DS2_Ch_1_Balance 3;
BA_ "GenSigAutoGenDsp" SG_ 1291 DS2_Ch_2_Volume 1;
BA_ "GenSigAutoGenSnd" SG_ 1291 DS2_Ch_2_Volume 1;
BA_ "GenSigSendType" SG_ 1291 DS2_Ch_2_Volume 3;
BA_ "GenSigAutoGenDsp" SG_ 1291 DS2_Ch_2_Fader 1;
BA_ "GenSigAutoGenSnd" SG_ 1291 DS2_Ch_2_Fader 1;
BA_ "GenSigSendType" SG_ 1291 DS2_Ch_2_Fader 3;
BA_ "GenSigAutoGenDsp" SG_ 1291 DS2_Ch_2_Cross_Fading 1;
BA_ "GenSigAutoGenSnd" SG_ 1291 DS2_Ch_2_Cross_Fading 1;
BA_ "GenSigSendType" SG_ 1291 DS2_Ch_2_Cross_Fading 3;
BA_ "GenSigAutoGenDsp" SG_ 1291 DS2_Ch_2_Fading_ID 1;
BA_ "GenSigAutoGenSnd" SG_ 1291 DS2_Ch_2_Fading_ID 1;
BA_ "GenSigSendType" SG_ 1291 DS2_Ch_2_Fading_ID 3;
BA_ "GenSigAutoGenDsp" SG_ 1291 DS2_Ch_2_Balance 1;
BA_ "GenSigAutoGenSnd" SG_ 1291 DS2_Ch_2_Balance 1;
BA_ "GenSigSendType" SG_ 1291 DS2_Ch_2_Balance 3;
BA_ "GenSigAutoGenDsp" SG_ 1293 DS3_Ch_3_Source 1;
BA_ "GenSigAutoGenSnd" SG_ 1293 DS3_Ch_3_Source 1;
BA_ "GenSigSendType" SG_ 1293 DS3_Ch_3_Source 3;
BA_ "GenSigAutoGenDsp" SG_ 1293 DS3_Mono2_Active 1;
BA_ "GenSigAutoGenSnd" SG_ 1293 DS3_Mono2_Active 1;
BA_ "GenSigSendType" SG_ 1293 DS3_Mono2_Active 3;
BA_ "GenSigAutoGenDsp" SG_ 1293 DS3_Chime_Active 1;
BA_ "GenSigAutoGenSnd" SG_ 1293 DS3_Chime_Active 1;
BA_ "GenSigSendType" SG_ 1293 DS3_Chime_Active 3;
BA_ "GenSigAutoGenDsp" SG_ 1293 DS3_Chime_Number 1;
BA_ "GenSigAutoGenSnd" SG_ 1293 DS3_Chime_Number 1;
BA_ "GenSigSendType" SG_ 1293 DS3_Chime_Number 3;
BA_ "GenSigAutoGenDsp" SG_ 1293 DS3_Ch_3_Volume 1;
BA_ "GenSigAutoGenSnd" SG_ 1293 DS3_Ch_3_Volume 1;
BA_ "GenSigSendType" SG_ 1293 DS3_Ch_3_Volume 3;
BA_ "GenSigAutoGenDsp" SG_ 1293 DS3_Ch_3_Fader 1;
BA_ "GenSigAutoGenSnd" SG_ 1293 DS3_Ch_3_Fader 1;
BA_ "GenSigSendType" SG_ 1293 DS3_Ch_3_Fader 3;
BA_ "GenSigAutoGenDsp" SG_ 1293 DS3_Ch_3_Cross_Fading 1;
BA_ "GenSigAutoGenSnd" SG_ 1293 DS3_Ch_3_Cross_Fading 1;
BA_ "GenSigSendType" SG_ 1293 DS3_Ch_3_Cross_Fading 3;
BA_ "GenSigAutoGenDsp" SG_ 1293 DS3_Ch_3_Fading_ID 1;
BA_ "GenSigAutoGenSnd" SG_ 1293 DS3_Ch_3_Fading_ID 1;
BA_ "GenSigSendType" SG_ 1293 DS3_Ch_3_Fading_ID 3;
BA_ "GenSigAutoGenDsp" SG_ 1293 DS3_Ch_3_Balance 1;
BA_ "GenSigAutoGenSnd" SG_ 1293 DS3_Ch_3_Balance 1;
BA_ "GenSigSendType" SG_ 1293 DS3_Ch_3_Balance 3;
BA_ "GenSigAutoGenDsp" SG_ 1293 DS3_Chime_Volume 1;
BA_ "GenSigAutoGenSnd" SG_ 1293 DS3_Chime_Volume 1;
BA_ "GenSigSendType" SG_ 1293 DS3_Chime_Volume 3;
BA_ "GenSigAutoGenDsp" SG_ 1293 DS3_Chime_Fader 1;
BA_ "GenSigAutoGenSnd" SG_ 1293 DS3_Chime_Fader 1;
BA_ "GenSigSendType" SG_ 1293 DS3_Chime_Fader 3;
BA_ "GenSigAutoGenDsp" SG_ 1293 DS3_Chime_Balance 1;
BA_ "GenSigAutoGenSnd" SG_ 1293 DS3_Chime_Balance 1;
BA_ "GenSigSendType" SG_ 1293 DS3_Chime_Balance 3;
BA_ "GenSigAutoGenDsp" SG_ 1295 DS4_Hall 1;
BA_ "GenSigAutoGenSnd" SG_ 1295 DS4_Hall 1;
BA_ "GenSigSendType" SG_ 1295 DS4_Hall 3;
BA_ "GenSigAutoGenDsp" SG_ 1295 DS4_Echo 1;
BA_ "GenSigAutoGenSnd" SG_ 1295 DS4_Echo 1;
BA_ "GenSigSendType" SG_ 1295 DS4_Echo 3;
BA_ "GenSigAutoGenDsp" SG_ 1295 DS4_Cathedral 1;
BA_ "GenSigAutoGenSnd" SG_ 1295 DS4_Cathedral 1;
BA_ "GenSigSendType" SG_ 1295 DS4_Cathedral 3;
BA_ "GenSigAutoGenDsp" SG_ 1295 DS4_Stadium 1;
BA_ "GenSigAutoGenSnd" SG_ 1295 DS4_Stadium 1;
BA_ "GenSigSendType" SG_ 1295 DS4_Stadium 3;
BA_ "GenSigAutoGenDsp" SG_ 1295 DS4_Talk 1;
BA_ "GenSigAutoGenSnd" SG_ 1295 DS4_Talk 1;
BA_ "GenSigSendType" SG_ 1295 DS4_Talk 3;
BA_ "GenSigAutoGenDsp" SG_ 1295 DS4_ROCK 1;
BA_ "GenSigAutoGenSnd" SG_ 1295 DS4_ROCK 1;
BA_ "GenSigSendType" SG_ 1295 DS4_ROCK 3;
BA_ "GenSigAutoGenDsp" SG_ 1295 DS4_POP 1;
BA_ "GenSigAutoGenSnd" SG_ 1295 DS4_POP 1;
BA_ "GenSigSendType" SG_ 1295 DS4_POP 3;
BA_ "GenSigAutoGenDsp" SG_ 1295 DS4_CLASSIC 1;
BA_ "GenSigAutoGenSnd" SG_ 1295 DS4_CLASSIC 1;
BA_ "GenSigSendType" SG_ 1295 DS4_CLASSIC 3;
BA_ "GenSigAutoGenDsp" SG_ 1295 DS4_LIVE 1;
BA_ "GenSigAutoGenSnd" SG_ 1295 DS4_LIVE 1;
BA_ "GenSigSendType" SG_ 1295 DS4_LIVE 3;
BA_ "GenSigAutoGenDsp" SG_ 1295 DS4_NEWS 1;
BA_ "GenSigAutoGenSnd" SG_ 1295 DS4_NEWS 1;
BA_ "GenSigSendType" SG_ 1295 DS4_NEWS 3;
BA_ "GenSigAutoGenDsp" SG_ 1577 MA1_Verbrauch 1;
BA_ "GenSigAutoGenSnd" SG_ 1577 MA1_Verbrauch 1;
BA_ "GenSigSendType" SG_ 1577 MA1_Verbrauch 0;
BA_ "GenSigAutoGenDsp" SG_ 1577 MA1_100km_Verbrauch 1;
BA_ "GenSigAutoGenSnd" SG_ 1577 MA1_100km_Verbrauch 1;
BA_ "GenSigSendType" SG_ 1577 MA1_100km_Verbrauch 0;
BA_ "GenSigAutoGenDsp" SG_ 1577 MA1_l_Verbrauch 1;
BA_ "GenSigAutoGenSnd" SG_ 1577 MA1_l_Verbrauch 1;
BA_ "GenSigSendType" SG_ 1577 MA1_l_Verbrauch 0;
BA_ "GenSigAutoGenDsp" SG_ 1577 MA1_mpg_Verbrauch 1;
BA_ "GenSigAutoGenSnd" SG_ 1577 MA1_mpg_Verbrauch 1;
BA_ "GenSigSendType" SG_ 1577 MA1_mpg_Verbrauch 0;
BA_ "GenSigAutoGenDsp" SG_ 1577 MA1_Reichweite 1;
BA_ "GenSigAutoGenSnd" SG_ 1577 MA1_Reichweite 1;
BA_ "GenSigSendType" SG_ 1577 MA1_Reichweite 0;
BA_ "GenSigAutoGenDsp" SG_ 1577 MA1_km_Reichweite 1;
BA_ "GenSigAutoGenSnd" SG_ 1577 MA1_km_Reichweite 1;
BA_ "GenSigSendType" SG_ 1577 MA1_km_Reichweite 0;
BA_ "GenSigAutoGenDsp" SG_ 1577 MA1_mls_Reichweite 1;
BA_ "GenSigAutoGenSnd" SG_ 1577 MA1_mls_Reichweite 1;
BA_ "GenSigSendType" SG_ 1577 MA1_mls_Reichweite 0;
BA_ "GenSigAutoGenDsp" SG_ 1577 MA1_Kilometerstand 1;
BA_ "GenSigAutoGenSnd" SG_ 1577 MA1_Kilometerstand 1;
BA_ "GenSigSendType" SG_ 1577 MA1_Kilometerstand 0;
BA_ "GenSigAutoGenDsp" SG_ 1577 MA1_km_Kilometerstand 1;
BA_ "GenSigAutoGenSnd" SG_ 1577 MA1_km_Kilometerstand 1;
BA_ "GenSigSendType" SG_ 1577 MA1_km_Kilometerstand 0;
BA_ "GenSigAutoGenDsp" SG_ 1577 MA1_mls_Kilometerstand 1;
BA_ "GenSigAutoGenSnd" SG_ 1577 MA1_mls_Kilometerstand 1;
BA_ "GenSigSendType" SG_ 1577 MA1_mls_Kilometerstand 0;
BA_ "GenSigAutoGenDsp" SG_ 1579 MA2_Verbrauch 1;
BA_ "GenSigAutoGenSnd" SG_ 1579 MA2_Verbrauch 1;
BA_ "GenSigSendType" SG_ 1579 MA2_Verbrauch 0;
BA_ "GenSigAutoGenDsp" SG_ 1579 MA2_100km_Verbrauch 1;
BA_ "GenSigAutoGenSnd" SG_ 1579 MA2_100km_Verbrauch 1;
BA_ "GenSigSendType" SG_ 1579 MA2_100km_Verbrauch 0;
BA_ "GenSigAutoGenDsp" SG_ 1579 MA2_l_Verbrauch 1;
BA_ "GenSigAutoGenSnd" SG_ 1579 MA2_l_Verbrauch 1;
BA_ "GenSigSendType" SG_ 1579 MA2_l_Verbrauch 0;
BA_ "GenSigAutoGenDsp" SG_ 1579 MA2_mpg_Verbrauch 1;
BA_ "GenSigAutoGenSnd" SG_ 1579 MA2_mpg_Verbrauch 1;
BA_ "GenSigSendType" SG_ 1579 MA2_mpg_Verbrauch 0;
BA_ "GenSigAutoGenDsp" SG_ 1579 MA2_Strecke 1;
BA_ "GenSigAutoGenSnd" SG_ 1579 MA2_Strecke 1;
BA_ "GenSigSendType" SG_ 1579 MA2_Strecke 0;
BA_ "GenSigAutoGenDsp" SG_ 1579 MA2_km_Strecke 1;
BA_ "GenSigAutoGenSnd" SG_ 1579 MA2_km_Strecke 1;
BA_ "GenSigSendType" SG_ 1579 MA2_km_Strecke 0;
BA_ "GenSigAutoGenDsp" SG_ 1579 MA2_mls_Strecke 1;
BA_ "GenSigAutoGenSnd" SG_ 1579 MA2_mls_Strecke 1;
BA_ "GenSigSendType" SG_ 1579 MA2_mls_Strecke 0;
BA_ "GenSigAutoGenDsp" SG_ 1579 MA2_Zeit 1;
BA_ "GenSigAutoGenSnd" SG_ 1579 MA2_Zeit 1;
BA_ "GenSigSendType" SG_ 1579 MA2_Zeit 0;
BA_ "GenSigAutoGenDsp" SG_ 1579 MA2_Geschw 1;
BA_ "GenSigAutoGenSnd" SG_ 1579 MA2_Geschw 1;
BA_ "GenSigSendType" SG_ 1579 MA2_Geschw 0;
BA_ "GenSigAutoGenDsp" SG_ 1579 MA2_kmh_Geschw 1;
BA_ "GenSigAutoGenSnd" SG_ 1579 MA2_kmh_Geschw 1;
BA_ "GenSigSendType" SG_ 1579 MA2_kmh_Geschw 0;
BA_ "GenSigAutoGenDsp" SG_ 1579 MA2_mph_Geschw 1;
BA_ "GenSigAutoGenSnd" SG_ 1579 MA2_mph_Geschw 1;
BA_ "GenSigSendType" SG_ 1579 MA2_mph_Geschw 0;
BA_ "GenSigAutoGenDsp" SG_ 1581 MA3_Verbrauch 1;
BA_ "GenSigAutoGenSnd" SG_ 1581 MA3_Verbrauch 1;
BA_ "GenSigSendType" SG_ 1581 MA3_Verbrauch 0;
BA_ "GenSigAutoGenDsp" SG_ 1581 MA3_100km_Verbrauch 1;
BA_ "GenSigAutoGenSnd" SG_ 1581 MA3_100km_Verbrauch 1;
BA_ "GenSigSendType" SG_ 1581 MA3_100km_Verbrauch 0;
BA_ "GenSigAutoGenDsp" SG_ 1581 MA3_l_Verbrauch 1;
BA_ "GenSigAutoGenSnd" SG_ 1581 MA3_l_Verbrauch 1;
BA_ "GenSigSendType" SG_ 1581 MA3_l_Verbrauch 0;
BA_ "GenSigAutoGenDsp" SG_ 1581 MA3_mpg_Verbrauch 1;
BA_ "GenSigAutoGenSnd" SG_ 1581 MA3_mpg_Verbrauch 1;
BA_ "GenSigSendType" SG_ 1581 MA3_mpg_Verbrauch 0;
BA_ "GenSigAutoGenDsp" SG_ 1581 MA3_Strecke 1;
BA_ "GenSigAutoGenSnd" SG_ 1581 MA3_Strecke 1;
BA_ "GenSigSendType" SG_ 1581 MA3_Strecke 0;
BA_ "GenSigAutoGenDsp" SG_ 1581 MA3_km_Strecke 1;
BA_ "GenSigAutoGenSnd" SG_ 1581 MA3_km_Strecke 1;
BA_ "GenSigSendType" SG_ 1581 MA3_km_Strecke 0;
BA_ "GenSigAutoGenDsp" SG_ 1581 MA3_mls_Strecke 1;
BA_ "GenSigAutoGenSnd" SG_ 1581 MA3_mls_Strecke 1;
BA_ "GenSigSendType" SG_ 1581 MA3_mls_Strecke 0;
BA_ "GenSigAutoGenDsp" SG_ 1581 MA3_Zeit 1;
BA_ "GenSigAutoGenSnd" SG_ 1581 MA3_Zeit 1;
BA_ "GenSigSendType" SG_ 1581 MA3_Zeit 0;
BA_ "GenSigAutoGenDsp" SG_ 1581 MA3_Geschw 1;
BA_ "GenSigAutoGenSnd" SG_ 1581 MA3_Geschw 1;
BA_ "GenSigSendType" SG_ 1581 MA3_Geschw 0;
BA_ "GenSigAutoGenDsp" SG_ 1581 MA3_kmh_Geschw 1;
BA_ "GenSigAutoGenSnd" SG_ 1581 MA3_kmh_Geschw 1;
BA_ "GenSigSendType" SG_ 1581 MA3_kmh_Geschw 0;
BA_ "GenSigAutoGenDsp" SG_ 1581 MA3_mph_Geschw 1;
BA_ "GenSigAutoGenSnd" SG_ 1581 MA3_mph_Geschw 1;
BA_ "GenSigSendType" SG_ 1581 MA3_mph_Geschw 0;
BA_ "GenSigAutoGenDsp" SG_ 1321 MA4_Verbr_TZ 1;
BA_ "GenSigAutoGenSnd" SG_ 1321 MA4_Verbr_TZ 1;
BA_ "GenSigSendType" SG_ 1321 MA4_Verbr_TZ 0;
BA_ "GenSigAutoGenDsp" SG_ 1321 MA4_100km_Verbrauch 1;
BA_ "GenSigAutoGenSnd" SG_ 1321 MA4_100km_Verbrauch 1;
BA_ "GenSigSendType" SG_ 1321 MA4_100km_Verbrauch 0;
BA_ "GenSigAutoGenDsp" SG_ 1321 MA4_l_Verbrauch 1;
BA_ "GenSigAutoGenSnd" SG_ 1321 MA4_l_Verbrauch 1;
BA_ "GenSigSendType" SG_ 1321 MA4_l_Verbrauch 0;
BA_ "GenSigAutoGenDsp" SG_ 1321 MA4_mpg_Verbrauch 1;
BA_ "GenSigAutoGenSnd" SG_ 1321 MA4_mpg_Verbrauch 1;
BA_ "GenSigSendType" SG_ 1321 MA4_mpg_Verbrauch 0;
BA_ "GenSigAutoGenDsp" SG_ 1321 MA4_Tankzyklus 1;
BA_ "GenSigAutoGenSnd" SG_ 1321 MA4_Tankzyklus 1;
BA_ "GenSigSendType" SG_ 1321 MA4_Tankzyklus 0;
BA_ "GenSigAutoGenDsp" SG_ 1321 MA4_Strecke_TZ 1;
BA_ "GenSigAutoGenSnd" SG_ 1321 MA4_Strecke_TZ 1;
BA_ "GenSigSendType" SG_ 1321 MA4_Strecke_TZ 0;
BA_ "GenSigAutoGenDsp" SG_ 1321 MA4_km_Strecke 1;
BA_ "GenSigAutoGenSnd" SG_ 1321 MA4_km_Strecke 1;
BA_ "GenSigSendType" SG_ 1321 MA4_km_Strecke 0;
BA_ "GenSigAutoGenDsp" SG_ 1321 MA4_mls_Strecke 1;
BA_ "GenSigAutoGenSnd" SG_ 1321 MA4_mls_Strecke 1;
BA_ "GenSigSendType" SG_ 1321 MA4_mls_Strecke 0;
BA_ "GenSigAutoGenDsp" SG_ 1321 MA4_Geschw 1;
BA_ "GenSigAutoGenSnd" SG_ 1321 MA4_Geschw 1;
BA_ "GenSigSendType" SG_ 1321 MA4_Geschw 0;
BA_ "GenSigAutoGenDsp" SG_ 1321 MA4_kmh_Geschw 1;
BA_ "GenSigAutoGenSnd" SG_ 1321 MA4_kmh_Geschw 1;
BA_ "GenSigSendType" SG_ 1321 MA4_kmh_Geschw 0;
BA_ "GenSigAutoGenDsp" SG_ 1321 MA4_mph_Geschw 1;
BA_ "GenSigAutoGenSnd" SG_ 1321 MA4_mph_Geschw 1;
BA_ "GenSigSendType" SG_ 1321 MA4_mph_Geschw 0;
BA_ "GenSigAutoGenDsp" SG_ 1323 MA5_Lenkzeit 1;
BA_ "GenSigAutoGenSnd" SG_ 1323 MA5_Lenkzeit 1;
BA_ "GenSigSendType" SG_ 1323 MA5_Lenkzeit 0;
BA_ "GenSigAutoGenDsp" SG_ 1323 MA5_Tankrestzeit 1;
BA_ "GenSigAutoGenSnd" SG_ 1323 MA5_Tankrestzeit 1;
BA_ "GenSigSendType" SG_ 1323 MA5_Tankrestzeit 0;
BA_ "GenSigAutoGenDsp" SG_ 1323 MA5_Strecke_Langzeit 1;
BA_ "GenSigAutoGenSnd" SG_ 1323 MA5_Strecke_Langzeit 1;
BA_ "GenSigSendType" SG_ 1323 MA5_Strecke_Langzeit 0;
BA_ "GenSigAutoGenDsp" SG_ 1323 MA5_km_Kilometerstand 1;
BA_ "GenSigAutoGenSnd" SG_ 1323 MA5_km_Kilometerstand 1;
BA_ "GenSigSendType" SG_ 1323 MA5_km_Kilometerstand 0;
BA_ "GenSigAutoGenDsp" SG_ 1323 MA5_mls_Kilometerstand 1;
BA_ "GenSigAutoGenSnd" SG_ 1323 MA5_mls_Kilometerstand 1;
BA_ "GenSigSendType" SG_ 1323 MA5_mls_Kilometerstand 0;
BA_ "GenSigAutoGenDsp" SG_ 1475 ML1_Ziel_ 1;
BA_ "GenSigAutoGenSnd" SG_ 1475 ML1_Ziel_ 1;
BA_ "GenSigSendType" SG_ 1475 ML1_Ziel_ 3;
BA_ "GenSigAutoGenDsp" SG_ 1475 ML1_Befehl_ 1;
BA_ "GenSigAutoGenSnd" SG_ 1475 ML1_Befehl_ 1;
BA_ "GenSigSendType" SG_ 1475 ML1_Befehl_ 3;
BA_ "GenSigAutoGenDsp" SG_ 1473 MLT_Symbol 1;
BA_ "GenSigAutoGenSnd" SG_ 1473 MLT_Symbol 1;
BA_ "GenSigSendType" SG_ 1473 MLT_Symbol 9;
BA_ "GenSigAutoGenDsp" SG_ 1473 MLT_DW_Ticks 1;
BA_ "GenSigAutoGenSnd" SG_ 1473 MLT_DW_Ticks 1;
BA_ "GenSigSendType" SG_ 1473 MLT_DW_Ticks 9;
BA_ "GenSigAutoGenDsp" SG_ 1473 MLT_DW_VZ 1;
BA_ "GenSigAutoGenSnd" SG_ 1473 MLT_DW_VZ 1;
BA_ "GenSigSendType" SG_ 1473 MLT_DW_VZ 9;
BA_ "GenSigAutoGenDsp" SG_ 1473 MLT_Tickzaehler_1 1;
BA_ "GenSigAutoGenSnd" SG_ 1473 MLT_Tickzaehler_1 1;
BA_ "GenSigSendType" SG_ 1473 MLT_Tickzaehler_1 9;
BA_ "GenSigAutoGenDsp" SG_ 1473 MLT_Tickzaehler_2 1;
BA_ "GenSigAutoGenSnd" SG_ 1473 MLT_Tickzaehler_2 1;
BA_ "GenSigSendType" SG_ 1473 MLT_Tickzaehler_2 9;
BA_ "GenSigAutoGenDsp" SG_ 1473 MLT_Marke 1;
BA_ "GenSigAutoGenSnd" SG_ 1473 MLT_Marke 1;
BA_ "GenSigAutoGenDsp" SG_ 1473 MLT_Variante 1;
BA_ "GenSigAutoGenSnd" SG_ 1473 MLT_Variante 1;
BA_ "GenSigAutoGenDsp" SG_ 1481 MFS_Taste_Info 1;
BA_ "GenSigAutoGenSnd" SG_ 1481 MFS_Taste_Info 1;
BA_ "GenSigSendType" SG_ 1481 MFS_Taste_Info 6;
BA_ "GenSigAutoGenDsp" SG_ 1481 MFS_Taste_EinAus 1;
BA_ "GenSigAutoGenSnd" SG_ 1481 MFS_Taste_EinAus 1;
BA_ "GenSigSendType" SG_ 1481 MFS_Taste_EinAus 6;
BA_ "GenSigAutoGenDsp" SG_ 1481 MFS_Taste_Stau 1;
BA_ "GenSigAutoGenSnd" SG_ 1481 MFS_Taste_Stau 1;
BA_ "GenSigSendType" SG_ 1481 MFS_Taste_Stau 6;
BA_ "GenSigAutoGenDsp" SG_ 1481 MFS_Taste_Return 1;
BA_ "GenSigAutoGenSnd" SG_ 1481 MFS_Taste_Return 1;
BA_ "GenSigSendType" SG_ 1481 MFS_Taste_Return 6;
BA_ "GenSigAutoGenDsp" SG_ 1481 MFS_Taste_Telematik 1;
BA_ "GenSigAutoGenSnd" SG_ 1481 MFS_Taste_Telematik 1;
BA_ "GenSigSendType" SG_ 1481 MFS_Taste_Telematik 6;
BA_ "GenSigAutoGenDsp" SG_ 1481 MFS_Taste_Enter 1;
BA_ "GenSigAutoGenSnd" SG_ 1481 MFS_Taste_Enter 1;
BA_ "GenSigSendType" SG_ 1481 MFS_Taste_Enter 6;
BA_ "GenSigAutoGenDsp" SG_ 1481 MFS_Taste_Menue 1;
BA_ "GenSigAutoGenSnd" SG_ 1481 MFS_Taste_Menue 1;
BA_ "GenSigSendType" SG_ 1481 MFS_Taste_Menue 6;
BA_ "GenSigAutoGenDsp" SG_ 1481 MFS_Prioritaet 1;
BA_ "GenSigAutoGenSnd" SG_ 1481 MFS_Prioritaet 1;
BA_ "GenSigSendType" SG_ 1481 MFS_Prioritaet 6;
BA_ "GenSigAutoGenDsp" SG_ 1481 MFS_Anzahl_Ticks 1;
BA_ "GenSigAutoGenSnd" SG_ 1481 MFS_Anzahl_Ticks 1;
BA_ "GenSigSendType" SG_ 1481 MFS_Anzahl_Ticks 6;
BA_ "GenSigAutoGenDsp" SG_ 1365 MO7_LL_Status 1;
BA_ "GenSigAutoGenSnd" SG_ 1365 MO7_LL_Status 1;
BA_ "GenSigSendType" SG_ 1365 MO7_LL_Status 0;
BA_ "GenSigSwitchedByIgnition" SG_ 1365 MO7_LL_Status 1;
BA_ "GenSigAutoGenDsp" SG_ 1365 MO7_V_Begrenz 1;
BA_ "GenSigAutoGenSnd" SG_ 1365 MO7_V_Begrenz 1;
BA_ "GenSigSendType" SG_ 1365 MO7_V_Begrenz 0;
BA_ "GenSigSwitchedByIgnition" SG_ 1365 MO7_V_Begrenz 1;
BA_ "GenSigAutoGenDsp" SG_ 1365 MO7_V_Begr_akt 1;
BA_ "GenSigAutoGenSnd" SG_ 1365 MO7_V_Begr_akt 1;
BA_ "GenSigSendType" SG_ 1365 MO7_V_Begr_akt 0;
BA_ "GenSigSwitchedByIgnition" SG_ 1365 MO7_V_Begr_akt 1;
BA_ "GenSigAutoGenDsp" SG_ 1365 MO7_FehlerSp 1;
BA_ "GenSigAutoGenSnd" SG_ 1365 MO7_FehlerSp 1;
BA_ "GenSigSendType" SG_ 1365 MO7_FehlerSp 0;
BA_ "GenSigAutoGenDsp" SG_ 1365 MO7_Fehler_Oel_Temp 1;
BA_ "GenSigAutoGenSnd" SG_ 1365 MO7_Fehler_Oel_Temp 1;
BA_ "GenSigSendType" SG_ 1365 MO7_Fehler_Oel_Temp 0;
BA_ "GenSigStartValue" SG_ 1365 MO7_Fehler_Oel_Temp 1;
BA_ "GenSigSwitchedByIgnition" SG_ 1365 MO7_Fehler_Oel_Temp 1;
BA_ "GenSigAutoGenDsp" SG_ 1365 MO7_PTC 1;
BA_ "GenSigAutoGenSnd" SG_ 1365 MO7_PTC 1;
BA_ "GenSigSendType" SG_ 1365 MO7_PTC 0;
BA_ "GenSigStartValue" SG_ 1365 MO7_PTC 7;
BA_ "GenSigSwitchedByIgnition" SG_ 1365 MO7_PTC 1;
BA_ "GenSigAutoGenDsp" SG_ 1365 MO7_DFM 1;
BA_ "GenSigAutoGenSnd" SG_ 1365 MO7_DFM 1;
BA_ "GenSigSendType" SG_ 1365 MO7_DFM 0;
BA_ "GenSigSwitchedByIgnition" SG_ 1365 MO7_DFM 1;
BA_ "Fehlerwert" SG_ 1365 MO7_DFM 255;
BA_ "GenSigAutoGenDsp" SG_ 1365 MO7_Hoeheninfo 1;
BA_ "GenSigAutoGenSnd" SG_ 1365 MO7_Hoeheninfo 1;
BA_ "GenSigSendType" SG_ 1365 MO7_Hoeheninfo 0;
BA_ "GenSigSwitchedByIgnition" SG_ 1365 MO7_Hoeheninfo 1;
BA_ "Fehlerwert" SG_ 1365 MO7_Hoeheninfo 255;
BA_ "GenSigAutoGenDsp" SG_ 1365 MO7_Gradient_Drehz 1;
BA_ "GenSigAutoGenSnd" SG_ 1365 MO7_Gradient_Drehz 1;
BA_ "GenSigSendType" SG_ 1365 MO7_Gradient_Drehz 0;
BA_ "GenSigSwitchedByIgnition" SG_ 1365 MO7_Gradient_Drehz 1;
BA_ "GenSigAutoGenDsp" SG_ 1365 MO7_Gradient_Vorz 1;
BA_ "GenSigAutoGenSnd" SG_ 1365 MO7_Gradient_Vorz 1;
BA_ "GenSigSendType" SG_ 1365 MO7_Gradient_Vorz 0;
BA_ "GenSigSwitchedByIgnition" SG_ 1365 MO7_Gradient_Vorz 1;
BA_ "GenSigAutoGenDsp" SG_ 1365 MO7_Ladedruckneu 1;
BA_ "GenSigAutoGenSnd" SG_ 1365 MO7_Ladedruckneu 1;
BA_ "GenSigSendType" SG_ 1365 MO7_Ladedruckneu 0;
BA_ "GenSigSwitchedByIgnition" SG_ 1365 MO7_Ladedruckneu 1;
BA_ "Fehlerwert" SG_ 1365 MO7_Ladedruckneu 255;
BA_ "GenSigAutoGenDsp" SG_ 1365 MO7_GenLoadResp 1;
BA_ "GenSigAutoGenSnd" SG_ 1365 MO7_GenLoadResp 1;
BA_ "GenSigSendType" SG_ 1365 MO7_GenLoadResp 0;
BA_ "GenSigSwitchedByIgnition" SG_ 1365 MO7_GenLoadResp 1;
BA_ "GenSigAutoGenDsp" SG_ 1365 MO7_PTC_bereit 1;
BA_ "GenSigAutoGenSnd" SG_ 1365 MO7_PTC_bereit 1;
BA_ "GenSigSendType" SG_ 1365 MO7_PTC_bereit 0;
BA_ "GenSigSwitchedByIgnition" SG_ 1365 MO7_PTC_bereit 1;
BA_ "GenSigAutoGenDsp" SG_ 1365 MO7_Mot_weckfaehig 1;
BA_ "GenSigAutoGenSnd" SG_ 1365 MO7_Mot_weckfaehig 1;
BA_ "GenSigSendType" SG_ 1365 MO7_Mot_weckfaehig 0;
BA_ "GenSigSwitchedByIgnition" SG_ 1365 MO7_Mot_weckfaehig 1;
BA_ "GenSigAutoGenDsp" SG_ 1365 MO7_Zus_Kuehl 1;
BA_ "GenSigAutoGenSnd" SG_ 1365 MO7_Zus_Kuehl 1;
BA_ "GenSigSendType" SG_ 1365 MO7_Zus_Kuehl 0;
BA_ "GenSigSwitchedByIgnition" SG_ 1365 MO7_Zus_Kuehl 1;
BA_ "GenSigAutoGenDsp" SG_ 1365 MO7_Sleep_Ind 1;
BA_ "GenSigAutoGenSnd" SG_ 1365 MO7_Sleep_Ind 1;
BA_ "GenSigSendType" SG_ 1365 MO7_Sleep_Ind 0;
BA_ "GenSigAutoGenDsp" SG_ 1365 MO7_Rueck_LLDz 1;
BA_ "GenSigAutoGenSnd" SG_ 1365 MO7_Rueck_LLDz 1;
BA_ "GenSigSendType" SG_ 1365 MO7_Rueck_LLDz 0;
BA_ "GenSigSwitchedByIgnition" SG_ 1365 MO7_Rueck_LLDz 1;
BA_ "GenSigAutoGenDsp" SG_ 1365 MO7_Last_abwurf 1;
BA_ "GenSigAutoGenSnd" SG_ 1365 MO7_Last_abwurf 1;
BA_ "GenSigSendType" SG_ 1365 MO7_Last_abwurf 0;
BA_ "GenSigSwitchedByIgnition" SG_ 1365 MO7_Last_abwurf 1;
BA_ "GenSigAutoGenDsp" SG_ 1365 MO7_Ein_Generator 1;
BA_ "GenSigAutoGenSnd" SG_ 1365 MO7_Ein_Generator 1;
BA_ "GenSigSendType" SG_ 1365 MO7_Ein_Generator 0;
BA_ "GenSigSwitchedByIgnition" SG_ 1365 MO7_Ein_Generator 1;
BA_ "GenSigAutoGenDsp" SG_ 1365 MO7_Lastabwurf_Heiz 1;
BA_ "GenSigAutoGenSnd" SG_ 1365 MO7_Lastabwurf_Heiz 1;
BA_ "GenSigSendType" SG_ 1365 MO7_Lastabwurf_Heiz 0;
BA_ "GenSigSwitchedByIgnition" SG_ 1365 MO7_Lastabwurf_Heiz 1;
BA_ "GenSigAutoGenDsp" SG_ 1365 MO7_Stat_Gluehk 1;
BA_ "GenSigAutoGenSnd" SG_ 1365 MO7_Stat_Gluehk 1;
BA_ "GenSigSendType" SG_ 1365 MO7_Stat_Gluehk 0;
BA_ "GenSigSwitchedByIgnition" SG_ 1365 MO7_Stat_Gluehk 1;
BA_ "Fehlerwert" SG_ 1365 MO7_Stat_Gluehk 15;
BA_ "GenSigAutoGenDsp" SG_ 1365 MO7_Oeltemperatur 1;
BA_ "GenSigAutoGenSnd" SG_ 1365 MO7_Oeltemperatur 1;
BA_ "GenSigSendType" SG_ 1365 MO7_Oeltemperatur 0;
BA_ "GenSigStartValue" SG_ 1365 MO7_Oeltemperatur 1;
BA_ "GenSigSwitchedByIgnition" SG_ 1365 MO7_Oeltemperatur 1;
BA_ "Fehlerwert" SG_ 1365 MO7_Oeltemperatur 255;
BA_ "GenSigAutoGenDsp" SG_ 1420 M10_Anzeige 1;
BA_ "GenSigAutoGenSnd" SG_ 1420 M10_Anzeige 1;
BA_ "GenSigSendType" SG_ 1420 M10_Anzeige 0;
BA_ "GenSigSwitchedByIgnition" SG_ 1420 M10_Anzeige 1;
BA_ "GenSigAutoGenDsp" SG_ 1420 M10_Anf_Kl75 1;
BA_ "GenSigAutoGenSnd" SG_ 1420 M10_Anf_Kl75 1;
BA_ "GenSigSendType" SG_ 1420 M10_Anf_Kl75 3;
BA_ "GenSigStartValue" SG_ 1420 M10_Anf_Kl75 1;
BA_ "GenSigSwitchedByIgnition" SG_ 1420 M10_Anf_Kl75 1;
BA_ "GenSigSendType" SG_ 1420 MSG_Remotestart_Betrieb 3;
BA_ "GenSigAutoGenDsp" SG_ 1420 M10_SpannungsAnf 1;
BA_ "GenSigAutoGenSnd" SG_ 1420 M10_SpannungsAnf 1;
BA_ "GenSigSendType" SG_ 1420 M10_SpannungsAnf 0;
BA_ "GenSigAutoGenDsp" SG_ 1420 M10_UDruckDyn 1;
BA_ "GenSigAutoGenSnd" SG_ 1420 M10_UDruckDyn 1;
BA_ "GenSigSendType" SG_ 1420 M10_UDruckDyn 0;
BA_ "GenSigSwitchedByIgnition" SG_ 1420 M10_UDruckDyn 1;
BA_ "GenSigAutoGenDsp" SG_ 1420 M10_Status_StSt 1;
BA_ "GenSigAutoGenSnd" SG_ 1420 M10_Status_StSt 1;
BA_ "GenSigSendType" SG_ 1420 M10_Status_StSt 0;
BA_ "GenSigSwitchedByIgnition" SG_ 1420 M10_Status_StSt 1;
BA_ "GenSigAutoGenDsp" SG_ 1420 M10_MotorStopp 1;
BA_ "GenSigAutoGenSnd" SG_ 1420 M10_MotorStopp 1;
BA_ "GenSigSendType" SG_ 1420 M10_MotorStopp 3;
BA_ "GenSigSwitchedByIgnition" SG_ 1420 M10_MotorStopp 1;
BA_ "GenSigAutoGenDsp" SG_ 1420 M10_Wiederstart 1;
BA_ "GenSigAutoGenSnd" SG_ 1420 M10_Wiederstart 1;
BA_ "GenSigSendType" SG_ 1420 M10_Wiederstart 3;
BA_ "GenSigSwitchedByIgnition" SG_ 1420 M10_Wiederstart 1;
BA_ "GenSigAutoGenDsp" SG_ 1420 M10_Schubabschaltung 1;
BA_ "GenSigAutoGenSnd" SG_ 1420 M10_Schubabschaltung 1;
BA_ "GenSigSendType" SG_ 1420 M10_Schubabschaltung 0;
BA_ "GenSigSwitchedByIgnition" SG_ 1420 M10_Schubabschaltung 1;
BA_ "GenSigAutoGenDsp" SG_ 1420 M10_Druck_err_gem 1;
BA_ "GenSigAutoGenSnd" SG_ 1420 M10_Druck_err_gem 1;
BA_ "GenSigSendType" SG_ 1420 M10_Druck_err_gem 0;
BA_ "GenSigSwitchedByIgnition" SG_ 1420 M10_Druck_err_gem 1;
BA_ "GenSigAutoGenDsp" SG_ 1420 M10_Freigabe_Reku 1;
BA_ "GenSigAutoGenSnd" SG_ 1420 M10_Freigabe_Reku 1;
BA_ "GenSigSendType" SG_ 1420 M10_Freigabe_Reku 0;
BA_ "GenSigSwitchedByIgnition" SG_ 1420 M10_Freigabe_Reku 1;
BA_ "GenSigAutoGenDsp" SG_ 1420 M10_rel_Saugrohrdruck 1;
BA_ "GenSigAutoGenSnd" SG_ 1420 M10_rel_Saugrohrdruck 1;
BA_ "GenSigSendType" SG_ 1420 M10_rel_Saugrohrdruck 0;
BA_ "GenSigSwitchedByIgnition" SG_ 1420 M10_rel_Saugrohrdruck 1;
BA_ "GenSigAutoGenDsp" SG_ 1420 M10_Fahrbereitschaft 1;
BA_ "GenSigAutoGenSnd" SG_ 1420 M10_Fahrbereitschaft 1;
BA_ "GenSigSendType" SG_ 1420 M10_Fahrbereitschaft 0;
BA_ "GenSigSwitchedByIgnition" SG_ 1420 M10_Fahrbereitschaft 1;
BA_ "GenSigAutoGenDsp" SG_ 1420 M10_Hybrid 1;
BA_ "GenSigAutoGenSnd" SG_ 1420 M10_Hybrid 1;
BA_ "GenSigSendType" SG_ 1420 M10_Hybrid 0;
BA_ "GenSigAutoGenDsp" SG_ 1420 M10_EM_aktiv 1;
BA_ "GenSigAutoGenSnd" SG_ 1420 M10_EM_aktiv 1;
BA_ "GenSigSendType" SG_ 1420 M10_EM_aktiv 0;
BA_ "GenSigSwitchedByIgnition" SG_ 1420 M10_EM_aktiv 1;
BA_ "GenSigAutoGenDsp" SG_ 1420 M10_VM_aktiv 1;
BA_ "GenSigAutoGenSnd" SG_ 1420 M10_VM_aktiv 1;
BA_ "GenSigSendType" SG_ 1420 M10_VM_aktiv 0;
BA_ "GenSigSwitchedByIgnition" SG_ 1420 M10_VM_aktiv 1;
BA_ "GenSigAutoGenDsp" SG_ 1420 M10_HYB_Bereitlampe 1;
BA_ "GenSigAutoGenSnd" SG_ 1420 M10_HYB_Bereitlampe 1;
BA_ "GenSigSendType" SG_ 1420 M10_HYB_Bereitlampe 0;
BA_ "GenSigSwitchedByIgnition" SG_ 1420 M10_HYB_Bereitlampe 1;
BA_ "GenSigAutoGenDsp" SG_ 1420 M10_HYB_Warnlampe 1;
BA_ "GenSigAutoGenSnd" SG_ 1420 M10_HYB_Warnlampe 1;
BA_ "GenSigSendType" SG_ 1420 M10_HYB_Warnlampe 0;
BA_ "GenSigSwitchedByIgnition" SG_ 1420 M10_HYB_Warnlampe 1;
BA_ "GenSigAutoGenDsp" SG_ 1420 M10_HYB_Fehlerlampe 1;
BA_ "GenSigAutoGenSnd" SG_ 1420 M10_HYB_Fehlerlampe 1;
BA_ "GenSigSendType" SG_ 1420 M10_HYB_Fehlerlampe 0;
BA_ "GenSigSwitchedByIgnition" SG_ 1420 M10_HYB_Fehlerlampe 1;
BA_ "GenSigAutoGenDsp" SG_ 1420 M10_Fehler_HV_Netz 1;
BA_ "GenSigAutoGenSnd" SG_ 1420 M10_Fehler_HV_Netz 1;
BA_ "GenSigSendType" SG_ 1420 M10_Fehler_HV_Netz 0;
BA_ "GenSigSwitchedByIgnition" SG_ 1420 M10_Fehler_HV_Netz 1;
BA_ "GenSigAutoGenDsp" SG_ 1420 M10_EKlKomLeiRed 1;
BA_ "GenSigAutoGenSnd" SG_ 1420 M10_EKlKomLeiRed 1;
BA_ "GenSigSendType" SG_ 1420 M10_EKlKomLeiRed 0;
BA_ "GenSigSwitchedByIgnition" SG_ 1420 M10_EKlKomLeiRed 1;
BA_ "GenSigAutoGenDsp" SG_ 1420 M10_Klimadruck 1;
BA_ "GenSigAutoGenSnd" SG_ 1420 M10_Klimadruck 1;
BA_ "GenSigSendType" SG_ 1420 M10_Klimadruck 0;
BA_ "GenSigStartValue" SG_ 1420 M10_Klimadruck 254;
BA_ "GenSigSwitchedByIgnition" SG_ 1420 M10_Klimadruck 1;
BA_ "Fehlerwert" SG_ 1420 M10_Klimadruck 255;
BA_ "GenSigAutoGenDsp" SG_ 1420 M10_KompAusCode 1;
BA_ "GenSigAutoGenSnd" SG_ 1420 M10_KompAusCode 1;
BA_ "GenSigSendType" SG_ 1420 M10_KompAusCode 0;
BA_ "GenSigSwitchedByIgnition" SG_ 1420 M10_KompAusCode 1;
BA_ "GenSigSendType" SG_ 1420 M10_StartStopp_Fahrerwunsch 3;
BA_ "GenSigAutoGenDsp" SG_ 1420 M10_Akustik 1;
BA_ "GenSigAutoGenSnd" SG_ 1420 M10_Akustik 1;
BA_ "GenSigSendType" SG_ 1420 M10_Akustik 0;
BA_ "GenSigSwitchedByIgnition" SG_ 1420 M10_Akustik 1;
BA_ "GenSigAutoGenDsp" SG_ 1420 M10_Text_1_Hybrid 1;
BA_ "GenSigAutoGenSnd" SG_ 1420 M10_Text_1_Hybrid 1;
BA_ "GenSigSendType" SG_ 1420 M10_Text_1_Hybrid 0;
BA_ "GenSigSwitchedByIgnition" SG_ 1420 M10_Text_1_Hybrid 1;
BA_ "GenSigAutoGenDsp" SG_ 1420 M10_Text_2_Hybrid 1;
BA_ "GenSigAutoGenSnd" SG_ 1420 M10_Text_2_Hybrid 1;
BA_ "GenSigSendType" SG_ 1420 M10_Text_2_Hybrid 0;
BA_ "GenSigSwitchedByIgnition" SG_ 1420 M10_Text_2_Hybrid 1;
BA_ "GenSigAutoGenDsp" SG_ 1420 M10_Text_3_Hybrid 1;
BA_ "GenSigAutoGenSnd" SG_ 1420 M10_Text_3_Hybrid 1;
BA_ "GenSigSendType" SG_ 1420 M10_Text_3_Hybrid 0;
BA_ "GenSigSwitchedByIgnition" SG_ 1420 M10_Text_3_Hybrid 1;
BA_ "GenSigAutoGenDsp" SG_ 1420 M10_Text_4_Hybrid 1;
BA_ "GenSigAutoGenSnd" SG_ 1420 M10_Text_4_Hybrid 1;
BA_ "GenSigSendType" SG_ 1420 M10_Text_4_Hybrid 0;
BA_ "GenSigSwitchedByIgnition" SG_ 1420 M10_Text_4_Hybrid 1;
BA_ "GenSigAutoGenDsp" SG_ 1420 M10_Text_5_Hybrid 1;
BA_ "GenSigAutoGenSnd" SG_ 1420 M10_Text_5_Hybrid 1;
BA_ "GenSigSendType" SG_ 1420 M10_Text_5_Hybrid 0;
BA_ "GenSigSwitchedByIgnition" SG_ 1420 M10_Text_5_Hybrid 1;
BA_ "GenSigAutoGenDsp" SG_ 1420 M10_Text_6_Hybrid 1;
BA_ "GenSigAutoGenSnd" SG_ 1420 M10_Text_6_Hybrid 1;
BA_ "GenSigSendType" SG_ 1420 M10_Text_6_Hybrid 0;
BA_ "GenSigSwitchedByIgnition" SG_ 1420 M10_Text_6_Hybrid 1;
BA_ "GenSigAutoGenDsp" SG_ 1420 M10_Text_7_Hybrid 1;
BA_ "GenSigAutoGenSnd" SG_ 1420 M10_Text_7_Hybrid 1;
BA_ "GenSigSendType" SG_ 1420 M10_Text_7_Hybrid 0;
BA_ "GenSigSwitchedByIgnition" SG_ 1420 M10_Text_7_Hybrid 1;
BA_ "GenSigAutoGenDsp" SG_ 1420 M10_Text_8_Hybrid 1;
BA_ "GenSigAutoGenSnd" SG_ 1420 M10_Text_8_Hybrid 1;
BA_ "GenSigSendType" SG_ 1420 M10_Text_8_Hybrid 0;
BA_ "GenSigSwitchedByIgnition" SG_ 1420 M10_Text_8_Hybrid 1;
BA_ "GenSigAutoGenDsp" SG_ 1420 M10_ShiftLockLampe 1;
BA_ "GenSigAutoGenSnd" SG_ 1420 M10_ShiftLockLampe 1;
BA_ "GenSigSendType" SG_ 1420 M10_ShiftLockLampe 0;
BA_ "GenSigSwitchedByIgnition" SG_ 1420 M10_ShiftLockLampe 1;
BA_ "GenSigAutoGenDsp" SG_ 1420 M10_BMSInfo_gue 1;
BA_ "GenSigAutoGenSnd" SG_ 1420 M10_BMSInfo_gue 1;
BA_ "GenSigSendType" SG_ 1420 M10_BMSInfo_gue 0;
BA_ "GenSigSwitchedByIgnition" SG_ 1420 M10_BMSInfo_gue 1;
BA_ "GenSigAutoGenDsp" SG_ 1420 M10_VentilationReq 1;
BA_ "GenSigAutoGenSnd" SG_ 1420 M10_VentilationReq 1;
BA_ "GenSigSendType" SG_ 1420 M10_VentilationReq 0;
BA_ "GenSigSwitchedByIgnition" SG_ 1420 M10_VentilationReq 1;
BA_ "GenSigAutoGenDsp" SG_ 1420 M10_BattFanSpd 1;
BA_ "GenSigAutoGenSnd" SG_ 1420 M10_BattFanSpd 1;
BA_ "GenSigSendType" SG_ 1420 M10_BattFanSpd 0;
BA_ "GenSigStartValue" SG_ 1420 M10_BattFanSpd 14;
BA_ "GenSigSwitchedByIgnition" SG_ 1420 M10_BattFanSpd 1;
BA_ "Fehlerwert" SG_ 1420 M10_BattFanSpd 15;
BA_ "GenSigAutoGenDsp" SG_ 1540 NV1_NAV_On 1;
BA_ "GenSigAutoGenSnd" SG_ 1540 NV1_NAV_On 1;
BA_ "GenSigSendType" SG_ 1540 NV1_NAV_On 3;
BA_ "GenSigAutoGenDsp" SG_ 1540 NV1_NAV_mute 1;
BA_ "GenSigAutoGenSnd" SG_ 1540 NV1_NAV_mute 1;
BA_ "GenSigSendType" SG_ 1540 NV1_NAV_mute 3;
BA_ "GenSigAutoGenDsp" SG_ 1540 NV1_NAV_Wartnton_Geschw 1;
BA_ "GenSigAutoGenSnd" SG_ 1540 NV1_NAV_Wartnton_Geschw 1;
BA_ "GenSigSendType" SG_ 1540 NV1_NAV_Wartnton_Geschw 3;
BA_ "GenSigAutoGenDsp" SG_ 1540 NV1_NAV_Error_flag 1;
BA_ "GenSigAutoGenSnd" SG_ 1540 NV1_NAV_Error_flag 1;
BA_ "GenSigSendType" SG_ 1540 NV1_NAV_Error_flag 3;
BA_ "GenSigAutoGenDsp" SG_ 1540 NV1_NAV_Mode 1;
BA_ "GenSigAutoGenSnd" SG_ 1540 NV1_NAV_Mode 1;
BA_ "GenSigSendType" SG_ 1540 NV1_NAV_Mode 3;
BA_ "GenSigAutoGenDsp" SG_ 1540 NV1_NAV_Para1 1;
BA_ "GenSigAutoGenSnd" SG_ 1540 NV1_NAV_Para1 1;
BA_ "GenSigSendType" SG_ 1540 NV1_NAV_Para1 3;
BA_ "GenSigAutoGenDsp" SG_ 1540 NV1_NAV_Para2 1;
BA_ "GenSigAutoGenSnd" SG_ 1540 NV1_NAV_Para2 1;
BA_ "GenSigSendType" SG_ 1540 NV1_NAV_Para2 3;
BA_ "GenSigAutoGenDsp" SG_ 1540 NV1_NAV_Para3 1;
BA_ "GenSigAutoGenSnd" SG_ 1540 NV1_NAV_Para3 1;
BA_ "GenSigSendType" SG_ 1540 NV1_NAV_Para3 3;
BA_ "GenSigAutoGenDsp" SG_ 1540 NV1_NAV_Para4 1;
BA_ "GenSigAutoGenSnd" SG_ 1540 NV1_NAV_Para4 1;
BA_ "GenSigSendType" SG_ 1540 NV1_NAV_Para4 3;
BA_ "GenSigAutoGenDsp" SG_ 1540 NV1_NAV_Para5 1;
BA_ "GenSigAutoGenSnd" SG_ 1540 NV1_NAV_Para5 1;
BA_ "GenSigSendType" SG_ 1540 NV1_NAV_Para5 3;
BA_ "GenSigAutoGenDsp" SG_ 1540 NV1_NAV_Para6 1;
BA_ "GenSigAutoGenSnd" SG_ 1540 NV1_NAV_Para6 1;
BA_ "GenSigSendType" SG_ 1540 NV1_NAV_Para6 3;
BA_ "GenSigAutoGenDsp" SG_ 1441 ND_Init 1;
BA_ "GenSigAutoGenSnd" SG_ 1441 ND_Init 1;
BA_ "GenSigSendType" SG_ 1441 ND_Init 0;
BA_ "GenSigAutoGenDsp" SG_ 1441 ND_ErrorTime 1;
BA_ "GenSigAutoGenSnd" SG_ 1441 ND_ErrorTime 1;
BA_ "GenSigSendType" SG_ 1441 ND_ErrorTime 0;
BA_ "GenSigAutoGenDsp" SG_ 1441 ND_ErrorDate 1;
BA_ "GenSigAutoGenSnd" SG_ 1441 ND_ErrorDate 1;
BA_ "GenSigSendType" SG_ 1441 ND_ErrorDate 0;
BA_ "GenSigAutoGenDsp" SG_ 1441 ND_ErrorRestentf 1;
BA_ "GenSigAutoGenSnd" SG_ 1441 ND_ErrorRestentf 1;
BA_ "GenSigSendType" SG_ 1441 ND_ErrorRestentf 0;
BA_ "GenSigAutoGenDsp" SG_ 1441 ND_ErrorHeading 1;
BA_ "GenSigAutoGenSnd" SG_ 1441 ND_ErrorHeading 1;
BA_ "GenSigSendType" SG_ 1441 ND_ErrorHeading 0;
BA_ "GenSigAutoGenDsp" SG_ 1441 ND_ErrorSpeed 1;
BA_ "GenSigAutoGenSnd" SG_ 1441 ND_ErrorSpeed 1;
BA_ "GenSigSendType" SG_ 1441 ND_ErrorSpeed 0;
BA_ "GenSigAutoGenDsp" SG_ 1441 ND_KM 1;
BA_ "GenSigAutoGenSnd" SG_ 1441 ND_KM 1;
BA_ "GenSigSendType" SG_ 1441 ND_KM 0;
BA_ "GenSigAutoGenDsp" SG_ 1441 ND_AMPM 1;
BA_ "GenSigAutoGenSnd" SG_ 1441 ND_AMPM 1;
BA_ "GenSigSendType" SG_ 1441 ND_AMPM 0;
BA_ "GenSigAutoGenDsp" SG_ 1441 ND_Stunde 1;
BA_ "GenSigAutoGenSnd" SG_ 1441 ND_Stunde 1;
BA_ "GenSigSendType" SG_ 1441 ND_Stunde 0;
BA_ "GenSigAutoGenDsp" SG_ 1441 ND_Minuten 1;
BA_ "GenSigAutoGenSnd" SG_ 1441 ND_Minuten 1;
BA_ "GenSigSendType" SG_ 1441 ND_Minuten 0;
BA_ "GenSigAutoGenDsp" SG_ 1441 ND_Sekunden 1;
BA_ "GenSigAutoGenSnd" SG_ 1441 ND_Sekunden 1;
BA_ "GenSigSendType" SG_ 1441 ND_Sekunden 0;
BA_ "GenSigAutoGenDsp" SG_ 1441 ND_Year 1;
BA_ "GenSigAutoGenSnd" SG_ 1441 ND_Year 1;
BA_ "GenSigSendType" SG_ 1441 ND_Year 0;
BA_ "GenSigAutoGenDsp" SG_ 1441 ND_Month 1;
BA_ "GenSigAutoGenSnd" SG_ 1441 ND_Month 1;
BA_ "GenSigSendType" SG_ 1441 ND_Month 0;
BA_ "GenSigAutoGenDsp" SG_ 1441 ND_Day 1;
BA_ "GenSigAutoGenSnd" SG_ 1441 ND_Day 1;
BA_ "GenSigSendType" SG_ 1441 ND_Day 0;
BA_ "GenSigAutoGenDsp" SG_ 1441 ND_Restentfernug 1;
BA_ "GenSigAutoGenSnd" SG_ 1441 ND_Restentfernug 1;
BA_ "GenSigSendType" SG_ 1441 ND_Restentfernug 0;
BA_ "GenSigAutoGenDsp" SG_ 1441 ND_Heading 1;
BA_ "GenSigAutoGenSnd" SG_ 1441 ND_Heading 1;
BA_ "GenSigSendType" SG_ 1441 ND_Heading 0;
BA_ "GenSigAutoGenDsp" SG_ 1441 ND_Speed 1;
BA_ "GenSigAutoGenSnd" SG_ 1441 ND_Speed 1;
BA_ "GenSigSendType" SG_ 1441 ND_Speed 0;
BA_ "GenSigAutoGenDsp" SG_ 673 NV1_Gierrate 1;
BA_ "GenSigAutoGenSnd" SG_ 673 NV1_Gierrate 1;
BA_ "GenSigSendType" SG_ 673 NV1_Gierrate 0;
BA_ "GenSigAutoGenDsp" SG_ 673 NV1_Fehler_Gierrate 1;
BA_ "GenSigAutoGenSnd" SG_ 673 NV1_Fehler_Gierrate 1;
BA_ "GenSigSendType" SG_ 673 NV1_Fehler_Gierrate 0;
BA_ "GenSigAutoGenDsp" SG_ 673 NV1_VZ_Gierrate 1;
BA_ "GenSigAutoGenSnd" SG_ 673 NV1_VZ_Gierrate 1;
BA_ "GenSigSendType" SG_ 673 NV1_VZ_Gierrate 0;
BA_ "GenSigAutoGenDsp" SG_ 673 NV1_Laenderkennung 1;
BA_ "GenSigAutoGenSnd" SG_ 673 NV1_Laenderkennung 1;
BA_ "GenSigSendType" SG_ 673 NV1_Laenderkennung 0;
BA_ "GenSigAutoGenDsp" SG_ 673 NV1_Strassentyp 1;
BA_ "GenSigAutoGenSnd" SG_ 673 NV1_Strassentyp 1;
BA_ "GenSigSendType" SG_ 673 NV1_Strassentyp 0;
BA_ "Fehlerwert" SG_ 673 NV1_Strassentyp 15;
BA_ "GenSigAutoGenDsp" SG_ 673 NV1_Anz_Fahrbahnen 1;
BA_ "GenSigAutoGenSnd" SG_ 673 NV1_Anz_Fahrbahnen 1;
BA_ "GenSigSendType" SG_ 673 NV1_Anz_Fahrbahnen 0;
BA_ "GenSigAutoGenDsp" SG_ 673 NV1_Fehler_Daten 1;
BA_ "GenSigAutoGenSnd" SG_ 673 NV1_Fehler_Daten 1;
BA_ "GenSigSendType" SG_ 673 NV1_Fehler_Daten 0;
BA_ "GenSigAutoGenDsp" SG_ 673 NV1_Kurvenverlauf 1;
BA_ "GenSigAutoGenSnd" SG_ 673 NV1_Kurvenverlauf 1;
BA_ "GenSigSendType" SG_ 673 NV1_Kurvenverlauf 0;
BA_ "GenSigAutoGenDsp" SG_ 673 NV1_Kurvenrichtg 1;
BA_ "GenSigAutoGenSnd" SG_ 673 NV1_Kurvenrichtg 1;
BA_ "GenSigSendType" SG_ 673 NV1_Kurvenrichtg 0;
BA_ "GenSigAutoGenDsp" SG_ 673 NV1_Entf_Kurve 1;
BA_ "GenSigAutoGenSnd" SG_ 673 NV1_Entf_Kurve 1;
BA_ "GenSigSendType" SG_ 673 NV1_Entf_Kurve 0;
BA_ "GenSigAutoGenDsp" SG_ 673 NV1_Entf_Krzg 1;
BA_ "GenSigAutoGenSnd" SG_ 673 NV1_Entf_Krzg 1;
BA_ "GenSigSendType" SG_ 673 NV1_Entf_Krzg 0;
BA_ "GenSigAutoGenDsp" SG_ 673 NV1_Krzg_Typ 1;
BA_ "GenSigAutoGenSnd" SG_ 673 NV1_Krzg_Typ 1;
BA_ "GenSigSendType" SG_ 673 NV1_Krzg_Typ 0;
BA_ "GenSigAutoGenDsp" SG_ 1455 NV2_Reststrecke 1;
BA_ "GenSigAutoGenSnd" SG_ 1455 NV2_Reststrecke 1;
BA_ "GenSigSendType" SG_ 1455 NV2_Reststrecke 0;
BA_ "GenSigAutoGenDsp" SG_ 1455 NV2_Restzeit 1;
BA_ "GenSigAutoGenSnd" SG_ 1455 NV2_Restzeit 1;
BA_ "GenSigSendType" SG_ 1455 NV2_Restzeit 0;
BA_ "GenSigAutoGenDsp" SG_ 1443 NP_Degree 1;
BA_ "GenSigAutoGenSnd" SG_ 1443 NP_Degree 1;
BA_ "GenSigSendType" SG_ 1443 NP_Degree 0;
BA_ "GenSigAutoGenDsp" SG_ 1443 NP_Richtung_NS 1;
BA_ "GenSigAutoGenSnd" SG_ 1443 NP_Richtung_NS 1;
BA_ "GenSigSendType" SG_ 1443 NP_Richtung_NS 0;
BA_ "GenSigAutoGenDsp" SG_ 1443 NP_Minuten_NS 1;
BA_ "GenSigAutoGenSnd" SG_ 1443 NP_Minuten_NS 1;
BA_ "GenSigSendType" SG_ 1443 NP_Minuten_NS 0;
BA_ "GenSigAutoGenDsp" SG_ 1443 NP_MinFraction_NS 1;
BA_ "GenSigAutoGenSnd" SG_ 1443 NP_MinFraction_NS 1;
BA_ "GenSigSendType" SG_ 1443 NP_MinFraction_NS 0;
BA_ "GenSigAutoGenDsp" SG_ 1443 NP_Degree_OW 1;
BA_ "GenSigAutoGenSnd" SG_ 1443 NP_Degree_OW 1;
BA_ "GenSigSendType" SG_ 1443 NP_Degree_OW 0;
BA_ "GenSigAutoGenDsp" SG_ 1443 NP_Richtung_OW 1;
BA_ "GenSigAutoGenSnd" SG_ 1443 NP_Richtung_OW 1;
BA_ "GenSigSendType" SG_ 1443 NP_Richtung_OW 0;
BA_ "GenSigAutoGenDsp" SG_ 1443 NP_Minuten_OW 1;
BA_ "GenSigAutoGenSnd" SG_ 1443 NP_Minuten_OW 1;
BA_ "GenSigSendType" SG_ 1443 NP_Minuten_OW 0;
BA_ "GenSigAutoGenDsp" SG_ 1443 NP_MinFraction_OW 1;
BA_ "GenSigAutoGenSnd" SG_ 1443 NP_MinFraction_OW 1;
BA_ "GenSigSendType" SG_ 1443 NP_MinFraction_OW 0;
BA_ "GenSigAutoGenDsp" SG_ 1443 NP_Fix 1;
BA_ "GenSigAutoGenSnd" SG_ 1443 NP_Fix 1;
BA_ "GenSigSendType" SG_ 1443 NP_Fix 0;
BA_ "GenSigAutoGenDsp" SG_ 1443 NP_GDOP 1;
BA_ "GenSigAutoGenSnd" SG_ 1443 NP_GDOP 1;
BA_ "GenSigSendType" SG_ 1443 NP_GDOP 0;
BA_ "GenSigAutoGenDsp" SG_ 1443 NP_Altitude 1;
BA_ "GenSigAutoGenSnd" SG_ 1443 NP_Altitude 1;
BA_ "GenSigSendType" SG_ 1443 NP_Altitude 0;
BA_ "GenSigAutoGenDsp" SG_ 1071 NMDAB_Receiver 1;
BA_ "GenSigAutoGenSnd" SG_ 1071 NMDAB_Receiver 1;
BA_ "GenSigAutoGenDsp" SG_ 1071 NMDAB_CmdRing 1;
BA_ "GenSigAutoGenSnd" SG_ 1071 NMDAB_CmdRing 1;
BA_ "GenSigAutoGenDsp" SG_ 1071 NMDAB_CmdAlive 1;
BA_ "GenSigAutoGenSnd" SG_ 1071 NMDAB_CmdAlive 1;
BA_ "GenSigAutoGenDsp" SG_ 1071 NMDAB_CmdLimpHome 1;
BA_ "GenSigAutoGenSnd" SG_ 1071 NMDAB_CmdLimpHome 1;
BA_ "GenSigAutoGenDsp" SG_ 1071 NMDAB_SleepInd 1;
BA_ "GenSigAutoGenSnd" SG_ 1071 NMDAB_SleepInd 1;
BA_ "GenSigAutoGenDsp" SG_ 1071 NMDAB_SleepAck 1;
BA_ "GenSigAutoGenSnd" SG_ 1071 NMDAB_SleepAck 1;
BA_ "GenSigAutoGenDsp" SG_ 1071 NMDAB_Kl_30_Reset 1;
BA_ "GenSigAutoGenSnd" SG_ 1071 NMDAB_Kl_30_Reset 1;
BA_ "GenSigAutoGenDsp" SG_ 1071 NMDAB_Fkt_Nachlauf 1;
BA_ "GenSigAutoGenSnd" SG_ 1071 NMDAB_Fkt_Nachlauf 1;
BA_ "GenSigAutoGenDsp" SG_ 1071 NMDAB_NWake 1;
BA_ "GenSigAutoGenSnd" SG_ 1071 NMDAB_NWake 1;
BA_ "GenSigAutoGenDsp" SG_ 1071 NMDAB_CAN 1;
BA_ "GenSigAutoGenSnd" SG_ 1071 NMDAB_CAN 1;
BA_ "GenSigAutoGenDsp" SG_ 1071 NMDAB_Klemme_15 1;
BA_ "GenSigAutoGenSnd" SG_ 1071 NMDAB_Klemme_15 1;
BA_ "GenSigAutoGenDsp" SG_ 1071 NMDAB_WakeUp2 1;
BA_ "GenSigAutoGenSnd" SG_ 1071 NMDAB_WakeUp2 1;
BA_ "GenSigAutoGenDsp" SG_ 1071 NMDAB_WakeUp3 1;
BA_ "GenSigAutoGenSnd" SG_ 1071 NMDAB_WakeUp3 1;
BA_ "GenSigAutoGenDsp" SG_ 1067 NMGW_I_Receiver 1;
BA_ "GenSigAutoGenSnd" SG_ 1067 NMGW_I_Receiver 1;
BA_ "GenSigAutoGenDsp" SG_ 1067 NMGW_I_CmdRing 1;
BA_ "GenSigAutoGenSnd" SG_ 1067 NMGW_I_CmdRing 1;
BA_ "GenSigAutoGenDsp" SG_ 1067 NMGW_I_CmdAlive 1;
BA_ "GenSigAutoGenSnd" SG_ 1067 NMGW_I_CmdAlive 1;
BA_ "GenSigAutoGenDsp" SG_ 1067 NMGW_I_CmdLimpHome 1;
BA_ "GenSigAutoGenSnd" SG_ 1067 NMGW_I_CmdLimpHome 1;
BA_ "GenSigAutoGenDsp" SG_ 1067 NMGW_I_SleepInd 1;
BA_ "GenSigAutoGenSnd" SG_ 1067 NMGW_I_SleepInd 1;
BA_ "GenSigAutoGenDsp" SG_ 1067 NMGW_I_SleepAck 1;
BA_ "GenSigAutoGenSnd" SG_ 1067 NMGW_I_SleepAck 1;
BA_ "GenSigAutoGenDsp" SG_ 1067 NMGW_I_Kl_30_Reset 1;
BA_ "GenSigAutoGenSnd" SG_ 1067 NMGW_I_Kl_30_Reset 1;
BA_ "GenSigAutoGenDsp" SG_ 1067 NMGW_I_Fkt_Nachlauf 1;
BA_ "GenSigAutoGenSnd" SG_ 1067 NMGW_I_Fkt_Nachlauf 1;
BA_ "GenSigAutoGenDsp" SG_ 1067 NMGW_I_NWake 1;
BA_ "GenSigAutoGenSnd" SG_ 1067 NMGW_I_NWake 1;
BA_ "GenSigAutoGenDsp" SG_ 1067 NMGW_I_CAN 1;
BA_ "GenSigAutoGenSnd" SG_ 1067 NMGW_I_CAN 1;
BA_ "GenSigAutoGenDsp" SG_ 1067 NMGW_I_Wake_Up_Ltg 1;
BA_ "GenSigAutoGenSnd" SG_ 1067 NMGW_I_Wake_Up_Ltg 1;
BA_ "GenSigAutoGenDsp" SG_ 1067 NMGW_I_Komfort_CAN 1;
BA_ "GenSigAutoGenSnd" SG_ 1067 NMGW_I_Komfort_CAN 1;
BA_ "GenSigAutoGenDsp" SG_ 1067 NMGW_I_Info_CAN 1;
BA_ "GenSigAutoGenSnd" SG_ 1067 NMGW_I_Info_CAN 1;
BA_ "GenSigAutoGenDsp" SG_ 1067 NMGW_I_Kl_15 1;
BA_ "GenSigAutoGenSnd" SG_ 1067 NMGW_I_Kl_15 1;
BA_ "GenSigAutoGenDsp" SG_ 1067 NMGW_I_Diag_CAN 1;
BA_ "GenSigAutoGenSnd" SG_ 1067 NMGW_I_Diag_CAN 1;
BA_ "GenSigAutoGenDsp" SG_ 1067 NMGW_I_LIN1 1;
BA_ "GenSigAutoGenSnd" SG_ 1067 NMGW_I_LIN1 1;
BA_ "GenSigAutoGenDsp" SG_ 1067 NMGW_I_LIN2 1;
BA_ "GenSigAutoGenSnd" SG_ 1067 NMGW_I_LIN2 1;
BA_ "GenSigAutoGenDsp" SG_ 1067 NMGW_I_WakeUp2 1;
BA_ "GenSigAutoGenSnd" SG_ 1067 NMGW_I_WakeUp2 1;
BA_ "GenSigAutoGenDsp" SG_ 1067 NMGW_I_WakeUp3 1;
BA_ "GenSigAutoGenSnd" SG_ 1067 NMGW_I_WakeUp3 1;
BA_ "GenSigAutoGenDsp" SG_ 1064 NMGSM_Receiver 1;
BA_ "GenSigAutoGenSnd" SG_ 1064 NMGSM_Receiver 1;
BA_ "GenSigAutoGenDsp" SG_ 1064 NMGSM_CmdRing 1;
BA_ "GenSigAutoGenSnd" SG_ 1064 NMGSM_CmdRing 1;
BA_ "GenSigAutoGenDsp" SG_ 1064 NMGSM_CmdAlive 1;
BA_ "GenSigAutoGenSnd" SG_ 1064 NMGSM_CmdAlive 1;
BA_ "GenSigAutoGenDsp" SG_ 1064 NMGSM_CmdLimpHome 1;
BA_ "GenSigAutoGenSnd" SG_ 1064 NMGSM_CmdLimpHome 1;
BA_ "GenSigAutoGenDsp" SG_ 1064 NMGSM_SleepInd 1;
BA_ "GenSigAutoGenSnd" SG_ 1064 NMGSM_SleepInd 1;
BA_ "GenSigAutoGenDsp" SG_ 1064 NMGSM_SleepAck 1;
BA_ "GenSigAutoGenSnd" SG_ 1064 NMGSM_SleepAck 1;
BA_ "GenSigAutoGenDsp" SG_ 1064 NMGSM_Kl_30_Reset 1;
BA_ "GenSigAutoGenSnd" SG_ 1064 NMGSM_Kl_30_Reset 1;
BA_ "GenSigAutoGenDsp" SG_ 1064 NMGSM_Fkt_Nachlauf 1;
BA_ "GenSigAutoGenSnd" SG_ 1064 NMGSM_Fkt_Nachlauf 1;
BA_ "GenSigAutoGenDsp" SG_ 1064 NMGSM_NWake 1;
BA_ "GenSigAutoGenSnd" SG_ 1064 NMGSM_NWake 1;
BA_ "GenSigAutoGenDsp" SG_ 1064 NMGSM_CAN 1;
BA_ "GenSigAutoGenSnd" SG_ 1064 NMGSM_CAN 1;
BA_ "GenSigAutoGenDsp" SG_ 1064 NMGSM_Klemme_15 1;
BA_ "GenSigAutoGenSnd" SG_ 1064 NMGSM_Klemme_15 1;
BA_ "GenSigAutoGenDsp" SG_ 1064 NMGSM_WakeUp2 1;
BA_ "GenSigAutoGenSnd" SG_ 1064 NMGSM_WakeUp2 1;
BA_ "GenSigAutoGenDsp" SG_ 1064 NMGSM_WakeUp3 1;
BA_ "GenSigAutoGenSnd" SG_ 1064 NMGSM_WakeUp3 1;
BA_ "GenSigAutoGenDsp" SG_ 1076 NMKOMP_Receiver 1;
BA_ "GenSigAutoGenSnd" SG_ 1076 NMKOMP_Receiver 1;
BA_ "GenSigAutoGenDsp" SG_ 1076 NMKOMP_CmdRing 1;
BA_ "GenSigAutoGenSnd" SG_ 1076 NMKOMP_CmdRing 1;
BA_ "GenSigAutoGenDsp" SG_ 1076 NMKOMP_CmdAlive 1;
BA_ "GenSigAutoGenSnd" SG_ 1076 NMKOMP_CmdAlive 1;
BA_ "GenSigAutoGenDsp" SG_ 1076 NMKOMP_CmdLimpHome 1;
BA_ "GenSigAutoGenSnd" SG_ 1076 NMKOMP_CmdLimpHome 1;
BA_ "GenSigAutoGenDsp" SG_ 1076 NMKOMP_SleepInd 1;
BA_ "GenSigAutoGenSnd" SG_ 1076 NMKOMP_SleepInd 1;
BA_ "GenSigAutoGenDsp" SG_ 1076 NMKOMP_SleepAck 1;
BA_ "GenSigAutoGenSnd" SG_ 1076 NMKOMP_SleepAck 1;
BA_ "GenSigAutoGenDsp" SG_ 1076 NMKOMP_Kl_30_Reset 1;
BA_ "GenSigAutoGenSnd" SG_ 1076 NMKOMP_Kl_30_Reset 1;
BA_ "GenSigAutoGenDsp" SG_ 1076 NMKOMP_Fkt_Nachlauf 1;
BA_ "GenSigAutoGenSnd" SG_ 1076 NMKOMP_Fkt_Nachlauf 1;
BA_ "GenSigAutoGenDsp" SG_ 1076 NMKOMP_NWake 1;
BA_ "GenSigAutoGenSnd" SG_ 1076 NMKOMP_NWake 1;
BA_ "GenSigAutoGenDsp" SG_ 1076 NMKOMP_CAN 1;
BA_ "GenSigAutoGenSnd" SG_ 1076 NMKOMP_CAN 1;
BA_ "GenSigAutoGenDsp" SG_ 1076 NMKOMP_WakeUp2 1;
BA_ "GenSigAutoGenSnd" SG_ 1076 NMKOMP_WakeUp2 1;
BA_ "GenSigAutoGenDsp" SG_ 1076 NMKOMP_WakeUp3 1;
BA_ "GenSigAutoGenSnd" SG_ 1076 NMKOMP_WakeUp3 1;
BA_ "GenSigAutoGenDsp" SG_ 1084 NMSBS_Receiver 1;
BA_ "GenSigAutoGenSnd" SG_ 1084 NMSBS_Receiver 1;
BA_ "GenSigAutoGenDsp" SG_ 1084 NMSBS_CmdRing 1;
BA_ "GenSigAutoGenSnd" SG_ 1084 NMSBS_CmdRing 1;
BA_ "GenSigAutoGenDsp" SG_ 1084 NMSBS_CmdAlive 1;
BA_ "GenSigAutoGenSnd" SG_ 1084 NMSBS_CmdAlive 1;
BA_ "GenSigAutoGenDsp" SG_ 1084 NMSBS_CmdLimpHome 1;
BA_ "GenSigAutoGenSnd" SG_ 1084 NMSBS_CmdLimpHome 1;
BA_ "GenSigAutoGenDsp" SG_ 1084 NMSBS_SleepInd 1;
BA_ "GenSigAutoGenSnd" SG_ 1084 NMSBS_SleepInd 1;
BA_ "GenSigAutoGenDsp" SG_ 1084 NMSBS_SleepAck 1;
BA_ "GenSigAutoGenSnd" SG_ 1084 NMSBS_SleepAck 1;
BA_ "GenSigAutoGenDsp" SG_ 1084 NMSBS_Kl_30_Reset 1;
BA_ "GenSigAutoGenSnd" SG_ 1084 NMSBS_Kl_30_Reset 1;
BA_ "GenSigAutoGenDsp" SG_ 1084 NMSBS_Fkt_Nachlauf 1;
BA_ "GenSigAutoGenSnd" SG_ 1084 NMSBS_Fkt_Nachlauf 1;
BA_ "GenSigAutoGenDsp" SG_ 1084 NMSBS_NWake 1;
BA_ "GenSigAutoGenSnd" SG_ 1084 NMSBS_NWake 1;
BA_ "GenSigAutoGenDsp" SG_ 1084 NMSBS_CAN 1;
BA_ "GenSigAutoGenSnd" SG_ 1084 NMSBS_CAN 1;
BA_ "GenSigAutoGenDsp" SG_ 1084 NMSBS_Klemme_15 1;
BA_ "GenSigAutoGenSnd" SG_ 1084 NMSBS_Klemme_15 1;
BA_ "GenSigAutoGenDsp" SG_ 1084 NMSBS_WakeUp2 1;
BA_ "GenSigAutoGenSnd" SG_ 1084 NMSBS_WakeUp2 1;
BA_ "GenSigAutoGenDsp" SG_ 1084 NMSBS_WakeUp3 1;
BA_ "GenSigAutoGenSnd" SG_ 1084 NMSBS_WakeUp3 1;
BA_ "GenSigAutoGenDsp" SG_ 1063 NMSHI_Receiver 1;
BA_ "GenSigAutoGenSnd" SG_ 1063 NMSHI_Receiver 1;
BA_ "GenSigAutoGenDsp" SG_ 1063 NMSHI_CmdRing 1;
BA_ "GenSigAutoGenSnd" SG_ 1063 NMSHI_CmdRing 1;
BA_ "GenSigAutoGenDsp" SG_ 1063 NMSHI_CmdAlive 1;
BA_ "GenSigAutoGenSnd" SG_ 1063 NMSHI_CmdAlive 1;
BA_ "GenSigAutoGenDsp" SG_ 1063 NMSHI_CmdLimpHome 1;
BA_ "GenSigAutoGenSnd" SG_ 1063 NMSHI_CmdLimpHome 1;
BA_ "GenSigAutoGenDsp" SG_ 1063 NMSHI_SleepInd 1;
BA_ "GenSigAutoGenSnd" SG_ 1063 NMSHI_SleepInd 1;
BA_ "GenSigAutoGenDsp" SG_ 1063 NMSHI_SleepAck 1;
BA_ "GenSigAutoGenSnd" SG_ 1063 NMSHI_SleepAck 1;
BA_ "GenSigAutoGenDsp" SG_ 1063 NMSHI_Kl_30_Reset 1;
BA_ "GenSigAutoGenSnd" SG_ 1063 NMSHI_Kl_30_Reset 1;
BA_ "GenSigAutoGenDsp" SG_ 1063 NMSHI_Fkt_Nachlauf 1;
BA_ "GenSigAutoGenSnd" SG_ 1063 NMSHI_Fkt_Nachlauf 1;
BA_ "GenSigAutoGenDsp" SG_ 1063 NMSHI_NWake 1;
BA_ "GenSigAutoGenSnd" SG_ 1063 NMSHI_NWake 1;
BA_ "GenSigAutoGenDsp" SG_ 1063 NMSHI_CAN 1;
BA_ "GenSigAutoGenSnd" SG_ 1063 NMSHI_CAN 1;
BA_ "GenSigAutoGenDsp" SG_ 1063 NMSHI_Funk 1;
BA_ "GenSigAutoGenSnd" SG_ 1063 NMSHI_Funk 1;
BA_ "GenSigAutoGenDsp" SG_ 1063 NMSHI_Geblaese 1;
BA_ "GenSigAutoGenSnd" SG_ 1063 NMSHI_Geblaese 1;
BA_ "GenSigAutoGenDsp" SG_ 1063 NMSHI_Fehlerabschaltung 1;
BA_ "GenSigAutoGenSnd" SG_ 1063 NMSHI_Fehlerabschaltung 1;
BA_ "GenSigAutoGenDsp" SG_ 1063 NMSHI_Vorlauf_S_A 1;
BA_ "GenSigAutoGenSnd" SG_ 1063 NMSHI_Vorlauf_S_A 1;
BA_ "GenSigAutoGenDsp" SG_ 1063 NMSHI_WakeUp2 1;
BA_ "GenSigAutoGenSnd" SG_ 1063 NMSHI_WakeUp2 1;
BA_ "GenSigAutoGenDsp" SG_ 1063 NMSHI_WakeUp3 1;
BA_ "GenSigAutoGenSnd" SG_ 1063 NMSHI_WakeUp3 1;
BA_ "GenSigAutoGenDsp" SG_ 1062 NMTASTATUR_Receiver 1;
BA_ "GenSigAutoGenSnd" SG_ 1062 NMTASTATUR_Receiver 1;
BA_ "GenSigAutoGenDsp" SG_ 1062 NMTASTATUR_CmdRing 1;
BA_ "GenSigAutoGenSnd" SG_ 1062 NMTASTATUR_CmdRing 1;
BA_ "GenSigAutoGenDsp" SG_ 1062 NMTASTATUR_CmdAlive 1;
BA_ "GenSigAutoGenSnd" SG_ 1062 NMTASTATUR_CmdAlive 1;
BA_ "GenSigAutoGenDsp" SG_ 1062 NMTASTATUR_CmdLimpHome 1;
BA_ "GenSigAutoGenSnd" SG_ 1062 NMTASTATUR_CmdLimpHome 1;
BA_ "GenSigAutoGenDsp" SG_ 1062 NMTASTATUR_SleepInd 1;
BA_ "GenSigAutoGenSnd" SG_ 1062 NMTASTATUR_SleepInd 1;
BA_ "GenSigAutoGenDsp" SG_ 1062 NMTASTATUR_SleepAck 1;
BA_ "GenSigAutoGenSnd" SG_ 1062 NMTASTATUR_SleepAck 1;
BA_ "GenSigAutoGenDsp" SG_ 1062 NMTASTATUR_Kl_30_Reset 1;
BA_ "GenSigAutoGenSnd" SG_ 1062 NMTASTATUR_Kl_30_Reset 1;
BA_ "GenSigAutoGenDsp" SG_ 1062 NMTASTATUR_Fkt_Nachlauf 1;
BA_ "GenSigAutoGenSnd" SG_ 1062 NMTASTATUR_Fkt_Nachlauf 1;
BA_ "GenSigAutoGenDsp" SG_ 1062 NMTASTATUR_NWake 1;
BA_ "GenSigAutoGenSnd" SG_ 1062 NMTASTATUR_NWake 1;
BA_ "GenSigAutoGenDsp" SG_ 1062 NMTASTATUR_CAN 1;
BA_ "GenSigAutoGenSnd" SG_ 1062 NMTASTATUR_CAN 1;
BA_ "GenSigAutoGenDsp" SG_ 1062 NMTASTATUR_Klemme_15 1;
BA_ "GenSigAutoGenSnd" SG_ 1062 NMTASTATUR_Klemme_15 1;
BA_ "GenSigAutoGenDsp" SG_ 1062 NMTASTATUR_Betaetigung 1;
BA_ "GenSigAutoGenSnd" SG_ 1062 NMTASTATUR_Betaetigung 1;
BA_ "GenSigAutoGenDsp" SG_ 1062 NMTASTATUR_WakeUp2 1;
BA_ "GenSigAutoGenSnd" SG_ 1062 NMTASTATUR_WakeUp2 1;
BA_ "GenSigAutoGenDsp" SG_ 1062 NMTASTATUR_WakeUp3 1;
BA_ "GenSigAutoGenSnd" SG_ 1062 NMTASTATUR_WakeUp3 1;
BA_ "GenSigAutoGenDsp" SG_ 1085 NMTM_I_Receiver 1;
BA_ "GenSigAutoGenSnd" SG_ 1085 NMTM_I_Receiver 1;
BA_ "GenSigAutoGenDsp" SG_ 1085 NMTM_I_CmdRing 1;
BA_ "GenSigAutoGenSnd" SG_ 1085 NMTM_I_CmdRing 1;
BA_ "GenSigAutoGenDsp" SG_ 1085 NMTM_I_CmdAlive 1;
BA_ "GenSigAutoGenSnd" SG_ 1085 NMTM_I_CmdAlive 1;
BA_ "GenSigAutoGenDsp" SG_ 1085 NMTM_I_CmdLimpHome 1;
BA_ "GenSigAutoGenSnd" SG_ 1085 NMTM_I_CmdLimpHome 1;
BA_ "GenSigAutoGenDsp" SG_ 1085 NMTM_I_SleepInd 1;
BA_ "GenSigAutoGenSnd" SG_ 1085 NMTM_I_SleepInd 1;
BA_ "GenSigAutoGenDsp" SG_ 1085 NMTM_I_SleepAck 1;
BA_ "GenSigAutoGenSnd" SG_ 1085 NMTM_I_SleepAck 1;
BA_ "GenSigAutoGenDsp" SG_ 1085 NMTM_I_Kl_30_Reset 1;
BA_ "GenSigAutoGenSnd" SG_ 1085 NMTM_I_Kl_30_Reset 1;
BA_ "GenSigAutoGenDsp" SG_ 1085 NMTM_I_Fkt_Nachlauf 1;
BA_ "GenSigAutoGenSnd" SG_ 1085 NMTM_I_Fkt_Nachlauf 1;
BA_ "GenSigAutoGenDsp" SG_ 1085 NMTM_I_NWake 1;
BA_ "GenSigAutoGenSnd" SG_ 1085 NMTM_I_NWake 1;
BA_ "GenSigAutoGenDsp" SG_ 1085 NMTM_I_CAN 1;
BA_ "GenSigAutoGenSnd" SG_ 1085 NMTM_I_CAN 1;
BA_ "GenSigAutoGenDsp" SG_ 1085 NMTM_I_inCall 1;
BA_ "GenSigAutoGenSnd" SG_ 1085 NMTM_I_inCall 1;
BA_ "GenSigAutoGenDsp" SG_ 1085 NMTM_I_f_diag 1;
BA_ "GenSigAutoGenSnd" SG_ 1085 NMTM_I_f_diag 1;
BA_ "GenSigAutoGenDsp" SG_ 1085 NMTM_I_Klemme_15 1;
BA_ "GenSigAutoGenSnd" SG_ 1085 NMTM_I_Klemme_15 1;
BA_ "GenSigAutoGenDsp" SG_ 1085 NMTM_I_WakeUp2 1;
BA_ "GenSigAutoGenSnd" SG_ 1085 NMTM_I_WakeUp2 1;
BA_ "GenSigAutoGenDsp" SG_ 1085 NMTM_I_WakeUp3 1;
BA_ "GenSigAutoGenSnd" SG_ 1085 NMTM_I_WakeUp3 1;
VAL_ 963 LW1_Vorzeichen 1 "negatives_Vorzeichen" 0 "positives_Vorzeichen" ;
VAL_ 963 LW1_Geschw_Vorzeichen 1 "negatives_Vorzeichen" 0 "positives_Vorzeichen" ;
VAL_ 963 LW1_ID 128 "kalibriert" 0 "noch_nicht_kalibriert" ;
VAL_ 963 LW1_Quelle_Init 0 "Bremse_3" 1 "EPS_Bit" ;
VAL_ 963 LW1_Int_Status 2 "sporadischer_Fehler" 3 "dauerhafter_Fehler" 1 "no_init" 0 "ok" ;
VAL_ 963 LW1_KL30_Ausfall 0 "ok" 1 "no_init_s" ;
VAL_ 1329 LIA_Standlicht 1 "Kl58_ein" ;
VAL_ 1329 LIA_Abblendlicht 1 "Kl56b_ein" 0 "aus" ;
VAL_ 1329 LIA_Fernlicht 1 "Kl56a_ein" 0 "aus" ;
VAL_ 1329 LIA_Nebellicht 1 "Kl83a_ein" 0 "aus" ;
VAL_ 1329 LIA_Nebelschluss 1 "Kl83b_ein" 0 "aus" ;
VAL_ 1329 LIA_Rueckfahrlicht 1 "Rueckfahrlicht_ein" ;
VAL_ 1329 LIA_Parklicht_links 1 "Parklicht_L_ein" ;
VAL_ 1329 LIA_Parklicht_rechts 1 "Parklicht_R_ein" ;
VAL_ 1329 LIA_Blk_links 1 "Blinklampe_L_ein" ;
VAL_ 1329 LIA_Blk_rechts 1 "Blinklampe_R_ein" ;
VAL_ 1329 LIA_Anhaenger 1 "Anhaengerblinken_ein" ;
VAL_ 1329 LIA_Warnblink 1 "Warnblinken_ein" ;
VAL_ 1329 LIA_BLK_Frequenz 1 "Blink_freq_ein" ;
VAL_ 1329 LIA_AFL_Schalter 1 "AFL_Schalter_ein" 0 "aus" ;
VAL_ 1329 LIA_Bremslicht 1 "Bremslicht_ein" 0 "aus" ;
VAL_ 1329 LIA_Tagesfahrlicht 1 "Tagfahrlicht_ein" ;
VAL_ 1329 LIA_Blk_L_Kontrolle 1 "Kontrolllampe_Blk_L_ein" ;
VAL_ 1329 LIA_Blk_R_Kontrolle 1 "Kontrolllampe_Blk_R_ein" ;
VAL_ 1329 LIA_Kurv_Licht 1 "Kurvenlicht_ein" ;
VAL_ 1329 LIA_Warnblk_Status 1 "Warnblinkstatus_ein" ;
VAL_ 705 LS1_Blk_links 0 "aus" 1 "aktiviert" ;
VAL_ 705 LS1_Blk_rechts 0 "aus" 1 "aktiviert" ;
VAL_ 705 LS1_Fernlicht 0 "Fernlichtschalter_aus" 1 "Fernlichtschalter_ein" ;
VAL_ 705 LS1_Heckintervall 1 "Heckintervall_ein" 0 "kein_Heckintervall_Wischen" ;
VAL_ 705 LS1_KD_Fehler 1 "Fehlerspeichereintrag" 0 "kein_Fehlerspeichereintrag" ;
VAL_ 705 LS1_ELV_enable 0 "ELV_entriegeln" 1 "ELV_verriegeln" ;
VAL_ 705 LS1_def_ELV_Enable 0 "ELV_Enable_OK" 1 "ELV_Enable_defekt" ;
VAL_ 705 LS1_def_P_Verriegelt 1 "defekt" 0 "OK" ;
VAL_ 705 LS1_MFL_Typ 0 "MFL_Low_Bedienkonzept_alt" 1 "MFL_High_Bedienkonzept_Neu" ;
VAL_ 705 LS1_P_verriegelt 0 "P_Position" 1 "Waehlhebel_ausserhalb_Park_Position" ;
VAL_ 705 LS1_FAS_Taster 1 "Betaetigt" 0 "Unbetaetigt" ;
VAL_ 705 LS1_Fehler_FAS_Taster 0 "kein_Fehler" 1 "Fehler" ;
VAL_ 705 LS1_Fehler_Vibration 0 "kein_Fehler" 1 "Fehler" ;
VAL_ 1371 MD1_MDI_Error_flag 1 "Fehlerspeichereintrag" 0 "kein_Fehlerspeichereintrag" ;
VAL_ 1317 SHM_Restdauer 127 "Fehler" ;
VAL_ 1473 MLT_DW_VZ 1 "negatives_Vorzeichen" 0 "positives_Vorzeichen" ;
VAL_ 1473 MLT_Tickzaehler_1 0 "Reset" ;
VAL_ 1473 MLT_Tickzaehler_2 0 "Reset" ;
VAL_ 1365 MO7_LL_Status 1 "LLDZ_hat_Wert_1_Stufe_erreicht" 0 "keine_Anf_einer_erhoehten_LL_DZ" ;
VAL_ 1365 MO7_V_Begrenz 0 "V_Begrenzung_nicht_moeglich" 1 "V_Begrenzung_moeglich" ;
VAL_ 1365 MO7_V_Begr_akt 0 "inaktiv" 1 "aktiv" ;
VAL_ 1365 MO7_FehlerSp 1 "Fehlerspeichereintrag" 0 "kein_Fehlerspeichereintrag" ;
VAL_ 1365 MO7_Fehler_Oel_Temp 0 "iO" 1 "n_iO" ;
VAL_ 1365 MO7_DFM 255 "Fehler" ;
VAL_ 1365 MO7_Hoeheninfo 255 "Fehler" ;
VAL_ 1365 MO7_Gradient_Drehz 127 "ist_groessergleich_127_min" ;
VAL_ 1365 MO7_Gradient_Vorz 1 "negatives_Vorzeichen" 0 "positives_Vorzeichen" ;
VAL_ 1365 MO7_Ladedruckneu 255 "Fehler" ;
VAL_ 1365 MO7_PTC_bereit 0 "kein_3stuf_PTC_verbaut" ;
VAL_ 1365 MO7_Mot_weckfaehig 1 "Wecken_ACAN_gef" 0 "kein_Wecken_ACAN" ;
VAL_ 1365 MO7_Zus_Kuehl 1 "ja" 0 "nein" ;
VAL_ 1365 MO7_Sleep_Ind 0 "CAN_wird_benoetigt" 1 "Sleep_bereit" ;
VAL_ 1365 MO7_Rueck_LLDz 0 "keine_Anf_einer_erhoehten_LL_DZ" 1 "LLDZ_hat_Wert_2_Stufe_erreicht" ;
VAL_ 1365 MO7_Last_abwurf 3 "Stufe_3" 2 "Stufe_2" 0 "Stufe_0" 1 "Stufe_1" ;
VAL_ 1365 MO7_Ein_Generator 1 "Generator_ein" 0 "Generator_aus" ;
VAL_ 1365 MO7_Lastabwurf_Heiz 0 "Hochleistungsheizsys_deaktiviert" 1 "Hochleistungsheizsys_aktivierbar" ;
VAL_ 1365 MO7_Stat_Gluehk 15 "Fehler" ;
VAL_ 1365 MO7_Oeltemperatur 1 "Init" 0 "nicht_verbaut" 255 "Fehler" ;
VAL_ 1420 M10_Anzeige 2 "Systemfehler_Start_Stopp" 12 "Motor_startet" 13 "Kupplung_betaetigt" 0 "keine_Anzeige" 1 "Start_Stopp_aktiv" 15 "Bremse_treten" 14 "WH_in_P_N" 3 "Motor_manuell_starten" 5 "Motorlauf_noetig" 9 "Unerwuenschter_Motorstillstand" ;
VAL_ 1420 M10_Anf_Kl75 0 "Anf_Kl75_ausschalten" 1 "Anf_Kl75_einschalten" ;
VAL_ 1420 MSG_Remotestart_Betrieb 1 "RS_Betrieb" 0 "kein_RS_Betrieb" ;
VAL_ 1420 M10_SpannungsAnf 0 "keine_Anforderung" 1 "Anforderung" ;
VAL_ 1420 M10_UDruckDyn 1 "Dyn_immer_kleiner_50mbar" 0 "Dyn_1mal_groesser_50mbar" ;
VAL_ 1420 M10_Status_StSt 0 "System_in_diesem_KL15_Zyklus_nicht_verfuegbar" 1 "System_aktiv_keine_Freigabe_durch_StartStop_Koordinator" 2 "System_aktiv_alle Freigaben_liegen_vor" 3 "System_aktiv_mindestens_eine_Freigabe_fehlt" ;
VAL_ 1420 M10_MotorStopp 0 "Motor_Stopp_inaktiv" 1 "Motor_Stopp_aktiv" ;
VAL_ 1420 M10_Wiederstart 0 "Wiederstart_inaktiv" 1 "Wiederstart_aktiv" ;
VAL_ 1420 M10_Schubabschaltung 0 "keine_Schubabsch" 1 "Schubabschaltung" ;
VAL_ 1420 M10_Druck_err_gem 1 "gemessen" 0 "errechnet" ;
VAL_ 1420 M10_Freigabe_Reku 3 "RekuModus_aktiv" 0 "RekuModus_aus" 2 "Empf_U_Absenkung" 1 "Empf_U_Anhebung" ;
VAL_ 1420 M10_rel_Saugrohrdruck 63 "Fehler_nicht_verf" ;
VAL_ 1420 M10_Fahrbereitschaft 0 "nicht_fahrbereit" 1 "fahrbereit" ;
VAL_ 1420 M10_Hybrid 0 "kein_Hybrid" 1 "Hybrid" ;
VAL_ 1420 M10_EM_aktiv 0 "EM_inaktiv" 1 "EM_aktiv" ;
VAL_ 1420 M10_VM_aktiv 0 "VM_inaktiv" 1 "VM_aktiv" ;
VAL_ 1420 M10_HYB_Bereitlampe 1 "Lampe_ein" 0 "Lampe_aus" ;
VAL_ 1420 M10_HYB_Warnlampe 1 "Lampe_ein" 0 "Lampe_aus" ;
VAL_ 1420 M10_HYB_Fehlerlampe 1 "Lampe_ein" 0 "Lampe_aus" ;
VAL_ 1420 M10_Fehler_HV_Netz 0 "iO" 1 "kein_gen_Betrieb_moegl" ;
VAL_ 1420 M10_EKlKomLeiRed 0 "keine_LeistBegr" 1 "LeistBegr_75" 2 "LeistBegr_50" 3 "LeistBegr_25" ;
VAL_ 1420 M10_Klimadruck 254 "Init" 255 "Fehler" ;
VAL_ 1420 M10_KompAusCode 4 "MotManagem_12" 2 "Niederdruck_3" 3 "Aussentemp_8" 1 "Hochdruck_1" 6 "Ueberspg_13" 0 "keine" 7 "Unterspg_10" 5 "HD_Sensor_def_17" ;
VAL_ 1420 M10_StartStopp_Fahrerwunsch 0 "Init" 1 "Stoppverbot_durch_Fahrer" 3 "Stoppanforderung_durch_Fahrer" 2 "Stoppfreigabe_durch_Fahrer" ;
VAL_ 1420 M10_Akustik 2 "Akustik_2" 3 "frei" 0 "keine_Akustik" 1 "Akustik_1" ;
VAL_ 1420 M10_Text_1_Hybrid 1 "Text_1" 0 "kein_Text" ;
VAL_ 1420 M10_Text_2_Hybrid 1 "Text_2" 0 "kein_Text" ;
VAL_ 1420 M10_Text_3_Hybrid 0 "kein_Text" 1 "Text_3" ;
VAL_ 1420 M10_Text_4_Hybrid 1 "Text_4" 0 "kein_Text" ;
VAL_ 1420 M10_Text_5_Hybrid 0 "kein_Text" 1 "Text_5" ;
VAL_ 1420 M10_Text_6_Hybrid 0 "kein_Text" ;
VAL_ 1420 M10_Text_7_Hybrid 0 "kein_Text" ;
VAL_ 1420 M10_Text_8_Hybrid 0 "kein_Text" ;
VAL_ 1420 M10_ShiftLockLampe 1 "Lampe_ein" 0 "Lampe_aus" ;
VAL_ 1420 M10_BMSInfo_gue 1 "gueltig" 0 "nicht_gueltig_od_alt" ;
VAL_ 1420 M10_VentilationReq 1 "Umluftklappe_oeffnen" 0 "Umluftklappe_nicht_oeffnen" ;
VAL_ 1420 M10_BattFanSpd 15 "Fehler" ;
VAL_ 1540 NV1_NAV_Error_flag 1 "Fehlerspeichereintrag" 0 "kein_Fehlerspeichereintrag" ;
VAL_ 673 NV1_Gierrate 16383 "ungueltig" ;
VAL_ 673 NV1_Strassentyp 15 "Fehler" ;
VAL_ 673 NV1_Anz_Fahrbahnen 0 "Fehler" ;
